VERSION ""

NS_ :

BS_:

BU_: VMCU VGGSECUSystem TECU OBDScanT2 HMIIOM EMS ECUspare2 ECUspare1 DACU CIOM BBM

BO_ 2671835728 XCP_FA_50_BB2: 8 DACU
 SG_ XCP_FA_50 : 0|64@1+ (1,0) [0|0] "" Vector__XXX

BO_ 2671792378 XCP_50_FA_BB2: 8 Vector__XXX
 SG_ XCP_50_FA : 0|64@1+ (1,0) [0|0] ""  DACU

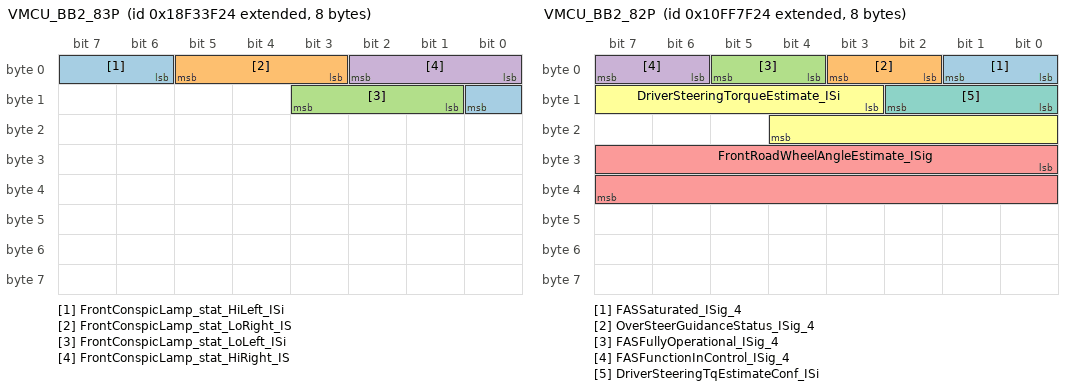
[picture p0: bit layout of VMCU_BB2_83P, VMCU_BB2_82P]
BO_ 2566078244 VMCU_BB2_83P: 8 VMCU
 SG_ FrontConspicLamp_stat_HiLeft_ISi : 6|3@1+ (1,0) [0|0] ""  HMIIOM
 SG_ FrontConspicLamp_stat_LoRight_IS : 3|3@1+ (1,0) [0|0] ""  HMIIOM
 SG_ FrontConspicLamp_stat_LoLeft_ISi : 9|3@1+ (1,0) [0|0] ""  HMIIOM
 SG_ FrontConspicLamp_stat_HiRight_IS : 0|3@1+ (1,0) [0|0] ""  HMIIOM

BO_ 2432663332 VMCU_BB2_82P: 8 VMCU
 SG_ FASSaturated_ISig_4 : 0|2@1+ (1,0) [0|0] ""  DACU
 SG_ OverSteerGuidanceStatus_ISig_4 : 2|2@1+ (1,0) [0|0] ""  HMIIOM
 SG_ FASFullyOperational_ISig_4 : 4|2@1+ (1,0) [0|0] ""  BBM,DACU
 SG_ FASFunctionInControl_ISig_4 : 6|2@1+ (1,0) [0|0] ""  DACU
 SG_ FrontRoadWheelAngleEstimate_ISig : 24|16@1+ (5E-005,-1.6) [-1.6|1.67675] "rad"  DACU
 SG_ DriverSteeringTorqueEstimate_ISi : 11|10@1+ (0.05,-25) [-25|26.15] "Nm"  DACU
 SG_ DriverSteeringTqEstimateConf_ISi : 8|3@1+ (1,0) [0|0] ""  DACU

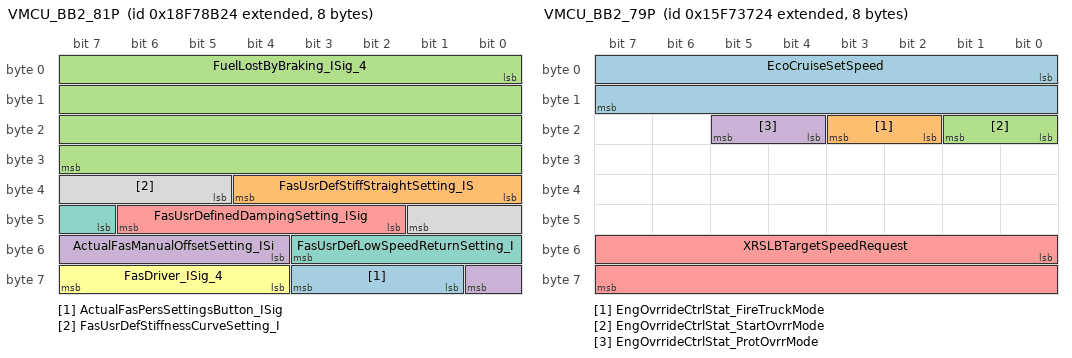
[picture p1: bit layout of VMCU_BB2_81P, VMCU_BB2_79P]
BO_ 2566359844 VMCU_BB2_81P: 8 VMCU
 SG_ ActualFasPersSettingsButton_ISig : 57|3@1+ (1,0) [0|0] ""  HMIIOM
 SG_ FasUsrDefStiffStraightSetting_IS : 32|5@1+ (1,-10) [-10|21] ""  HMIIOM
 SG_ FuelLostByBraking_ISig_4 : 0|32@1+ (0.01,0) [0|42949672.95] "l"  HMIIOM
 SG_ ActualFasManualOffsetSetting_ISi : 52|5@1+ (1,-10) [-10|21] ""  HMIIOM
 SG_ FasUsrDefinedDampingSetting_ISig : 42|5@1+ (1,-10) [-10|21] ""  HMIIOM
 SG_ FasDriver_ISig_4 : 60|4@1+ (1,0) [0|0] ""  HMIIOM
 SG_ FasUsrDefLowSpeedReturnSetting_I : 47|5@1+ (1,-10) [-10|21] ""  HMIIOM
 SG_ FasUsrDefStiffnessCurveSetting_I : 37|5@1+ (1,-10) [-10|21] ""  HMIIOM

BO_ 2481984804 VMCU_BB2_80P: 8 VMCU
 SG_ PS_PosLightDoorOpen_ISig_4 : 10|2@1+ (1,0) [0|0] ""  HMIIOM
 SG_ PS_FogLightRear_ISig_4 : 24|2@1+ (1,0) [0|0] ""  HMIIOM
 SG_ TrailerBodyLampDI_stat : 2|2@1+ (1,0) [0|0] ""  CIOM
 SG_ ParkedLoadDistribution_ISig_4 : 20|3@1+ (1,0) [0|0] ""  HMIIOM
 SG_ PV_HeadLightLevel_ISig_4 : 16|4@1+ (1,-7) [-7|8] "NotApplicable"  HMIIOM
 SG_ TrailerBodyLampFdbk_stat : 0|2@1+ (1,0) [0|0] ""  CIOM
 SG_ PS_FogLightFront_ISig_4 : 26|2@1+ (1,0) [0|0] ""  HMIIOM
 SG_ DriverCrank_rqst_ISig_4 : 12|2@1+ (1,0) [0|0] ""  HMIIOM
 SG_ PS_HeadLightAdjustment_ISig_4 : 8|2@1+ (1,0) [0|0] ""  HMIIOM
 SG_ PS_MainBeam_ISig_4 : 14|2@1+ (1,0) [0|0] ""  HMIIOM
 SG_ FifthWheelHandleLock_ind_ISig_4 : 6|2@1+ (1,0) [0|0] ""  HMIIOM
 SG_ InstFuel_ConsumpValue_ISig_4 : 28|16@1+ (0.01,0) [0|655.35] ""  HMIIOM
 SG_ InstFuel_VehicleMoving_ISig_4 : 44|2@1+ (1,0) [0|0] ""  HMIIOM
 SG_ PS_AFSAllowedInDriveP_ISig_4 : 49|2@1+ (1,0) [0|0] ""  HMIIOM
 SG_ PS_AFS_ISig_4 : 46|3@1+ (1,0) [0|0] ""  HMIIOM
 SG_ AC2CoolingFanControl_rqst : 4|2@1+ (1,0) [0|0] ""  CIOM
 SG_ DHCStatus : 53|2@1+ (1,0) [0|0] ""  HMIIOM
 SG_ PS_PositionLight_ISig_4 : 51|2@1+ (1,0) [0|0] ""  HMIIOM

BO_ 2516006692 VMCU_BB2_79P: 8 VMCU
 SG_ EcoCruiseSetSpeed : 0|16@1+ (0.00390625,0) [0|255.99609375] "Km_per_h"  HMIIOM
 SG_ EngOvrrideCtrlStat_FireTruckMode : 18|2@1+ (1,0) [0|0] ""  EMS
 SG_ EngOvrrideCtrlStat_StartOvrrMode : 16|2@1+ (1,0) [0|0] ""  EMS
 SG_ EngOvrrideCtrlStat_ProtOvrrMode : 20|2@1+ (1,0) [0|0] ""  EMS
 SG_ XRSLBTargetSpeedRequest : 48|16@1+ (0.00390625,0) [0|255.99609375] "Km_per_h"  EMS,TECU

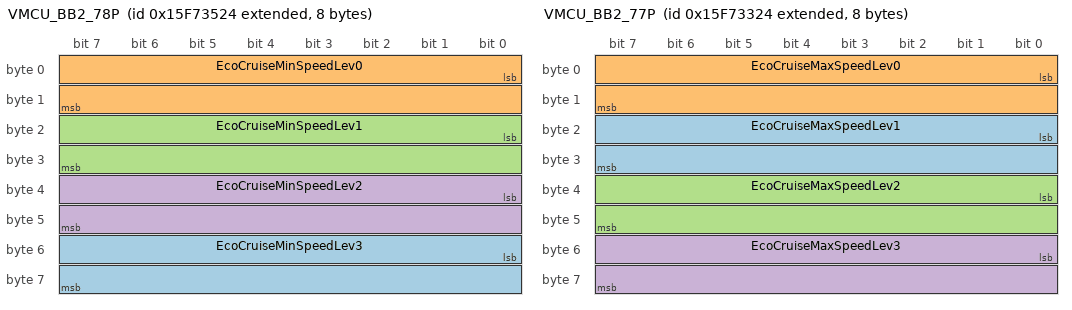
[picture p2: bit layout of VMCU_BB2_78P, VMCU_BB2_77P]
BO_ 2516006180 VMCU_BB2_78P: 8 VMCU
 SG_ EcoCruiseMinSpeedLev3 : 48|16@1+ (0.00390625,0) [0|255.99609375] "Km_per_h"  HMIIOM
 SG_ EcoCruiseMinSpeedLev0 : 0|16@1+ (0.00390625,0) [0|255.99609375] "Km_per_h"  HMIIOM
 SG_ EcoCruiseMinSpeedLev1 : 16|16@1+ (0.00390625,0) [0|255.99609375] "Km_per_h"  HMIIOM
 SG_ EcoCruiseMinSpeedLev2 : 32|16@1+ (0.00390625,0) [0|255.99609375] "Km_per_h"  HMIIOM

BO_ 2516005668 VMCU_BB2_77P: 8 VMCU
 SG_ EcoCruiseMaxSpeedLev1 : 16|16@1+ (0.00390625,0) [0|255.99609375] "Km_per_h"  HMIIOM
 SG_ EcoCruiseMaxSpeedLev0 : 0|16@1+ (0.00390625,0) [0|255.99609375] "Km_per_h"  HMIIOM
 SG_ EcoCruiseMaxSpeedLev2 : 32|16@1+ (0.00390625,0) [0|255.99609375] "Km_per_h"  HMIIOM
 SG_ EcoCruiseMaxSpeedLev3 : 48|16@1+ (0.00390625,0) [0|255.99609375] "Km_per_h"  HMIIOM

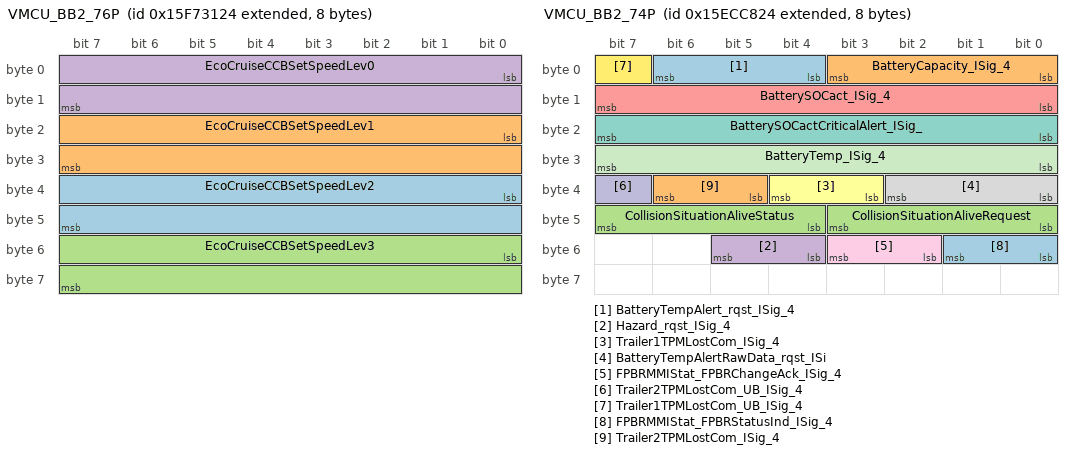
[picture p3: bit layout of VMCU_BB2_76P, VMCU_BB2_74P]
BO_ 2516005156 VMCU_BB2_76P: 8 VMCU
 SG_ EcoCruiseCCBSetSpeedLev2 : 32|16@1+ (0.00390625,0) [0|255.99609375] "Km_per_h"  HMIIOM
 SG_ EcoCruiseCCBSetSpeedLev1 : 16|16@1+ (0.00390625,0) [0|255.99609375] "Km_per_h"  HMIIOM
 SG_ EcoCruiseCCBSetSpeedLev3 : 48|16@1+ (0.00390625,0) [0|255.99609375] "Km_per_h"  HMIIOM
 SG_ EcoCruiseCCBSetSpeedLev0 : 0|16@1+ (0.00390625,0) [0|255.99609375] "Km_per_h"  HMIIOM

BO_ 2566359332 VMCU_BB2_75P: 8 VMCU
 SG_ EngineGreenAreaOutLNG_ISig_4 : 32|32@1+ (0.01,0) [0|42949672.95] "kg"  HMIIOM
 SG_ EngineGreenAreaLNG_ISig_4 : 0|32@1+ (0.01,0) [0|42949672.95] "kg"  HMIIOM

BO_ 2515322916 VMCU_BB2_74P: 8 VMCU
 SG_ BatteryTempAlert_rqst_ISig_4 : 4|3@1+ (1,0) [0|0] ""  HMIIOM
 SG_ BatteryCapacity_ISig_4 : 0|4@1+ (1,0) [0|0] ""  HMIIOM
 SG_ CollisionSituationAliveStatus : 44|4@1+ (1,0) [0|15] "Count"  DACU
 SG_ Hazard_rqst_ISig_4 : 52|2@1+ (1,0) [0|0] ""  HMIIOM
 SG_ BatterySOCact_ISig_4 : 8|8@1+ (0.5,0) [0|127.5] "Percent"  HMIIOM
 SG_ Trailer1TPMLostCom_ISig_4 : 35|2@1+ (1,0) [0|0] ""  HMIIOM
 SG_ BatterySOCactCriticalAlert_ISig_ : 16|8@1+ (0.5,0) [0|127.5] "Percent"  HMIIOM
 SG_ BatteryTempAlertRawData_rqst_ISi : 32|3@1+ (1,0) [0|0] ""  HMIIOM
 SG_ FPBRMMIStat_FPBRChangeAck_ISig_4 : 50|2@1+ (1,0) [0|0] ""  CIOM
 SG_ Trailer2TPMLostCom_UB_ISig_4 : 39|1@1+ (1,0) [0|0] ""  HMIIOM
 SG_ BatteryTemp_ISig_4 : 24|8@1+ (1,-45) [-45|210] "DegreeC"  HMIIOM
 SG_ Trailer1TPMLostCom_UB_ISig_4 : 7|1@1+ (1,0) [0|0] ""  HMIIOM
 SG_ FPBRMMIStat_FPBRStatusInd_ISig_4 : 48|2@1+ (1,0) [0|0] ""  CIOM
 SG_ Trailer2TPMLostCom_ISig_4 : 37|2@1+ (1,0) [0|0] ""  HMIIOM
 SG_ CollisionSituationAliveRequest : 40|4@1+ (1,0) [0|15] "Count"  DACU

BO_ 2515321892 VMCU_BB2_73P: 8 VMCU
 SG_ TPMMateTrailerResp_ISig_4 : 32|3@1+ (1,0) [0|0] ""  HMIIOM
 SG_ Trailer2TPMLeakageWarning_ISig_4 : 19|3@1+ (1,0) [0|0] ""  HMIIOM
 SG_ TPMAutomaticMating_ISig_4 : 30|2@1+ (1,0) [0|0] ""  HMIIOM
 SG_ Trailer2TPMPressureWarning_UB_IS : 55|1@1+ (1,0) [0|0] ""  HMIIOM
 SG_ TruckTPMLeakageWarning_UB_ISig_4 : 56|1@1+ (1,0) [0|0] ""  HMIIOM
 SG_ Trailer2TPMMatedStatus_ISig_4 : 14|2@1+ (1,0) [0|0] ""  HMIIOM
 SG_ Trailer1TPMMatedStatus_ISig_4 : 22|2@1+ (1,0) [0|0] ""  HMIIOM
 SG_ Trailer2TPMLeakageWarning_UB_ISi : 54|1@1+ (1,0) [0|0] ""  HMIIOM
 SG_ Trailer1TPMLeakageWarning_UB_ISi : 52|1@1+ (1,0) [0|0] ""  HMIIOM
 SG_ TruckTPMLeakageWarning_ISig_4 : 11|3@1+ (1,0) [0|0] ""  HMIIOM
 SG_ Trailer1TPMPressureWarning_UB_IS : 53|1@1+ (1,0) [0|0] ""  HMIIOM
 SG_ ExtraSideMarkers_FunctStat : 58|2@1+ (1,0) [0|0] ""  CIOM
 SG_ TruckTPMPressureWarning_UB_ISig_ : 57|1@1+ (1,0) [0|0] ""  HMIIOM
 SG_ Trailer2TPMPressureWarning_ISig_ : 16|3@1+ (1,0) [0|0] ""  HMIIOM
 SG_ TransferCaseNeutral_Ack : 60|2@1+ (1,0) [0|0] ""  CIOM
 SG_ Trailer1TPMPressureWarning_ISig_ : 24|3@1+ (1,0) [0|0] ""  HMIIOM
 SG_ Trailer1TPMLeakageWarning_ISig_4 : 27|3@1+ (1,0) [0|0] ""  HMIIOM
 SG_ LiftAxle1RequestResponse : 35|4@1+ (1,0) [0|0] ""  HMIIOM
 SG_ TruckTPMPressureWarning_ISig_4 : 8|3@1+ (1,0) [0|0] ""  HMIIOM
 SG_ XRSLIndication : 0|8@1+ (1,0) [0|255] "Km_per_h"  BBM,HMIIOM
 SG_ TPMMateTrailerResp_UB_ISig_4 : 39|1@1+ (1,0) [0|0] ""  HMIIOM

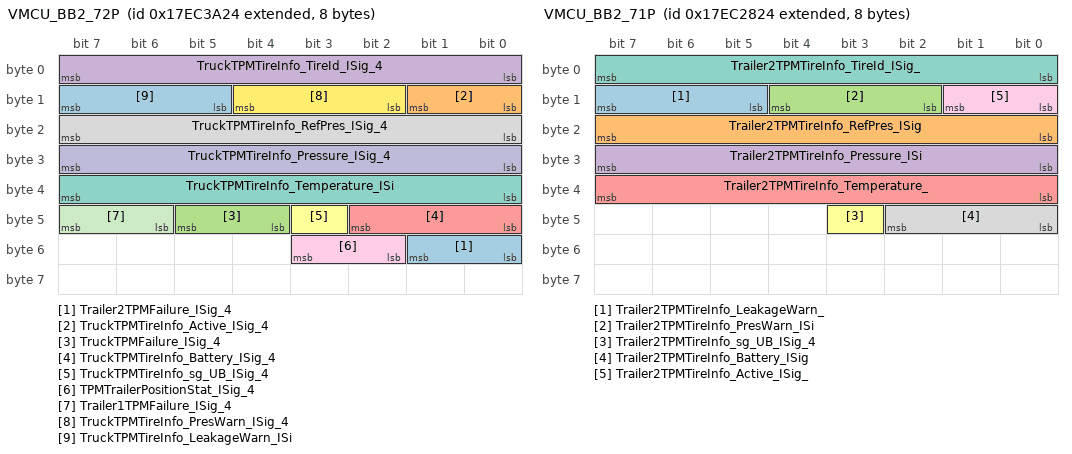
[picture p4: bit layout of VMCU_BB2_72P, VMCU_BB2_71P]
BO_ 2548840996 VMCU_BB2_72P: 8 VMCU
 SG_ Trailer2TPMFailure_ISig_4 : 48|2@1+ (1,0) [0|0] ""  HMIIOM
 SG_ TruckTPMTireInfo_Active_ISig_4 : 8|2@1+ (1,0) [0|0] ""  HMIIOM
 SG_ TruckTPMFailure_ISig_4 : 44|2@1+ (1,0) [0|0] ""  HMIIOM
 SG_ TruckTPMTireInfo_TireId_ISig_4 : 0|8@1+ (1,0) [0|255] "NotApplicable"  HMIIOM
 SG_ TruckTPMTireInfo_Battery_ISig_4 : 40|3@1+ (1,0) [0|0] ""  HMIIOM
 SG_ TruckTPMTireInfo_sg_UB_ISig_4 : 43|1@1+ (1,0) [0|0] ""  HMIIOM
 SG_ TruckTPMTireInfo_Temperature_ISi : 32|8@1+ (1,-50) [-50|205] "DegreeC"  HMIIOM
 SG_ TruckTPMTireInfo_RefPres_ISig_4 : 16|8@1+ (10,0) [0|2550] "kPa"  HMIIOM
 SG_ TPMTrailerPositionStat_ISig_4 : 50|2@1+ (1,0) [0|0] ""  HMIIOM
 SG_ TruckTPMTireInfo_Pressure_ISig_4 : 24|8@1+ (10,0) [0|2550] "kPa"  HMIIOM
 SG_ Trailer1TPMFailure_ISig_4 : 46|2@1+ (1,0) [0|0] ""  HMIIOM
 SG_ TruckTPMTireInfo_PresWarn_ISig_4 : 10|3@1+ (1,0) [0|0] ""  HMIIOM
 SG_ TruckTPMTireInfo_LeakageWarn_ISi : 13|3@1+ (1,0) [0|0] ""  HMIIOM

BO_ 2548836388 VMCU_BB2_71P: 8 VMCU
 SG_ Trailer2TPMTireInfo_LeakageWarn_ : 13|3@1+ (1,0) [0|0] ""  HMIIOM
 SG_ Trailer2TPMTireInfo_RefPres_ISig : 16|8@1+ (10,0) [0|2550] "kPa"  HMIIOM
 SG_ Trailer2TPMTireInfo_PresWarn_ISi : 10|3@1+ (1,0) [0|0] ""  HMIIOM
 SG_ Trailer2TPMTireInfo_Pressure_ISi : 24|8@1+ (10,0) [0|2550] "kPa"  HMIIOM
 SG_ Trailer2TPMTireInfo_Temperature_ : 32|8@1+ (1,-50) [-50|205] "DegreeC"  HMIIOM
 SG_ Trailer2TPMTireInfo_sg_UB_ISig_4 : 43|1@1+ (1,0) [0|0] ""  HMIIOM
 SG_ Trailer2TPMTireInfo_TireId_ISig_ : 0|8@1+ (1,0) [0|255] "NotApplicable"  HMIIOM
 SG_ Trailer2TPMTireInfo_Battery_ISig : 40|3@1+ (1,0) [0|0] ""  HMIIOM
 SG_ Trailer2TPMTireInfo_Active_ISig_ : 8|2@1+ (1,0) [0|0] ""  HMIIOM

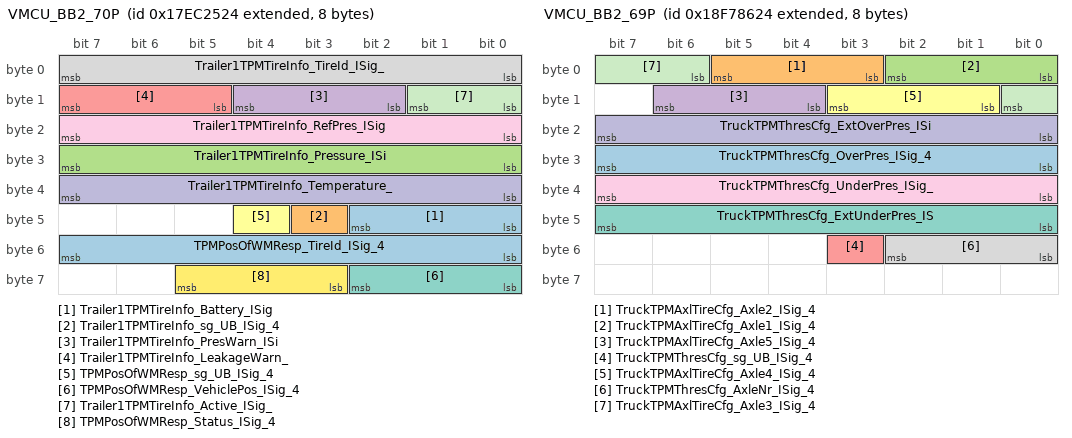
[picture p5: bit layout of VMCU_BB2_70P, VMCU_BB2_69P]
BO_ 2548835620 VMCU_BB2_70P: 8 VMCU
 SG_ Trailer1TPMTireInfo_Battery_ISig : 40|3@1+ (1,0) [0|0] ""  HMIIOM
 SG_ Trailer1TPMTireInfo_sg_UB_ISig_4 : 43|1@1+ (1,0) [0|0] ""  HMIIOM
 SG_ Trailer1TPMTireInfo_Pressure_ISi : 24|8@1+ (10,0) [0|2550] "kPa"  HMIIOM
 SG_ Trailer1TPMTireInfo_PresWarn_ISi : 10|3@1+ (1,0) [0|0] ""  HMIIOM
 SG_ Trailer1TPMTireInfo_LeakageWarn_ : 13|3@1+ (1,0) [0|0] ""  HMIIOM
 SG_ TPMPosOfWMResp_sg_UB_ISig_4 : 44|1@1+ (1,0) [0|0] ""  HMIIOM
 SG_ TPMPosOfWMResp_VehiclePos_ISig_4 : 56|3@1+ (1,0) [0|0] ""  HMIIOM
 SG_ Trailer1TPMTireInfo_TireId_ISig_ : 0|8@1+ (1,0) [0|255] "NotApplicable"  HMIIOM
 SG_ Trailer1TPMTireInfo_RefPres_ISig : 16|8@1+ (10,0) [0|2550] "kPa"  HMIIOM
 SG_ Trailer1TPMTireInfo_Temperature_ : 32|8@1+ (1,-50) [-50|205] "DegreeC"  HMIIOM
 SG_ Trailer1TPMTireInfo_Active_ISig_ : 8|2@1+ (1,0) [0|0] ""  HMIIOM
 SG_ TPMPosOfWMResp_Status_ISig_4 : 59|3@1+ (1,0) [0|0] ""  HMIIOM
 SG_ TPMPosOfWMResp_TireId_ISig_4 : 48|8@1+ (1,0) [0|255] "NotApplicable"  HMIIOM

BO_ 2566358564 VMCU_BB2_69P: 8 VMCU
 SG_ TruckTPMThresCfg_OverPres_ISig_4 : 24|8@1+ (1,-125) [-125|130] "Percent"  HMIIOM
 SG_ TruckTPMAxlTireCfg_Axle2_ISig_4 : 3|3@1+ (1,0) [0|0] ""  HMIIOM
 SG_ TruckTPMAxlTireCfg_Axle1_ISig_4 : 0|3@1+ (1,0) [0|0] ""  HMIIOM
 SG_ TruckTPMAxlTireCfg_Axle5_ISig_4 : 12|3@1+ (1,0) [0|0] ""  HMIIOM
 SG_ TruckTPMThresCfg_sg_UB_ISig_4 : 51|1@1+ (1,0) [0|0] ""  HMIIOM
 SG_ TruckTPMAxlTireCfg_Axle4_ISig_4 : 9|3@1+ (1,0) [0|0] ""  HMIIOM
 SG_ TruckTPMThresCfg_ExtUnderPres_IS : 40|8@1+ (1,-125) [-125|130] "Percent"  HMIIOM
 SG_ TruckTPMThresCfg_AxleNr_ISig_4 : 48|3@1+ (1,0) [0|0] ""  HMIIOM
 SG_ TruckTPMThresCfg_UnderPres_ISig_ : 32|8@1+ (1,-125) [-125|130] "Percent"  HMIIOM
 SG_ TruckTPMThresCfg_ExtOverPres_ISi : 16|8@1+ (1,-125) [-125|130] "Percent"  HMIIOM
 SG_ TruckTPMAxlTireCfg_Axle3_ISig_4 : 6|3@1+ (1,0) [0|0] ""  HMIIOM

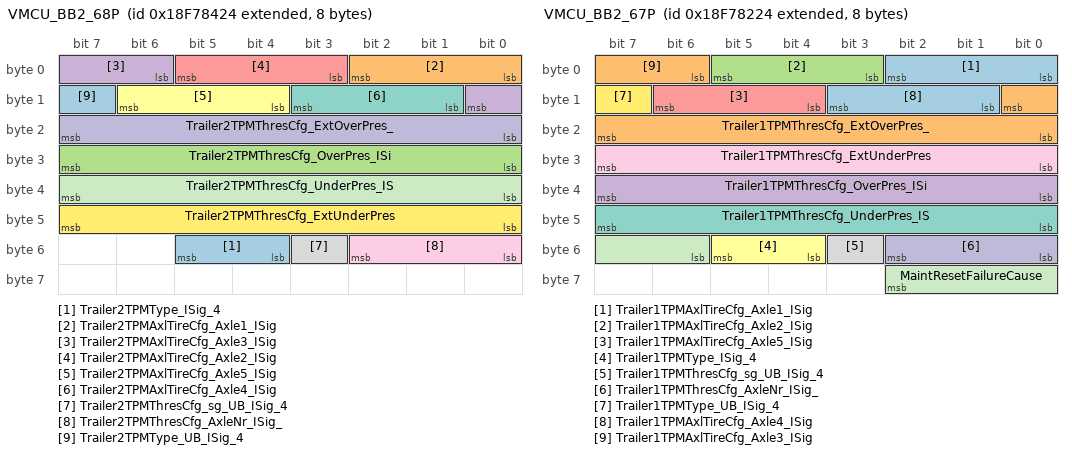
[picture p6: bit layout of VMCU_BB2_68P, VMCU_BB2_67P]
BO_ 2566358052 VMCU_BB2_68P: 8 VMCU
 SG_ Trailer2TPMType_ISig_4 : 52|2@1+ (1,0) [0|0] ""  HMIIOM
 SG_ Trailer2TPMAxlTireCfg_Axle1_ISig : 0|3@1+ (1,0) [0|0] ""  HMIIOM
 SG_ Trailer2TPMThresCfg_OverPres_ISi : 24|8@1+ (1,-125) [-125|130] "Percent"  HMIIOM
 SG_ Trailer2TPMAxlTireCfg_Axle3_ISig : 6|3@1+ (1,0) [0|0] ""  HMIIOM
 SG_ Trailer2TPMAxlTireCfg_Axle2_ISig : 3|3@1+ (1,0) [0|0] ""  HMIIOM
 SG_ Trailer2TPMAxlTireCfg_Axle5_ISig : 12|3@1+ (1,0) [0|0] ""  HMIIOM
 SG_ Trailer2TPMAxlTireCfg_Axle4_ISig : 9|3@1+ (1,0) [0|0] ""  HMIIOM
 SG_ Trailer2TPMThresCfg_sg_UB_ISig_4 : 51|1@1+ (1,0) [0|0] ""  HMIIOM
 SG_ Trailer2TPMThresCfg_AxleNr_ISig_ : 48|3@1+ (1,0) [0|0] ""  HMIIOM
 SG_ Trailer2TPMThresCfg_ExtOverPres_ : 16|8@1+ (1,-125) [-125|130] "Percent"  HMIIOM
 SG_ Trailer2TPMThresCfg_UnderPres_IS : 32|8@1+ (1,-125) [-125|130] "Percent"  HMIIOM
 SG_ Trailer2TPMThresCfg_ExtUnderPres : 40|8@1+ (1,-125) [-125|130] "Percent"  HMIIOM
 SG_ Trailer2TPMType_UB_ISig_4 : 15|1@1+ (1,0) [0|0] ""  HMIIOM

BO_ 2566357540 VMCU_BB2_67P: 8 VMCU
 SG_ Trailer1TPMAxlTireCfg_Axle1_ISig : 0|3@1+ (1,0) [0|0] ""  HMIIOM
 SG_ Trailer1TPMThresCfg_ExtOverPres_ : 16|8@1+ (1,-125) [-125|130] "Percent"  HMIIOM
 SG_ Trailer1TPMAxlTireCfg_Axle2_ISig : 3|3@1+ (1,0) [0|0] ""  HMIIOM
 SG_ Trailer1TPMThresCfg_OverPres_ISi : 32|8@1+ (1,-125) [-125|130] "Percent"  HMIIOM
 SG_ Trailer1TPMAxlTireCfg_Axle5_ISig : 12|3@1+ (1,0) [0|0] ""  HMIIOM
 SG_ Trailer1TPMType_ISig_4 : 52|2@1+ (1,0) [0|0] ""  HMIIOM
 SG_ Trailer1TPMThresCfg_UnderPres_IS : 40|8@1+ (1,-125) [-125|130] "Percent"  HMIIOM
 SG_ Trailer1TPMThresCfg_sg_UB_ISig_4 : 51|1@1+ (1,0) [0|0] ""  HMIIOM
 SG_ Trailer1TPMThresCfg_ExtUnderPres : 24|8@1+ (1,-125) [-125|130] "Percent"  HMIIOM
 SG_ Trailer1TPMThresCfg_AxleNr_ISig_ : 48|3@1+ (1,0) [0|0] ""  HMIIOM
 SG_ MaintResetFailureCause : 54|5@1+ (1,0) [0|0] ""  HMIIOM
 SG_ Trailer1TPMType_UB_ISig_4 : 15|1@1+ (1,0) [0|0] ""  HMIIOM
 SG_ Trailer1TPMAxlTireCfg_Axle4_ISig : 9|3@1+ (1,0) [0|0] ""  HMIIOM
 SG_ Trailer1TPMAxlTireCfg_Axle3_ISig : 6|3@1+ (1,0) [0|0] ""  HMIIOM

BO_ 2566357029 VMCU_BB2_66P_FCM: 8 HMIIOM
 SG_ VMCU_BB2_66P_FCS : 0|64@1+ (1,0) [0|0] ""  VMCU

BO_ 2566357028 VMCU_BB2_66P: 9 VMCU
 SG_ FuseAndRelayFault_ItemNoD2 : 61|7@1+ (1,0) [0|127] ""  HMIIOM
 SG_ FuseAndRelayFault_ItemNoD1 : 54|7@1+ (1,0) [0|127] ""  HMIIOM
 SG_ FuseAndRelayFault_ItemNoC2 : 44|7@1+ (1,0) [0|127] ""  HMIIOM
 SG_ FuseAndRelayFault_ItemNoB2 : 27|7@1+ (1,0) [0|127] ""  HMIIOM
 SG_ FuseAndRelayFault_TypeD : 51|3@1+ (1,0) [0|0] ""  HMIIOM
 SG_ FuseAndRelayFault_TypeB : 17|3@1+ (1,0) [0|0] ""  HMIIOM
 SG_ FuseAndRelayFault_TypeA : 0|3@1+ (1,0) [0|0] ""  HMIIOM
 SG_ FuseAndRelayFault_ItemNoA1 : 3|7@1+ (1,0) [0|127] ""  HMIIOM
 SG_ FuseAndRelayFault_ItemNoA2 : 10|7@1+ (1,0) [0|127] ""  HMIIOM
 SG_ FuseAndRelayFault_ItemNoB1 : 20|7@1+ (1,0) [0|127] ""  HMIIOM
 SG_ FuseAndRelayFault_ItemNoC1 : 37|7@1+ (1,0) [0|127] ""  HMIIOM
 SG_ FuseAndRelayFault_TypeC : 34|3@1+ (1,0) [0|0] ""  HMIIOM

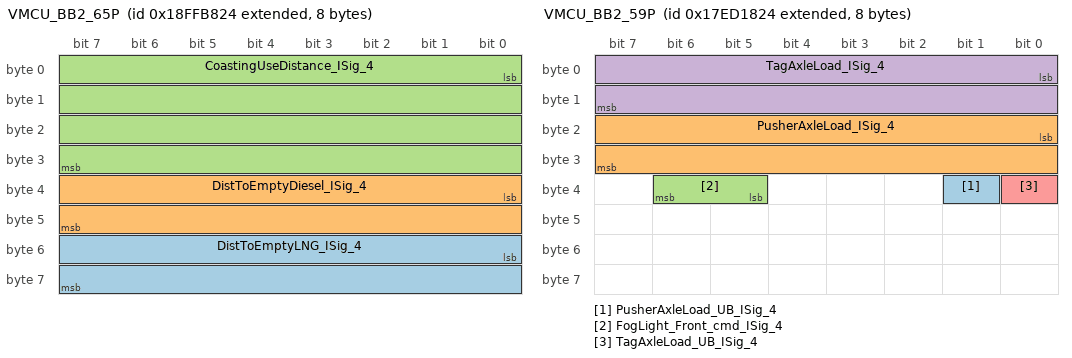
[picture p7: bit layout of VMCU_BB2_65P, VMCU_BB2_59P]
BO_ 2566895652 VMCU_BB2_65P: 8 VMCU
 SG_ DistToEmptyLNG_ISig_4 : 48|16@1+ (1,0) [0|65535] "km"  HMIIOM
 SG_ DistToEmptyDiesel_ISig_4 : 32|16@1+ (1,0) [0|65535] "km"  HMIIOM
 SG_ CoastingUseDistance_ISig_4 : 0|32@1+ (10,0) [0|42949672950] "m"  HMIIOM

BO_ 2566894884 VMCU_BB2_64P: 8 VMCU
 SG_ EngSpeedOverThresholdTime_ISig_4 : 32|32@1+ (1,0) [0|4294967295] "s"  HMIIOM
 SG_ EngLoadOverThresholdDistance_ISi : 0|32@1+ (10,0) [0|42949672950] "m"  HMIIOM

BO_ 2566894372 VMCU_BB2_63P: 8 VMCU
 SG_ EngineGreenAreaFuel_ISig_4 : 32|32@1+ (0.01,0) [0|42949672.95] "l"  HMIIOM
 SG_ LCCDistance_ISig_4 : 0|32@1+ (10,0) [0|42949672950] "m"  HMIIOM

BO_ 2566893604 VMCU_BB2_62P: 8 VMCU
 SG_ StopCounter_ISig_4 : 0|32@1+ (1,0) [0|4294967295] ""  HMIIOM
 SG_ OverspeedDistance_ISig_4 : 32|32@1+ (10,0) [0|42949672950] "m"  HMIIOM

BO_ 2566892580 VMCU_BB2_61P: 8 VMCU
 SG_ RobotizedGboxPowerModeTime_ISig_ : 0|32@1+ (1,0) [0|4294967295] "s"  HMIIOM
 SG_ TotalServiceBrakeCounter_ISig_4 : 32|32@1+ (1,0) [0|4294967295] ""  HMIIOM

BO_ 2566892068 VMCU_BB2_60P: 8 VMCU
 SG_ RobotizedGboxManualModeTime_ISig : 32|32@1+ (1,0) [0|4294967295] "s"  HMIIOM
 SG_ RobotizedGboxAutoModeTime_ISig_4 : 0|32@1+ (1,0) [0|4294967295] "s"  HMIIOM

BO_ 2548897828 VMCU_BB2_59P: 8 VMCU
 SG_ PusherAxleLoad_UB_ISig_4 : 33|1@1+ (1,0) [0|0] ""  TECU,BBM,DACU,HMIIOM
 SG_ PusherAxleLoad_ISig_4 : 16|16@1+ (0.5,0) [0|32767.5] "kg"  HMIIOM,TECU,BBM,DACU
 SG_ FogLight_Front_cmd_ISig_4 : 37|2@1+ (1,0) [0|0] ""  BBM
 SG_ TagAxleLoad_ISig_4 : 0|16@1+ (0.5,0) [0|32767.5] "kg"  TECU,DACU,BBM,HMIIOM
 SG_ TagAxleLoad_UB_ISig_4 : 32|1@1+ (1,0) [0|0] ""  BBM,HMIIOM,DACU,TECU

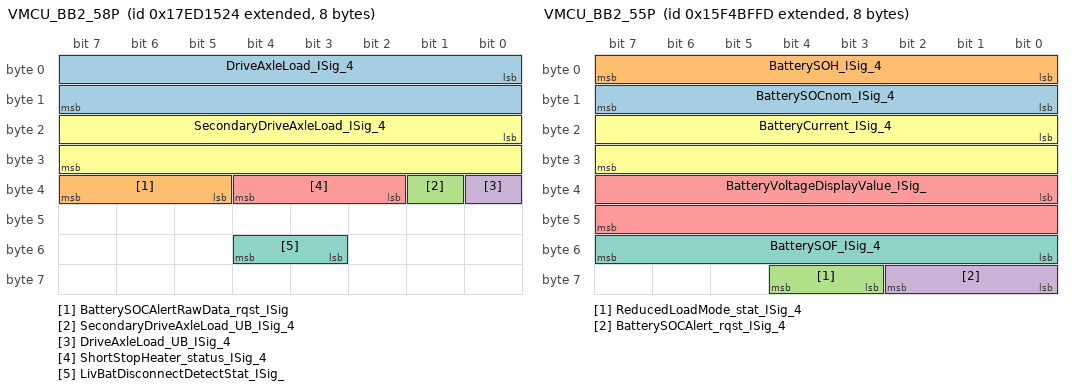
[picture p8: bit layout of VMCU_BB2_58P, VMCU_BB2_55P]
BO_ 2548897060 VMCU_BB2_58P: 8 VMCU
 SG_ DriveAxleLoad_ISig_4 : 0|16@1+ (0.5,0) [0|32767.5] "kg"  BBM,DACU,HMIIOM,TECU
 SG_ BatterySOCAlertRawData_rqst_ISig : 37|3@1+ (1,0) [0|0] ""  CIOM,BBM
 SG_ SecondaryDriveAxleLoad_UB_ISig_4 : 33|1@1+ (1,0) [0|0] ""  HMIIOM,TECU,BBM,DACU
 SG_ DriveAxleLoad_UB_ISig_4 : 32|1@1+ (1,0) [0|0] ""  BBM,HMIIOM,TECU,DACU
 SG_ ShortStopHeater_status_ISig_4 : 34|3@1+ (1,0) [0|0] ""  CIOM
 SG_ SecondaryDriveAxleLoad_ISig_4 : 16|16@1+ (0.5,0) [0|32767.5] "kg"  HMIIOM,DACU,BBM,TECU
 SG_ LivBatDisconnectDetectStat_ISig_ : 51|2@1+ (1,0) [0|0] ""  HMIIOM

BO_ 2566365477 VMCU_BB2_57P_HMIIOM_FCM: 8 HMIIOM
 SG_ VMCU_BB2_57P_FCS_18f7a125 : 0|64@1+ (1,0) [0|0] ""  VMCU

BO_ 2566365476 VMCU_BB2_57P_HMIIOM: 15 VMCU
 SG_ MaintService_ServiceCalendarTime : 32|32@1+ (1,-2147483600) [-2147483600|2147483695] "s"  HMIIOM
 SG_ MaintService_EngTimeID_ISig_4_18 : 112|8@1+ (1,0) [0|255] "ID"  HMIIOM
 SG_ MaintService_DistID_ISig_4_18f7a : 96|8@1+ (1,0) [0|255] "ID"  HMIIOM
 SG_ MaintService_ServiceDistance_ISi : 0|32@1+ (10,-21474836000) [-21474836000|21474836950] "m"  HMIIOM
 SG_ MaintService_ServiceEngineTime_I : 64|32@1+ (1,-2147483600) [-2147483600|2147483695] "s"  HMIIOM
 SG_ MaintService_CalDateID_ISig_4_18 : 104|8@1+ (1,0) [0|255] "ID"  HMIIOM

BO_ 2566357285 VMCU_BB2_57P_FCM: 8 CIOM
 SG_ VMCU_BB2_57P_FCS_18f78125 : 0|64@1+ (1,0) [0|0] ""  VMCU

BO_ 2566357284 VMCU_BB2_57P: 15 VMCU
 SG_ MaintService_ServiceEngineT_0000 : 64|32@1+ (1,-2147483600) [-2147483600|2147483695] "s"  CIOM
 SG_ MaintService_EngTimeID_ISig_0000 : 112|8@1+ (1,0) [0|255] "ID"  CIOM
 SG_ MaintService_DistID_ISig_4_18f78 : 96|8@1+ (1,0) [0|255] "ID"  CIOM
 SG_ MaintService_ServiceDistanc_0000 : 0|32@1+ (10,-21474836000) [-21474836000|21474836950] "m"  CIOM
 SG_ MaintService_CalDateID_ISig_0000 : 104|8@1+ (1,0) [0|255] "ID"  CIOM
 SG_ MaintService_ServiceCalenda_0000 : 32|32@1+ (1,-2147483600) [-2147483600|2147483695] "s"  CIOM

BO_ 2566821202 VMCU_BB2_56P: 8 VMCU
 SG_ EngTrueIdleSpeedTime_ISig_4 : 0|32@1+ (1,0) [0|4294967295] "s"  HMIIOM
 SG_ EngineGreenAreaOutTime_ISig_4 : 32|32@1+ (1,0) [0|4294967295] "s"  HMIIOM

BO_ 2515845117 VMCU_BB2_55P: 8 VMCU
 SG_ BatterySOCnom_ISig_4 : 8|8@1+ (0.5,0) [0|127.5] "Percent"  HMIIOM
 SG_ BatterySOH_ISig_4 : 0|8@1+ (0.5,0) [0|127.5] "Percent"  HMIIOM
 SG_ ReducedLoadMode_stat_ISig_4 : 59|2@1+ (1,0) [0|0] ""  CIOM
 SG_ BatterySOCAlert_rqst_ISig_4 : 56|3@1+ (1,0) [0|0] ""  HMIIOM,BBM,CIOM
 SG_ BatteryVoltageDisplayValue_ISig_ : 32|16@1+ (0.05,0) [0|3276.75] "V"  HMIIOM,BBM
 SG_ BatteryCurrent_ISig_4 : 16|16@1+ (0.05,-1600) [-1600|1676.75] "A"  EMS,HMIIOM
 SG_ BatterySOF_ISig_4 : 48|8@1+ (1,0) [0|255] "h"  HMIIOM

CM_ "COM_MATRIX_1.31.X0";
CM_ BU_ VGGSECUSystem "Describes interfaces used by a couple of ECUs within VGGS system.";
CM_ SG_ 2566359844 FasUsrDefStiffStraightSetting_IS "21-29 spare
30 Error
31 NotAvailbale";
CM_ SG_ 2566359844 FuelLostByBraking_ISig_4 "4261412864 - 4278190079 Error
4278190080 - 4294967295 NotAvailable";
CM_ SG_ 2566359844 ActualFasManualOffsetSetting_ISi "21-29 spare
30 Error
31 NotAvailbale";
CM_ SG_ 2566359844 FasUsrDefinedDampingSetting_ISig "21-29 spare
30 Error
31 NotAvailbale";
CM_ SG_ 2566359844 FasUsrDefLowSpeedReturnSetting_I "21-29 spare
30 Error
31 NotAvailbale";
CM_ SG_ 2566359844 FasUsrDefStiffnessCurveSetting_I "21-29 spare
30 Error
31 NotAvailbale";
CM_ SG_ 2566359332 EngineGreenAreaOutLNG_ISig_4 "4294967295 Not available
";
CM_ SG_ 2566359332 EngineGreenAreaLNG_ISig_4 "4211081216 - 4261412863 Spare
4261412864 - 4278190079 Error
4278190080 - 4294967295 NotAvailable";
CM_ SG_ 2548840996 TruckTPMTireInfo_Temperature_ISi "251-253	Spare; 254 Error; 255 NotAvailable;";
CM_ SG_ 2548840996 TruckTPMTireInfo_RefPres_ISig_4 "251-253 Spare; 254 Error; 255 NotAvailable;";
CM_ SG_ 2548840996 TruckTPMTireInfo_Pressure_ISig_4 "251-253 Spare; 254 Error; 255 NotAvailable;";
CM_ SG_ 2548836388 Trailer2TPMTireInfo_RefPres_ISig "251-253 Spare; 254 Error; 255 NotAvailable;";
CM_ SG_ 2548836388 Trailer2TPMTireInfo_Pressure_ISi "251-253 Spare; 254 Error; 255 NotAvailable;";
CM_ SG_ 2548836388 Trailer2TPMTireInfo_Temperature_ "251-253	Spare; 254 Error; 255 NotAvailable;";
CM_ SG_ 2548835620 Trailer1TPMTireInfo_Pressure_ISi "251-253 Spare; 254 Error; 255 NotAvailable;";
CM_ SG_ 2548835620 Trailer1TPMTireInfo_RefPres_ISig "251-253 Spare; 254 Error; 255 NotAvailable;";
CM_ SG_ 2548835620 Trailer1TPMTireInfo_Temperature_ "251-253	Spare; 254 Error; 255 NotAvailable;";
CM_ SG_ 2566895652 CoastingUseDistance_ISig_4 "4261412864 - 4278190079 Error ; 4278190080 - 4294967295 Not available";
CM_ SG_ 2566894884 EngSpeedOverThresholdTime_ISig_4 "4261412864 - 4278190079 Error ; 4278190080 - 4294967295 Not available";
CM_ SG_ 2566894884 EngLoadOverThresholdDistance_ISi "4261412864 - 4278190079 Error ; 4278190080 - 4294967295 Not available";
CM_ SG_ 2566894372 EngineGreenAreaFuel_ISig_4 "4261412864 - 4278190079 Error ; 4278190080 - 4294967295 Not available";
CM_ SG_ 2566893604 StopCounter_ISig_4 "4261412864 - 4278190079 Error ; 4278190080 - 4294967295 Not available";
CM_ SG_ 2566893604 OverspeedDistance_ISig_4 "4261412864 - 4278190079 Error ; 4278190080 - 4294967295 Not available";
CM_ SG_ 2566892580 RobotizedGboxPowerModeTime_ISig_ "4261412864 - 4278190079 Error ; 4278190080 - 4294967295 Not available";
CM_ SG_ 2566892580 TotalServiceBrakeCounter_ISig_4 "4261412864 - 4278190079 Error ; 4278190080 - 4294967295 Not available";
CM_ SG_ 2566892068 RobotizedGboxManualModeTime_ISig "4261412864 - 4278190079 Error ; 4278190080 - 4294967295 Not available";
CM_ SG_ 2566892068 RobotizedGboxAutoModeTime_ISig_4 "4261412864 - 4278190079 Error ; 4278190080 - 4294967295 Not available";
CM_ SG_ 2548897828 PusherAxleLoad_ISig_4 "65024 - 65279 Error ; 65280 - 65535 Not available";
CM_ SG_ 2548897828 TagAxleLoad_ISig_4 "65024 - 65279 Error ; 65280 - 65535 Not available";
CM_ SG_ 2548897060 DriveAxleLoad_ISig_4 "65024 - 65279 Error ; 65280 - 65535 Not available";
CM_ SG_ 2548897060 SecondaryDriveAxleLoad_ISig_4 "65024 - 65279 Error ; 65280 - 65535 Not available";
CM_ SG_ 2566365476 MaintService_ServiceCalendarTime "4261412864 - 4278190079 Error ; 4278190080 - 4294967295 Not available";
CM_ SG_ 2566365476 MaintService_ServiceDistance_ISi "4261412864 - 4278190079 Error ; 4278190080 - 4294967295 Not Available";
CM_ SG_ 2566365476 MaintService_ServiceEngineTime_I "4261412864 - 4278190079 Error ; 4278190080 - 4294967295 Not available";
CM_ SG_ 2566357284 MaintService_ServiceEngineT_0000 "4261412864 - 4278190079 Error ; 4278190080 - 4294967295 Not available";
CM_ SG_ 2566357284 MaintService_ServiceDistanc_0000 "4261412864 - 4278190079 Error ; 4278190080 - 4294967295 Not Available";
CM_ SG_ 2566357284 MaintService_ServiceCalenda_0000 "4261412864 - 4278190079 Error ; 4278190080 - 4294967295 Not available";
CM_ SG_ 2566821202 EngTrueIdleSpeedTime_ISig_4 "4294967295 Not available";
CM_ SG_ 2566821202 EngineGreenAreaOutTime_ISig_4 "4294967295 Not available";
CM_ SG_ 2515845117 BatterySOCnom_ISig_4 "254 Error ; 255 Not available";
CM_ SG_ 2515845117 BatterySOH_ISig_4 "254 Error ; 255 Not available";
CM_ SG_ 2515845117 BatteryVoltageDisplayValue_ISig_ "65024 - 65279 Error ; 65280 - 65535 Not available";
CM_ SG_ 2515845117 BatteryCurrent_ISig_4 "65024 - 65279 Error ; 65280 - 65535 Not available";
CM_ SG_ 2515845117 BatterySOF_ISig_4 "254 Error ; 255 Not Available";
BA_DEF_ BO_  "GenMsgStartDelayTime" INT 0 0;
BA_DEF_ BO_  "GenMsgDelayTime" INT 0 0;
BA_DEF_ BO_  "GenMsgCycleTime" INT 0 0;
BA_DEF_ BO_  "GenMsgSendType" ENUM  "Cyclic","NotUsed","NotUsed","NotUsed","NotUsed","NotUsed","NotUsed","IfActive","NoMsgSendType","NotUsed";
BA_DEF_ SG_  "GenSigStartValue" INT 0 0;
BA_DEF_ SG_  "GenSigCycleTimeActive" INT 0 0;
BA_DEF_ SG_  "GenSigCycleTime" INT 0 0;
BA_DEF_ SG_  "GenSigSendType" ENUM  "Cyclic","OnWrite","OnWriteWithRepetition","OnChange","OnChangeWithRepetition","IfActive","IfActiveWithRepetition","NoSigSendType","NotUsed","NotUsed","NotUsed","NotUsed","NotUsed";
BA_DEF_  "Baudrate" INT 0 1000000;
BA_DEF_  "BusType" STRING ;
BA_DEF_  "NmType" STRING ;
BA_DEF_  "Manufacturer" STRING ;
BA_DEF_  "VersionYear" INT 0 99;
BA_DEF_  "VersionNumber" INT 0 99;
BA_DEF_  "VersionMonth" INT 1 12;
BA_DEF_  "VersionDay" INT 1 31;
BA_DEF_ BO_  "VFrameFormat" ENUM  "StandardCAN","ExtendedCAN","reserved","J1939PG";
BA_DEF_ BU_  "TpOwnSystemEcuNumber" HEX 0 255;
BA_DEF_ SG_  "SigType" ENUM  "Default","Range","RangeSigned","ASCII","Discrete","Control","ReferencePGN","DTC","StringDelimiter","StringLength","StringLengthControl";
BA_DEF_ SG_  "SeToolVersion_SIGNAL" STRING ;
BA_DEF_ SG_  "SeToolUniqueID_SIGNAL" STRING ;
BA_DEF_ SG_  "SeToolOwnerSigGroup_SIGNAL" STRING ;
BA_DEF_ SG_  "SeToolOwnerSigGroupID_SIGNAL" STRING ;
BA_DEF_ SG_  "SeToolName_SIGNAL" STRING ;
BA_DEF_ SG_  "SeToolItemID_SIGNAL" STRING ;
BA_DEF_ SG_  "SeToolAncestorID_SIGNAL" STRING ;
BA_DEF_ SG_  "Platform_VMCU1_Sig" ENUM  "No","Yes";
BA_DEF_ BU_  "NmStationAddress" INT 0 255;
BA_DEF_  "NmAsrWaitBusSleepTime" INT 0 65535;
BA_DEF_  "NmAsrTimeoutTime" INT 0 65535;
BA_DEF_  "NmAsrRepeatMessageTime" INT 0 65535;
BA_DEF_ BU_  "NmAsrNodeIdentifier" HEX 0 253;
BA_DEF_ BU_  "NmAsrNode" ENUM  "No","Yes";
BA_DEF_  "NmAsrMessageCount" INT 1 256;
BA_DEF_ BO_  "NmAsrMessage" ENUM  "No","Yes";
BA_DEF_  "NmAsrCanMsgCycleTime" INT 0 65535;
BA_DEF_  "NmAsrBaseAddress" HEX 0 536870911;
BA_DEF_ SG_  "NeedsUpdateBit" ENUM  "No","Yes";
BA_DEF_ SG_  "MmAnSignal" ENUM  "No","Yes";
BA_DEF_ BU_  "IsOBDrelevant" ENUM  "No","Yes";
BA_DEF_ SG_  "GenSigMaxLatency" INT 0 65535;
BA_DEF_ SG_  "GenSigILSupport" ENUM  "Yes","No";
BA_DEF_ BO_  "GenMsgRequestable" INT 0 1;
BA_DEF_ BO_  "GenMsgILSupport" ENUM  "No","Yes";
BA_DEF_ BU_  "DiagnosticClientAddress" HEX 0 255;
BA_DEF_ BO_  "DiagUUDTResponse" ENUM  "No","Yes";
BA_DEF_ BO_  "DiagState" ENUM  "No","Yes";
BA_DEF_ BU_  "DiagRole" ENUM  "None","OBDTester","ExternalTester","InternalTester";
BA_DEF_ BO_  "DiagResponse" ENUM  "No","Yes";
BA_DEF_ BO_  "DiagRequest" ENUM  "No","Yes";
BA_DEF_ BO_  "DiagConnection" HEX 0 65535;
BA_DEF_  "DBName" STRING ;
BA_DEF_ BO_  "CanTpSTmin" INT 0 255;
BA_DEF_ BO_  "CanTpFcFrameId" HEX 0 2147483647;
BA_DEF_ BO_  "CanTpBs" INT 0 255;
BA_DEF_ SG_  "SystemSignalLongSymbol" STRING ;
BA_DEF_REL_ BU_SG_REL_  "GenSigTimeoutTime" INT 0 65535;
BA_DEF_REL_ BU_SG_REL_  "GenSigFirstTimeoutTime" INT 0 65535;
BA_DEF_DEF_  "GenMsgStartDelayTime" 0;
BA_DEF_DEF_  "GenMsgDelayTime" 0;
BA_DEF_DEF_  "GenMsgCycleTime" 0;
BA_DEF_DEF_  "GenMsgSendType" "Cyclic";
BA_DEF_DEF_  "GenSigStartValue" 0;
BA_DEF_DEF_  "GenSigCycleTimeActive" 0;
BA_DEF_DEF_  "GenSigCycleTime" 0;
BA_DEF_DEF_  "GenSigSendType" "Cyclic";
BA_DEF_DEF_  "Baudrate" 500000;
BA_DEF_DEF_  "BusType" "";
BA_DEF_DEF_  "NmType" "";
BA_DEF_DEF_  "Manufacturer" "VOLVO_AB";
BA_DEF_DEF_  "VersionYear" 0;
BA_DEF_DEF_  "VersionNumber" 0;
BA_DEF_DEF_  "VersionMonth" 1;
BA_DEF_DEF_  "VersionDay" 1;
BA_DEF_DEF_  "VFrameFormat" "ExtendedCAN";
BA_DEF_DEF_  "TpOwnSystemEcuNumber" 0;
BA_DEF_DEF_  "SigType" "Default";
BA_DEF_DEF_  "SeToolVersion_SIGNAL" "";
BA_DEF_DEF_  "SeToolUniqueID_SIGNAL" "";
BA_DEF_DEF_  "SeToolOwnerSigGroup_SIGNAL" "";
BA_DEF_DEF_  "SeToolOwnerSigGroupID_SIGNAL" "";
BA_DEF_DEF_  "SeToolName_SIGNAL" "";
BA_DEF_DEF_  "SeToolItemID_SIGNAL" "";
BA_DEF_DEF_  "SeToolAncestorID_SIGNAL" "";
BA_DEF_DEF_  "Platform_VMCU1_Sig" "No";
BA_DEF_DEF_  "NmStationAddress" 254;
BA_DEF_DEF_  "NmAsrWaitBusSleepTime" 750;
BA_DEF_DEF_  "NmAsrTimeoutTime" 5000;
BA_DEF_DEF_  "NmAsrRepeatMessageTime" 300;
BA_DEF_DEF_  "NmAsrNodeIdentifier" 0;
BA_DEF_DEF_  "NmAsrNode" "Yes";
BA_DEF_DEF_  "NmAsrMessageCount" 256;
BA_DEF_DEF_  "NmAsrMessage" "No";
BA_DEF_DEF_  "NmAsrCanMsgCycleTime" 200;
BA_DEF_DEF_  "NmAsrBaseAddress" 486506496;
BA_DEF_DEF_  "NeedsUpdateBit" "No";
BA_DEF_DEF_  "MmAnSignal" "No";
BA_DEF_DEF_  "IsOBDrelevant" "No";
BA_DEF_DEF_  "GenSigMaxLatency" 0;
BA_DEF_DEF_  "GenSigILSupport" "Yes";
BA_DEF_DEF_  "GenMsgRequestable" 1;
BA_DEF_DEF_  "GenMsgILSupport" "Yes";
BA_DEF_DEF_  "DiagnosticClientAddress" 0;
BA_DEF_DEF_  "DiagUUDTResponse" "No";
BA_DEF_DEF_  "DiagState" "No";
BA_DEF_DEF_  "DiagRole" "None";
BA_DEF_DEF_  "DiagResponse" "No";
BA_DEF_DEF_  "DiagRequest" "No";
BA_DEF_DEF_  "DiagConnection" 0;
BA_DEF_DEF_  "DBName" "";
BA_DEF_DEF_  "CanTpSTmin" 0;
BA_DEF_DEF_  "CanTpFcFrameId" 2147483647;
BA_DEF_DEF_  "CanTpBs" 255;
BA_DEF_DEF_REL_ "GenSigTimeoutTime" 0;
BA_DEF_DEF_REL_ "GenSigFirstTimeoutTime" 0;
BA_DEF_DEF_  "SystemSignalLongSymbol" "";
BA_ "NmType" "NmAsr";
BA_ "BusType" "CAN";
BA_ "VersionDay" 28;
BA_ "VersionMonth" 2;
BA_ "VersionNumber" 1;
BA_ "VersionYear" 18;
BA_ "DBName" "Backbone2";
BA_ "IsOBDrelevant" BU_ VMCU 1;
BA_ "TpOwnSystemEcuNumber" BU_ VMCU 36;
BA_ "NmAsrNodeIdentifier" BU_ VMCU 36;
BA_ "NmAsrNode" BU_ VGGSECUSystem 0;
BA_ "TpOwnSystemEcuNumber" BU_ TECU 24;
BA_ "NmAsrNodeIdentifier" BU_ TECU 24;
BA_ "DiagRole" BU_ HMIIOM 3;
BA_ "DiagnosticClientAddress" BU_ HMIIOM 243;
BA_ "TpOwnSystemEcuNumber" BU_ HMIIOM 96;
BA_ "NmAsrNodeIdentifier" BU_ HMIIOM 96;
BA_ "IsOBDrelevant" BU_ EMS 1;
BA_ "TpOwnSystemEcuNumber" BU_ EMS 16;
BA_ "NmAsrNodeIdentifier" BU_ EMS 16;
BA_ "TpOwnSystemEcuNumber" BU_ DACU 80;
BA_ "NmAsrNodeIdentifier" BU_ DACU 80;
BA_ "TpOwnSystemEcuNumber" BU_ CIOM 64;
BA_ "NmAsrNodeIdentifier" BU_ CIOM 64;
BA_ "TpOwnSystemEcuNumber" BU_ BBM 230;
BA_ "NmAsrNodeIdentifier" BU_ BBM 230;
BA_ "GenMsgILSupport" BO_ 2671835728 0;
BA_ "GenMsgSendType" BO_ 2671835728 8;
BA_ "GenMsgILSupport" BO_ 2671792378 0;
BA_ "GenMsgCycleTime" BO_ 2566078244 250;
BA_ "GenMsgStartDelayTime" BO_ 2566078244 50;
BA_ "GenMsgCycleTime" BO_ 2432663332 20;
BA_ "GenMsgStartDelayTime" BO_ 2432663332 50;
BA_ "GenMsgCycleTime" BO_ 2566359844 1000;
BA_ "GenMsgStartDelayTime" BO_ 2566359844 25;
BA_ "GenMsgCycleTime" BO_ 2481984804 100;
BA_ "GenMsgCycleTime" BO_ 2516006692 150;
BA_ "GenMsgStartDelayTime" BO_ 2516006692 55;
BA_ "GenMsgCycleTime" BO_ 2516006180 150;
BA_ "GenMsgStartDelayTime" BO_ 2516006180 35;
BA_ "GenMsgCycleTime" BO_ 2516005668 150;
BA_ "GenMsgStartDelayTime" BO_ 2516005668 20;
BA_ "GenMsgCycleTime" BO_ 2516005156 150;
BA_ "GenMsgStartDelayTime" BO_ 2516005156 40;
BA_ "GenMsgCycleTime" BO_ 2566359332 1000;
BA_ "GenMsgStartDelayTime" BO_ 2566359332 360;
BA_ "GenMsgCycleTime" BO_ 2515322916 100;
BA_ "GenMsgCycleTime" BO_ 2515321892 100;
BA_ "GenMsgStartDelayTime" BO_ 2515321892 80;
BA_ "GenMsgCycleTime" BO_ 2548840996 200;
BA_ "GenMsgStartDelayTime" BO_ 2548840996 100;
BA_ "GenMsgCycleTime" BO_ 2548836388 200;
BA_ "GenMsgStartDelayTime" BO_ 2548836388 120;
BA_ "GenMsgCycleTime" BO_ 2548835620 200;
BA_ "GenMsgStartDelayTime" BO_ 2548835620 140;
BA_ "GenMsgCycleTime" BO_ 2566358564 1000;
BA_ "GenMsgStartDelayTime" BO_ 2566358564 280;
BA_ "GenMsgCycleTime" BO_ 2566358052 1000;
BA_ "GenMsgStartDelayTime" BO_ 2566358052 320;
BA_ "GenMsgCycleTime" BO_ 2566357540 1000;
BA_ "GenMsgStartDelayTime" BO_ 2566357540 350;
BA_ "GenMsgILSupport" BO_ 2566357029 0;
BA_ "GenMsgSendType" BO_ 2566357029 8;
BA_ "CanTpFcFrameId" BO_ 2566357028 418873381;
BA_ "GenMsgCycleTime" BO_ 2566357028 1000;
BA_ "GenMsgStartDelayTime" BO_ 2566357028 50;
BA_ "GenMsgCycleTime" BO_ 2566895652 1000;
BA_ "GenMsgStartDelayTime" BO_ 2566895652 345;
BA_ "GenMsgCycleTime" BO_ 2566894884 1000;
BA_ "GenMsgStartDelayTime" BO_ 2566894884 230;
BA_ "GenMsgCycleTime" BO_ 2566894372 1000;
BA_ "GenMsgStartDelayTime" BO_ 2566894372 155;
BA_ "GenMsgCycleTime" BO_ 2566893604 1000;
BA_ "GenMsgStartDelayTime" BO_ 2566893604 110;
BA_ "GenMsgCycleTime" BO_ 2566892580 1000;
BA_ "GenMsgStartDelayTime" BO_ 2566892580 720;
BA_ "GenMsgCycleTime" BO_ 2566892068 1000;
BA_ "GenMsgStartDelayTime" BO_ 2566892068 680;
BA_ "GenMsgCycleTime" BO_ 2548897828 250;
BA_ "GenMsgCycleTime" BO_ 2548897060 250;
BA_ "GenMsgStartDelayTime" BO_ 2548897060 75;
BA_ "GenMsgILSupport" BO_ 2566365477 0;
BA_ "GenMsgSendType" BO_ 2566365477 8;
BA_ "CanTpFcFrameId" BO_ 2566365476 418881829;
BA_ "GenMsgCycleTime" BO_ 2566365476 1000;
BA_ "GenMsgStartDelayTime" BO_ 2566365476 200;
BA_ "GenMsgILSupport" BO_ 2566357285 0;
BA_ "GenMsgSendType" BO_ 2566357285 8;
BA_ "CanTpFcFrameId" BO_ 2566357284 418873637;
BA_ "GenMsgCycleTime" BO_ 2566357284 1000;
BA_ "GenMsgStartDelayTime" BO_ 2566357284 175;
BA_ "GenMsgCycleTime" BO_ 2566821202 1000;
BA_ "GenMsgStartDelayTime" BO_ 2566821202 170;
BA_ "GenMsgCycleTime" BO_ 2515845117 150;
BA_ "GenMsgStartDelayTime" BO_ 2515845117 65;
BA_ "GenSigSendType" SG_ 2671835728 XCP_FA_50 7;
BA_ "GenSigSendType" SG_ 2671792378 XCP_50_FA 7;
BA_ "GenSigCycleTime" SG_ 2566078244 FrontConspicLamp_stat_HiLeft_ISi 100;
BA_ "GenSigCycleTimeActive" SG_ 2566078244 FrontConspicLamp_stat_HiLeft_ISi 100;
BA_ "GenSigStartValue" SG_ 2566078244 FrontConspicLamp_stat_HiLeft_ISi 7;
BA_ "GenSigMaxLatency" SG_ 2566078244 FrontConspicLamp_stat_HiLeft_ISi 259;
BA_ "SystemSignalLongSymbol" SG_ 2566078244 FrontConspicLamp_stat_HiLeft_ISi "FrontConspicLamp_stat_HiLeft_ISig_4";
BA_ "GenSigCycleTime" SG_ 2566078244 FrontConspicLamp_stat_LoRight_IS 100;
BA_ "GenSigCycleTimeActive" SG_ 2566078244 FrontConspicLamp_stat_LoRight_IS 100;
BA_ "GenSigStartValue" SG_ 2566078244 FrontConspicLamp_stat_LoRight_IS 7;
BA_ "GenSigMaxLatency" SG_ 2566078244 FrontConspicLamp_stat_LoRight_IS 259;
BA_ "SystemSignalLongSymbol" SG_ 2566078244 FrontConspicLamp_stat_LoRight_IS "FrontConspicLamp_stat_LoRight_ISig_4";
BA_ "GenSigCycleTime" SG_ 2566078244 FrontConspicLamp_stat_LoLeft_ISi 100;
BA_ "GenSigCycleTimeActive" SG_ 2566078244 FrontConspicLamp_stat_LoLeft_ISi 100;
BA_ "GenSigStartValue" SG_ 2566078244 FrontConspicLamp_stat_LoLeft_ISi 7;
BA_ "GenSigMaxLatency" SG_ 2566078244 FrontConspicLamp_stat_LoLeft_ISi 259;
BA_ "SystemSignalLongSymbol" SG_ 2566078244 FrontConspicLamp_stat_LoLeft_ISi "FrontConspicLamp_stat_LoLeft_ISig_4";
BA_ "GenSigCycleTime" SG_ 2566078244 FrontConspicLamp_stat_HiRight_IS 100;
BA_ "GenSigCycleTimeActive" SG_ 2566078244 FrontConspicLamp_stat_HiRight_IS 100;
BA_ "GenSigStartValue" SG_ 2566078244 FrontConspicLamp_stat_HiRight_IS 7;
BA_ "GenSigMaxLatency" SG_ 2566078244 FrontConspicLamp_stat_HiRight_IS 259;
BA_ "SystemSignalLongSymbol" SG_ 2566078244 FrontConspicLamp_stat_HiRight_IS "FrontConspicLamp_stat_HiRight_ISig_4";
BA_ "GenSigCycleTime" SG_ 2432663332 FASSaturated_ISig_4 100;
BA_ "GenSigCycleTimeActive" SG_ 2432663332 FASSaturated_ISig_4 100;
BA_ "GenSigStartValue" SG_ 2432663332 FASSaturated_ISig_4 3;
BA_ "GenSigMaxLatency" SG_ 2432663332 FASSaturated_ISig_4 27;
BA_ "GenSigCycleTime" SG_ 2432663332 OverSteerGuidanceStatus_ISig_4 100;
BA_ "GenSigCycleTimeActive" SG_ 2432663332 OverSteerGuidanceStatus_ISig_4 100;
BA_ "GenSigStartValue" SG_ 2432663332 OverSteerGuidanceStatus_ISig_4 3;
BA_ "GenSigMaxLatency" SG_ 2432663332 OverSteerGuidanceStatus_ISig_4 27;
BA_ "GenSigCycleTime" SG_ 2432663332 FASFullyOperational_ISig_4 100;
BA_ "GenSigCycleTimeActive" SG_ 2432663332 FASFullyOperational_ISig_4 100;
BA_ "GenSigStartValue" SG_ 2432663332 FASFullyOperational_ISig_4 3;
BA_ "GenSigMaxLatency" SG_ 2432663332 FASFullyOperational_ISig_4 27;
BA_ "GenSigCycleTime" SG_ 2432663332 FASFunctionInControl_ISig_4 100;
BA_ "GenSigCycleTimeActive" SG_ 2432663332 FASFunctionInControl_ISig_4 100;
BA_ "GenSigStartValue" SG_ 2432663332 FASFunctionInControl_ISig_4 3;
BA_ "GenSigMaxLatency" SG_ 2432663332 FASFunctionInControl_ISig_4 27;
BA_ "GenSigCycleTime" SG_ 2432663332 FrontRoadWheelAngleEstimate_ISig 100;
BA_ "GenSigCycleTimeActive" SG_ 2432663332 FrontRoadWheelAngleEstimate_ISig 100;
BA_ "GenSigStartValue" SG_ 2432663332 FrontRoadWheelAngleEstimate_ISig 65535;
BA_ "GenSigMaxLatency" SG_ 2432663332 FrontRoadWheelAngleEstimate_ISig 27;
BA_ "SystemSignalLongSymbol" SG_ 2432663332 FrontRoadWheelAngleEstimate_ISig "FrontRoadWheelAngleEstimate_ISig_4";
BA_ "GenSigCycleTime" SG_ 2432663332 DriverSteeringTorqueEstimate_ISi 100;
BA_ "GenSigCycleTimeActive" SG_ 2432663332 DriverSteeringTorqueEstimate_ISi 100;
BA_ "GenSigStartValue" SG_ 2432663332 DriverSteeringTorqueEstimate_ISi 1023;
BA_ "GenSigMaxLatency" SG_ 2432663332 DriverSteeringTorqueEstimate_ISi 27;
BA_ "SystemSignalLongSymbol" SG_ 2432663332 DriverSteeringTorqueEstimate_ISi "DriverSteeringTorqueEstimate_ISig_4";
BA_ "GenSigCycleTime" SG_ 2432663332 DriverSteeringTqEstimateConf_ISi 100;
BA_ "GenSigCycleTimeActive" SG_ 2432663332 DriverSteeringTqEstimateConf_ISi 100;
BA_ "GenSigStartValue" SG_ 2432663332 DriverSteeringTqEstimateConf_ISi 7;
BA_ "GenSigMaxLatency" SG_ 2432663332 DriverSteeringTqEstimateConf_ISi 27;
BA_ "SystemSignalLongSymbol" SG_ 2432663332 DriverSteeringTqEstimateConf_ISi "DriverSteeringTqEstimateConf_ISig_4";
BA_ "GenSigCycleTime" SG_ 2566359844 ActualFasPersSettingsButton_ISig 100;
BA_ "GenSigCycleTimeActive" SG_ 2566359844 ActualFasPersSettingsButton_ISig 100;
BA_ "GenSigStartValue" SG_ 2566359844 ActualFasPersSettingsButton_ISig 7;
BA_ "SystemSignalLongSymbol" SG_ 2566359844 ActualFasPersSettingsButton_ISig "ActualFasPersSettingsButton_ISig_4";
BA_ "GenSigCycleTime" SG_ 2566359844 FasUsrDefStiffStraightSetting_IS 100;
BA_ "GenSigCycleTimeActive" SG_ 2566359844 FasUsrDefStiffStraightSetting_IS 100;
BA_ "GenSigStartValue" SG_ 2566359844 FasUsrDefStiffStraightSetting_IS 31;
BA_ "SystemSignalLongSymbol" SG_ 2566359844 FasUsrDefStiffStraightSetting_IS "FasUsrDefStiffStraightSetting_ISig_4";
BA_ "GenSigCycleTime" SG_ 2566359844 FuelLostByBraking_ISig_4 100;
BA_ "GenSigCycleTimeActive" SG_ 2566359844 FuelLostByBraking_ISig_4 100;
BA_ "GenSigStartValue" SG_ 2566359844 FuelLostByBraking_ISig_4 4294967295;
BA_ "Platform_VMCU1_Sig" SG_ 2566359844 FuelLostByBraking_ISig_4 1;
BA_ "GenSigCycleTime" SG_ 2566359844 ActualFasManualOffsetSetting_ISi 100;
BA_ "GenSigCycleTimeActive" SG_ 2566359844 ActualFasManualOffsetSetting_ISi 100;
BA_ "GenSigStartValue" SG_ 2566359844 ActualFasManualOffsetSetting_ISi 31;
BA_ "SystemSignalLongSymbol" SG_ 2566359844 ActualFasManualOffsetSetting_ISi "ActualFasManualOffsetSetting_ISig_4";
BA_ "GenSigCycleTime" SG_ 2566359844 FasUsrDefinedDampingSetting_ISig 100;
BA_ "GenSigCycleTimeActive" SG_ 2566359844 FasUsrDefinedDampingSetting_ISig 100;
BA_ "GenSigStartValue" SG_ 2566359844 FasUsrDefinedDampingSetting_ISig 31;
BA_ "SystemSignalLongSymbol" SG_ 2566359844 FasUsrDefinedDampingSetting_ISig "FasUsrDefinedDampingSetting_ISig_4";
BA_ "GenSigCycleTime" SG_ 2566359844 FasDriver_ISig_4 100;
BA_ "GenSigCycleTimeActive" SG_ 2566359844 FasDriver_ISig_4 100;
BA_ "GenSigStartValue" SG_ 2566359844 FasDriver_ISig_4 15;
BA_ "GenSigCycleTime" SG_ 2566359844 FasUsrDefLowSpeedReturnSetting_I 100;
BA_ "GenSigCycleTimeActive" SG_ 2566359844 FasUsrDefLowSpeedReturnSetting_I 100;
BA_ "GenSigStartValue" SG_ 2566359844 FasUsrDefLowSpeedReturnSetting_I 31;
BA_ "SystemSignalLongSymbol" SG_ 2566359844 FasUsrDefLowSpeedReturnSetting_I "FasUsrDefLowSpeedReturnSetting_ISig_4";
BA_ "GenSigCycleTime" SG_ 2566359844 FasUsrDefStiffnessCurveSetting_I 100;
BA_ "GenSigCycleTimeActive" SG_ 2566359844 FasUsrDefStiffnessCurveSetting_I 100;
BA_ "GenSigStartValue" SG_ 2566359844 FasUsrDefStiffnessCurveSetting_I 31;
BA_ "SystemSignalLongSymbol" SG_ 2566359844 FasUsrDefStiffnessCurveSetting_I "FasUsrDefStiffnessCurveSetting_ISig_4";
BA_ "GenSigCycleTime" SG_ 2481984804 PS_PosLightDoorOpen_ISig_4 100;
BA_ "GenSigCycleTimeActive" SG_ 2481984804 PS_PosLightDoorOpen_ISig_4 100;
BA_ "GenSigStartValue" SG_ 2481984804 PS_PosLightDoorOpen_ISig_4 3;
BA_ "Platform_VMCU1_Sig" SG_ 2481984804 PS_PosLightDoorOpen_ISig_4 1;
BA_ "GenSigCycleTime" SG_ 2481984804 PS_FogLightRear_ISig_4 100;
BA_ "GenSigCycleTimeActive" SG_ 2481984804 PS_FogLightRear_ISig_4 100;
BA_ "GenSigStartValue" SG_ 2481984804 PS_FogLightRear_ISig_4 3;
BA_ "Platform_VMCU1_Sig" SG_ 2481984804 PS_FogLightRear_ISig_4 1;
BA_ "GenSigCycleTime" SG_ 2481984804 TrailerBodyLampDI_stat 100;
BA_ "GenSigCycleTimeActive" SG_ 2481984804 TrailerBodyLampDI_stat 100;
BA_ "GenSigStartValue" SG_ 2481984804 TrailerBodyLampDI_stat 3;
BA_ "Platform_VMCU1_Sig" SG_ 2481984804 TrailerBodyLampDI_stat 1;
BA_ "GenSigCycleTime" SG_ 2481984804 ParkedLoadDistribution_ISig_4 100;
BA_ "GenSigCycleTimeActive" SG_ 2481984804 ParkedLoadDistribution_ISig_4 100;
BA_ "GenSigStartValue" SG_ 2481984804 ParkedLoadDistribution_ISig_4 7;
BA_ "Platform_VMCU1_Sig" SG_ 2481984804 ParkedLoadDistribution_ISig_4 1;
BA_ "GenSigCycleTime" SG_ 2481984804 PV_HeadLightLevel_ISig_4 100;
BA_ "GenSigCycleTimeActive" SG_ 2481984804 PV_HeadLightLevel_ISig_4 100;
BA_ "GenSigStartValue" SG_ 2481984804 PV_HeadLightLevel_ISig_4 15;
BA_ "Platform_VMCU1_Sig" SG_ 2481984804 PV_HeadLightLevel_ISig_4 1;
BA_ "GenSigCycleTime" SG_ 2481984804 TrailerBodyLampFdbk_stat 100;
BA_ "GenSigCycleTimeActive" SG_ 2481984804 TrailerBodyLampFdbk_stat 100;
BA_ "GenSigStartValue" SG_ 2481984804 TrailerBodyLampFdbk_stat 3;
BA_ "Platform_VMCU1_Sig" SG_ 2481984804 TrailerBodyLampFdbk_stat 1;
BA_ "GenSigCycleTime" SG_ 2481984804 PS_FogLightFront_ISig_4 100;
BA_ "GenSigCycleTimeActive" SG_ 2481984804 PS_FogLightFront_ISig_4 100;
BA_ "GenSigStartValue" SG_ 2481984804 PS_FogLightFront_ISig_4 3;
BA_ "Platform_VMCU1_Sig" SG_ 2481984804 PS_FogLightFront_ISig_4 1;
BA_ "GenSigCycleTime" SG_ 2481984804 DriverCrank_rqst_ISig_4 100;
BA_ "GenSigCycleTimeActive" SG_ 2481984804 DriverCrank_rqst_ISig_4 100;
BA_ "GenSigStartValue" SG_ 2481984804 DriverCrank_rqst_ISig_4 3;
BA_ "Platform_VMCU1_Sig" SG_ 2481984804 DriverCrank_rqst_ISig_4 1;
BA_ "GenSigCycleTime" SG_ 2481984804 PS_HeadLightAdjustment_ISig_4 100;
BA_ "GenSigCycleTimeActive" SG_ 2481984804 PS_HeadLightAdjustment_ISig_4 100;
BA_ "GenSigStartValue" SG_ 2481984804 PS_HeadLightAdjustment_ISig_4 3;
BA_ "Platform_VMCU1_Sig" SG_ 2481984804 PS_HeadLightAdjustment_ISig_4 1;
BA_ "GenSigCycleTime" SG_ 2481984804 PS_MainBeam_ISig_4 100;
BA_ "GenSigCycleTimeActive" SG_ 2481984804 PS_MainBeam_ISig_4 100;
BA_ "GenSigStartValue" SG_ 2481984804 PS_MainBeam_ISig_4 3;
BA_ "Platform_VMCU1_Sig" SG_ 2481984804 PS_MainBeam_ISig_4 1;
BA_ "GenSigCycleTime" SG_ 2481984804 FifthWheelHandleLock_ind_ISig_4 100;
BA_ "GenSigCycleTimeActive" SG_ 2481984804 FifthWheelHandleLock_ind_ISig_4 100;
BA_ "GenSigStartValue" SG_ 2481984804 FifthWheelHandleLock_ind_ISig_4 3;
BA_ "Platform_VMCU1_Sig" SG_ 2481984804 FifthWheelHandleLock_ind_ISig_4 1;
BA_ "GenSigCycleTime" SG_ 2481984804 InstFuel_ConsumpValue_ISig_4 100;
BA_ "GenSigCycleTimeActive" SG_ 2481984804 InstFuel_ConsumpValue_ISig_4 100;
BA_ "GenSigStartValue" SG_ 2481984804 InstFuel_ConsumpValue_ISig_4 65535;
BA_ "Platform_VMCU1_Sig" SG_ 2481984804 InstFuel_ConsumpValue_ISig_4 1;
BA_ "GenSigCycleTime" SG_ 2481984804 InstFuel_VehicleMoving_ISig_4 100;
BA_ "GenSigCycleTimeActive" SG_ 2481984804 InstFuel_VehicleMoving_ISig_4 100;
BA_ "GenSigStartValue" SG_ 2481984804 InstFuel_VehicleMoving_ISig_4 3;
BA_ "Platform_VMCU1_Sig" SG_ 2481984804 InstFuel_VehicleMoving_ISig_4 1;
BA_ "GenSigCycleTime" SG_ 2481984804 PS_AFSAllowedInDriveP_ISig_4 100;
BA_ "GenSigCycleTimeActive" SG_ 2481984804 PS_AFSAllowedInDriveP_ISig_4 100;
BA_ "GenSigStartValue" SG_ 2481984804 PS_AFSAllowedInDriveP_ISig_4 3;
BA_ "GenSigCycleTime" SG_ 2481984804 PS_AFS_ISig_4 100;
BA_ "GenSigCycleTimeActive" SG_ 2481984804 PS_AFS_ISig_4 100;
BA_ "GenSigStartValue" SG_ 2481984804 PS_AFS_ISig_4 7;
BA_ "GenSigCycleTime" SG_ 2481984804 AC2CoolingFanControl_rqst 100;
BA_ "GenSigCycleTimeActive" SG_ 2481984804 AC2CoolingFanControl_rqst 100;
BA_ "GenSigStartValue" SG_ 2481984804 AC2CoolingFanControl_rqst 3;
BA_ "Platform_VMCU1_Sig" SG_ 2481984804 AC2CoolingFanControl_rqst 1;
BA_ "GenSigCycleTime" SG_ 2481984804 DHCStatus 100;
BA_ "GenSigCycleTimeActive" SG_ 2481984804 DHCStatus 100;
BA_ "GenSigStartValue" SG_ 2481984804 DHCStatus 3;
BA_ "GenSigCycleTime" SG_ 2481984804 PS_PositionLight_ISig_4 100;
BA_ "GenSigCycleTimeActive" SG_ 2481984804 PS_PositionLight_ISig_4 100;
BA_ "GenSigStartValue" SG_ 2481984804 PS_PositionLight_ISig_4 3;
BA_ "GenSigCycleTime" SG_ 2516006692 EcoCruiseSetSpeed 100;
BA_ "GenSigCycleTimeActive" SG_ 2516006692 EcoCruiseSetSpeed 100;
BA_ "GenSigStartValue" SG_ 2516006692 EcoCruiseSetSpeed 65535;
BA_ "Platform_VMCU1_Sig" SG_ 2516006692 EcoCruiseSetSpeed 1;
BA_ "GenSigCycleTime" SG_ 2516006692 EngOvrrideCtrlStat_FireTruckMode 100;
BA_ "GenSigCycleTimeActive" SG_ 2516006692 EngOvrrideCtrlStat_FireTruckMode 100;
BA_ "GenSigStartValue" SG_ 2516006692 EngOvrrideCtrlStat_FireTruckMode 3;
BA_ "Platform_VMCU1_Sig" SG_ 2516006692 EngOvrrideCtrlStat_FireTruckMode 1;
BA_ "GenSigCycleTime" SG_ 2516006692 EngOvrrideCtrlStat_StartOvrrMode 100;
BA_ "GenSigCycleTimeActive" SG_ 2516006692 EngOvrrideCtrlStat_StartOvrrMode 100;
BA_ "GenSigStartValue" SG_ 2516006692 EngOvrrideCtrlStat_StartOvrrMode 3;
BA_ "Platform_VMCU1_Sig" SG_ 2516006692 EngOvrrideCtrlStat_StartOvrrMode 1;
BA_ "GenSigCycleTime" SG_ 2516006692 EngOvrrideCtrlStat_ProtOvrrMode 100;
BA_ "GenSigCycleTimeActive" SG_ 2516006692 EngOvrrideCtrlStat_ProtOvrrMode 100;
BA_ "GenSigStartValue" SG_ 2516006692 EngOvrrideCtrlStat_ProtOvrrMode 3;
BA_ "Platform_VMCU1_Sig" SG_ 2516006692 EngOvrrideCtrlStat_ProtOvrrMode 1;
BA_ "GenSigCycleTime" SG_ 2516006692 XRSLBTargetSpeedRequest 100;
BA_ "GenSigCycleTimeActive" SG_ 2516006692 XRSLBTargetSpeedRequest 100;
BA_ "GenSigStartValue" SG_ 2516006692 XRSLBTargetSpeedRequest 65535;
BA_ "GenSigCycleTime" SG_ 2516006180 EcoCruiseMinSpeedLev3 100;
BA_ "GenSigCycleTimeActive" SG_ 2516006180 EcoCruiseMinSpeedLev3 100;
BA_ "GenSigStartValue" SG_ 2516006180 EcoCruiseMinSpeedLev3 65535;
BA_ "Platform_VMCU1_Sig" SG_ 2516006180 EcoCruiseMinSpeedLev3 1;
BA_ "GenSigCycleTime" SG_ 2516006180 EcoCruiseMinSpeedLev0 100;
BA_ "GenSigCycleTimeActive" SG_ 2516006180 EcoCruiseMinSpeedLev0 100;
BA_ "GenSigStartValue" SG_ 2516006180 EcoCruiseMinSpeedLev0 65535;
BA_ "Platform_VMCU1_Sig" SG_ 2516006180 EcoCruiseMinSpeedLev0 1;
BA_ "GenSigCycleTime" SG_ 2516006180 EcoCruiseMinSpeedLev1 100;
BA_ "GenSigCycleTimeActive" SG_ 2516006180 EcoCruiseMinSpeedLev1 100;
BA_ "GenSigStartValue" SG_ 2516006180 EcoCruiseMinSpeedLev1 65535;
BA_ "Platform_VMCU1_Sig" SG_ 2516006180 EcoCruiseMinSpeedLev1 1;
BA_ "GenSigCycleTime" SG_ 2516006180 EcoCruiseMinSpeedLev2 100;
BA_ "GenSigCycleTimeActive" SG_ 2516006180 EcoCruiseMinSpeedLev2 100;
BA_ "GenSigStartValue" SG_ 2516006180 EcoCruiseMinSpeedLev2 65535;
BA_ "Platform_VMCU1_Sig" SG_ 2516006180 EcoCruiseMinSpeedLev2 1;
BA_ "GenSigCycleTime" SG_ 2516005668 EcoCruiseMaxSpeedLev1 100;
BA_ "GenSigCycleTimeActive" SG_ 2516005668 EcoCruiseMaxSpeedLev1 100;
BA_ "GenSigStartValue" SG_ 2516005668 EcoCruiseMaxSpeedLev1 65535;
BA_ "Platform_VMCU1_Sig" SG_ 2516005668 EcoCruiseMaxSpeedLev1 1;
BA_ "GenSigCycleTime" SG_ 2516005668 EcoCruiseMaxSpeedLev0 100;
BA_ "GenSigCycleTimeActive" SG_ 2516005668 EcoCruiseMaxSpeedLev0 100;
BA_ "GenSigStartValue" SG_ 2516005668 EcoCruiseMaxSpeedLev0 65535;
BA_ "Platform_VMCU1_Sig" SG_ 2516005668 EcoCruiseMaxSpeedLev0 1;
BA_ "GenSigCycleTime" SG_ 2516005668 EcoCruiseMaxSpeedLev2 100;
BA_ "GenSigCycleTimeActive" SG_ 2516005668 EcoCruiseMaxSpeedLev2 100;
BA_ "GenSigStartValue" SG_ 2516005668 EcoCruiseMaxSpeedLev2 65535;
BA_ "Platform_VMCU1_Sig" SG_ 2516005668 EcoCruiseMaxSpeedLev2 1;
BA_ "GenSigCycleTime" SG_ 2516005668 EcoCruiseMaxSpeedLev3 100;
BA_ "GenSigCycleTimeActive" SG_ 2516005668 EcoCruiseMaxSpeedLev3 100;
BA_ "GenSigStartValue" SG_ 2516005668 EcoCruiseMaxSpeedLev3 65535;
BA_ "Platform_VMCU1_Sig" SG_ 2516005668 EcoCruiseMaxSpeedLev3 1;
BA_ "GenSigCycleTime" SG_ 2516005156 EcoCruiseCCBSetSpeedLev2 100;
BA_ "GenSigCycleTimeActive" SG_ 2516005156 EcoCruiseCCBSetSpeedLev2 100;
BA_ "GenSigStartValue" SG_ 2516005156 EcoCruiseCCBSetSpeedLev2 65535;
BA_ "Platform_VMCU1_Sig" SG_ 2516005156 EcoCruiseCCBSetSpeedLev2 1;
BA_ "GenSigCycleTime" SG_ 2516005156 EcoCruiseCCBSetSpeedLev1 100;
BA_ "GenSigCycleTimeActive" SG_ 2516005156 EcoCruiseCCBSetSpeedLev1 100;
BA_ "GenSigStartValue" SG_ 2516005156 EcoCruiseCCBSetSpeedLev1 65535;
BA_ "Platform_VMCU1_Sig" SG_ 2516005156 EcoCruiseCCBSetSpeedLev1 1;
BA_ "GenSigCycleTime" SG_ 2516005156 EcoCruiseCCBSetSpeedLev3 100;
BA_ "GenSigCycleTimeActive" SG_ 2516005156 EcoCruiseCCBSetSpeedLev3 100;
BA_ "GenSigStartValue" SG_ 2516005156 EcoCruiseCCBSetSpeedLev3 65535;
BA_ "Platform_VMCU1_Sig" SG_ 2516005156 EcoCruiseCCBSetSpeedLev3 1;
BA_ "GenSigCycleTime" SG_ 2516005156 EcoCruiseCCBSetSpeedLev0 100;
BA_ "GenSigCycleTimeActive" SG_ 2516005156 EcoCruiseCCBSetSpeedLev0 100;
BA_ "GenSigStartValue" SG_ 2516005156 EcoCruiseCCBSetSpeedLev0 65535;
BA_ "Platform_VMCU1_Sig" SG_ 2516005156 EcoCruiseCCBSetSpeedLev0 1;
BA_ "GenSigCycleTime" SG_ 2566359332 EngineGreenAreaOutLNG_ISig_4 100;
BA_ "GenSigCycleTimeActive" SG_ 2566359332 EngineGreenAreaOutLNG_ISig_4 100;
BA_ "GenSigStartValue" SG_ 2566359332 EngineGreenAreaOutLNG_ISig_4 4294967295;
BA_ "Platform_VMCU1_Sig" SG_ 2566359332 EngineGreenAreaOutLNG_ISig_4 1;
BA_ "GenSigCycleTime" SG_ 2566359332 EngineGreenAreaLNG_ISig_4 100;
BA_ "GenSigCycleTimeActive" SG_ 2566359332 EngineGreenAreaLNG_ISig_4 100;
BA_ "GenSigStartValue" SG_ 2566359332 EngineGreenAreaLNG_ISig_4 4294967295;
BA_ "Platform_VMCU1_Sig" SG_ 2566359332 EngineGreenAreaLNG_ISig_4 1;
BA_ "GenSigCycleTime" SG_ 2515322916 BatteryTempAlert_rqst_ISig_4 100;
BA_ "GenSigCycleTimeActive" SG_ 2515322916 BatteryTempAlert_rqst_ISig_4 100;
BA_ "GenSigStartValue" SG_ 2515322916 BatteryTempAlert_rqst_ISig_4 7;
BA_ "Platform_VMCU1_Sig" SG_ 2515322916 BatteryTempAlert_rqst_ISig_4 1;
BA_ "GenSigCycleTime" SG_ 2515322916 BatteryCapacity_ISig_4 100;
BA_ "GenSigCycleTimeActive" SG_ 2515322916 BatteryCapacity_ISig_4 100;
BA_ "GenSigStartValue" SG_ 2515322916 BatteryCapacity_ISig_4 15;
BA_ "Platform_VMCU1_Sig" SG_ 2515322916 BatteryCapacity_ISig_4 1;
BA_ "GenSigCycleTime" SG_ 2515322916 CollisionSituationAliveStatus 100;
BA_ "GenSigCycleTimeActive" SG_ 2515322916 CollisionSituationAliveStatus 100;
BA_ "GenSigStartValue" SG_ 2515322916 CollisionSituationAliveStatus 15;
BA_ "Platform_VMCU1_Sig" SG_ 2515322916 CollisionSituationAliveStatus 1;
BA_ "GenSigCycleTime" SG_ 2515322916 Hazard_rqst_ISig_4 100;
BA_ "GenSigCycleTimeActive" SG_ 2515322916 Hazard_rqst_ISig_4 100;
BA_ "GenSigStartValue" SG_ 2515322916 Hazard_rqst_ISig_4 3;
BA_ "SeToolAncestorID_SIGNAL" SG_ 2515322916 Hazard_rqst_ISig_4 "x0000001D04134A95";
BA_ "SeToolItemID_SIGNAL" SG_ 2515322916 Hazard_rqst_ISig_4 "x0000001D04134A95";
BA_ "SeToolName_SIGNAL" SG_ 2515322916 Hazard_rqst_ISig_4 "Hazard_rqst";
BA_ "SeToolVersion_SIGNAL" SG_ 2515322916 Hazard_rqst_ISig_4 "1";
BA_ "GenSigCycleTime" SG_ 2515322916 BatterySOCact_ISig_4 100;
BA_ "GenSigCycleTimeActive" SG_ 2515322916 BatterySOCact_ISig_4 100;
BA_ "GenSigStartValue" SG_ 2515322916 BatterySOCact_ISig_4 255;
BA_ "Platform_VMCU1_Sig" SG_ 2515322916 BatterySOCact_ISig_4 1;
BA_ "GenSigCycleTime" SG_ 2515322916 Trailer1TPMLostCom_ISig_4 100;
BA_ "GenSigCycleTimeActive" SG_ 2515322916 Trailer1TPMLostCom_ISig_4 100;
BA_ "GenSigStartValue" SG_ 2515322916 Trailer1TPMLostCom_ISig_4 3;
BA_ "NeedsUpdateBit" SG_ 2515322916 Trailer1TPMLostCom_ISig_4 1;
BA_ "Platform_VMCU1_Sig" SG_ 2515322916 Trailer1TPMLostCom_ISig_4 1;
BA_ "GenSigCycleTime" SG_ 2515322916 BatterySOCactCriticalAlert_ISig_ 100;
BA_ "GenSigCycleTimeActive" SG_ 2515322916 BatterySOCactCriticalAlert_ISig_ 100;
BA_ "GenSigStartValue" SG_ 2515322916 BatterySOCactCriticalAlert_ISig_ 255;
BA_ "Platform_VMCU1_Sig" SG_ 2515322916 BatterySOCactCriticalAlert_ISig_ 1;
BA_ "SystemSignalLongSymbol" SG_ 2515322916 BatterySOCactCriticalAlert_ISig_ "BatterySOCactCriticalAlert_ISig_4";
BA_ "GenSigCycleTime" SG_ 2515322916 BatteryTempAlertRawData_rqst_ISi 100;
BA_ "GenSigCycleTimeActive" SG_ 2515322916 BatteryTempAlertRawData_rqst_ISi 100;
BA_ "GenSigStartValue" SG_ 2515322916 BatteryTempAlertRawData_rqst_ISi 7;
BA_ "Platform_VMCU1_Sig" SG_ 2515322916 BatteryTempAlertRawData_rqst_ISi 1;
BA_ "SystemSignalLongSymbol" SG_ 2515322916 BatteryTempAlertRawData_rqst_ISi "BatteryTempAlertRawData_rqst_ISig_4";
BA_ "GenSigCycleTime" SG_ 2515322916 FPBRMMIStat_FPBRChangeAck_ISig_4 100;
BA_ "GenSigCycleTimeActive" SG_ 2515322916 FPBRMMIStat_FPBRChangeAck_ISig_4 100;
BA_ "GenSigStartValue" SG_ 2515322916 FPBRMMIStat_FPBRChangeAck_ISig_4 3;
BA_ "Platform_VMCU1_Sig" SG_ 2515322916 FPBRMMIStat_FPBRChangeAck_ISig_4 1;
BA_ "GenSigSendType" SG_ 2515322916 Trailer2TPMLostCom_UB_ISig_4 7;
BA_ "GenSigCycleTime" SG_ 2515322916 Trailer2TPMLostCom_UB_ISig_4 100;
BA_ "GenSigCycleTimeActive" SG_ 2515322916 Trailer2TPMLostCom_UB_ISig_4 100;
BA_ "Platform_VMCU1_Sig" SG_ 2515322916 Trailer2TPMLostCom_UB_ISig_4 1;
BA_ "GenSigCycleTime" SG_ 2515322916 BatteryTemp_ISig_4 100;
BA_ "GenSigCycleTimeActive" SG_ 2515322916 BatteryTemp_ISig_4 100;
BA_ "GenSigStartValue" SG_ 2515322916 BatteryTemp_ISig_4 255;
BA_ "Platform_VMCU1_Sig" SG_ 2515322916 BatteryTemp_ISig_4 1;
BA_ "GenSigSendType" SG_ 2515322916 Trailer1TPMLostCom_UB_ISig_4 7;
BA_ "GenSigCycleTime" SG_ 2515322916 Trailer1TPMLostCom_UB_ISig_4 100;
BA_ "GenSigCycleTimeActive" SG_ 2515322916 Trailer1TPMLostCom_UB_ISig_4 100;
BA_ "Platform_VMCU1_Sig" SG_ 2515322916 Trailer1TPMLostCom_UB_ISig_4 1;
BA_ "GenSigCycleTime" SG_ 2515322916 FPBRMMIStat_FPBRStatusInd_ISig_4 100;
BA_ "GenSigCycleTimeActive" SG_ 2515322916 FPBRMMIStat_FPBRStatusInd_ISig_4 100;
BA_ "GenSigStartValue" SG_ 2515322916 FPBRMMIStat_FPBRStatusInd_ISig_4 3;
BA_ "Platform_VMCU1_Sig" SG_ 2515322916 FPBRMMIStat_FPBRStatusInd_ISig_4 1;
BA_ "GenSigCycleTime" SG_ 2515322916 Trailer2TPMLostCom_ISig_4 100;
BA_ "GenSigCycleTimeActive" SG_ 2515322916 Trailer2TPMLostCom_ISig_4 100;
BA_ "GenSigStartValue" SG_ 2515322916 Trailer2TPMLostCom_ISig_4 3;
BA_ "NeedsUpdateBit" SG_ 2515322916 Trailer2TPMLostCom_ISig_4 1;
BA_ "Platform_VMCU1_Sig" SG_ 2515322916 Trailer2TPMLostCom_ISig_4 1;
BA_ "GenSigCycleTime" SG_ 2515322916 CollisionSituationAliveRequest 100;
BA_ "GenSigCycleTimeActive" SG_ 2515322916 CollisionSituationAliveRequest 100;
BA_ "GenSigStartValue" SG_ 2515322916 CollisionSituationAliveRequest 15;
BA_ "Platform_VMCU1_Sig" SG_ 2515322916 CollisionSituationAliveRequest 1;
BA_ "GenSigCycleTime" SG_ 2515321892 TPMMateTrailerResp_ISig_4 100;
BA_ "GenSigCycleTimeActive" SG_ 2515321892 TPMMateTrailerResp_ISig_4 100;
BA_ "GenSigStartValue" SG_ 2515321892 TPMMateTrailerResp_ISig_4 7;
BA_ "NeedsUpdateBit" SG_ 2515321892 TPMMateTrailerResp_ISig_4 1;
BA_ "Platform_VMCU1_Sig" SG_ 2515321892 TPMMateTrailerResp_ISig_4 1;
BA_ "GenSigCycleTime" SG_ 2515321892 Trailer2TPMLeakageWarning_ISig_4 100;
BA_ "GenSigCycleTimeActive" SG_ 2515321892 Trailer2TPMLeakageWarning_ISig_4 100;
BA_ "GenSigStartValue" SG_ 2515321892 Trailer2TPMLeakageWarning_ISig_4 7;
BA_ "NeedsUpdateBit" SG_ 2515321892 Trailer2TPMLeakageWarning_ISig_4 1;
BA_ "Platform_VMCU1_Sig" SG_ 2515321892 Trailer2TPMLeakageWarning_ISig_4 1;
BA_ "GenSigCycleTime" SG_ 2515321892 TPMAutomaticMating_ISig_4 100;
BA_ "GenSigCycleTimeActive" SG_ 2515321892 TPMAutomaticMating_ISig_4 100;
BA_ "GenSigStartValue" SG_ 2515321892 TPMAutomaticMating_ISig_4 3;
BA_ "Platform_VMCU1_Sig" SG_ 2515321892 TPMAutomaticMating_ISig_4 1;
BA_ "GenSigSendType" SG_ 2515321892 Trailer2TPMPressureWarning_UB_IS 7;
BA_ "GenSigCycleTime" SG_ 2515321892 Trailer2TPMPressureWarning_UB_IS 100;
BA_ "GenSigCycleTimeActive" SG_ 2515321892 Trailer2TPMPressureWarning_UB_IS 100;
BA_ "Platform_VMCU1_Sig" SG_ 2515321892 Trailer2TPMPressureWarning_UB_IS 1;
BA_ "SystemSignalLongSymbol" SG_ 2515321892 Trailer2TPMPressureWarning_UB_IS "Trailer2TPMPressureWarning_UB_ISig_4";
BA_ "GenSigSendType" SG_ 2515321892 TruckTPMLeakageWarning_UB_ISig_4 7;
BA_ "GenSigCycleTime" SG_ 2515321892 TruckTPMLeakageWarning_UB_ISig_4 100;
BA_ "GenSigCycleTimeActive" SG_ 2515321892 TruckTPMLeakageWarning_UB_ISig_4 100;
BA_ "Platform_VMCU1_Sig" SG_ 2515321892 TruckTPMLeakageWarning_UB_ISig_4 1;
BA_ "GenSigCycleTime" SG_ 2515321892 Trailer2TPMMatedStatus_ISig_4 100;
BA_ "GenSigCycleTimeActive" SG_ 2515321892 Trailer2TPMMatedStatus_ISig_4 100;
BA_ "GenSigStartValue" SG_ 2515321892 Trailer2TPMMatedStatus_ISig_4 3;
BA_ "Platform_VMCU1_Sig" SG_ 2515321892 Trailer2TPMMatedStatus_ISig_4 1;
BA_ "GenSigCycleTime" SG_ 2515321892 Trailer1TPMMatedStatus_ISig_4 100;
BA_ "GenSigCycleTimeActive" SG_ 2515321892 Trailer1TPMMatedStatus_ISig_4 100;
BA_ "GenSigStartValue" SG_ 2515321892 Trailer1TPMMatedStatus_ISig_4 3;
BA_ "Platform_VMCU1_Sig" SG_ 2515321892 Trailer1TPMMatedStatus_ISig_4 1;
BA_ "GenSigSendType" SG_ 2515321892 Trailer2TPMLeakageWarning_UB_ISi 7;
BA_ "GenSigCycleTime" SG_ 2515321892 Trailer2TPMLeakageWarning_UB_ISi 100;
BA_ "GenSigCycleTimeActive" SG_ 2515321892 Trailer2TPMLeakageWarning_UB_ISi 100;
BA_ "Platform_VMCU1_Sig" SG_ 2515321892 Trailer2TPMLeakageWarning_UB_ISi 1;
BA_ "SystemSignalLongSymbol" SG_ 2515321892 Trailer2TPMLeakageWarning_UB_ISi "Trailer2TPMLeakageWarning_UB_ISig_4";
BA_ "GenSigSendType" SG_ 2515321892 Trailer1TPMLeakageWarning_UB_ISi 7;
BA_ "GenSigCycleTime" SG_ 2515321892 Trailer1TPMLeakageWarning_UB_ISi 100;
BA_ "GenSigCycleTimeActive" SG_ 2515321892 Trailer1TPMLeakageWarning_UB_ISi 100;
BA_ "Platform_VMCU1_Sig" SG_ 2515321892 Trailer1TPMLeakageWarning_UB_ISi 1;
BA_ "SystemSignalLongSymbol" SG_ 2515321892 Trailer1TPMLeakageWarning_UB_ISi "Trailer1TPMLeakageWarning_UB_ISig_4";
BA_ "GenSigCycleTime" SG_ 2515321892 TruckTPMLeakageWarning_ISig_4 100;
BA_ "GenSigCycleTimeActive" SG_ 2515321892 TruckTPMLeakageWarning_ISig_4 100;
BA_ "GenSigStartValue" SG_ 2515321892 TruckTPMLeakageWarning_ISig_4 7;
BA_ "NeedsUpdateBit" SG_ 2515321892 TruckTPMLeakageWarning_ISig_4 1;
BA_ "Platform_VMCU1_Sig" SG_ 2515321892 TruckTPMLeakageWarning_ISig_4 1;
BA_ "GenSigSendType" SG_ 2515321892 Trailer1TPMPressureWarning_UB_IS 7;
BA_ "GenSigCycleTime" SG_ 2515321892 Trailer1TPMPressureWarning_UB_IS 100;
BA_ "GenSigCycleTimeActive" SG_ 2515321892 Trailer1TPMPressureWarning_UB_IS 100;
BA_ "Platform_VMCU1_Sig" SG_ 2515321892 Trailer1TPMPressureWarning_UB_IS 1;
BA_ "SystemSignalLongSymbol" SG_ 2515321892 Trailer1TPMPressureWarning_UB_IS "Trailer1TPMPressureWarning_UB_ISig_4";
BA_ "GenSigCycleTime" SG_ 2515321892 ExtraSideMarkers_FunctStat 100;
BA_ "GenSigCycleTimeActive" SG_ 2515321892 ExtraSideMarkers_FunctStat 100;
BA_ "GenSigStartValue" SG_ 2515321892 ExtraSideMarkers_FunctStat 3;
BA_ "Platform_VMCU1_Sig" SG_ 2515321892 ExtraSideMarkers_FunctStat 1;
BA_ "GenSigSendType" SG_ 2515321892 TruckTPMPressureWarning_UB_ISig_ 7;
BA_ "GenSigCycleTime" SG_ 2515321892 TruckTPMPressureWarning_UB_ISig_ 100;
BA_ "GenSigCycleTimeActive" SG_ 2515321892 TruckTPMPressureWarning_UB_ISig_ 100;
BA_ "Platform_VMCU1_Sig" SG_ 2515321892 TruckTPMPressureWarning_UB_ISig_ 1;
BA_ "SystemSignalLongSymbol" SG_ 2515321892 TruckTPMPressureWarning_UB_ISig_ "TruckTPMPressureWarning_UB_ISig_4";
BA_ "GenSigCycleTime" SG_ 2515321892 Trailer2TPMPressureWarning_ISig_ 100;
BA_ "GenSigCycleTimeActive" SG_ 2515321892 Trailer2TPMPressureWarning_ISig_ 100;
BA_ "GenSigStartValue" SG_ 2515321892 Trailer2TPMPressureWarning_ISig_ 7;
BA_ "NeedsUpdateBit" SG_ 2515321892 Trailer2TPMPressureWarning_ISig_ 1;
BA_ "Platform_VMCU1_Sig" SG_ 2515321892 Trailer2TPMPressureWarning_ISig_ 1;
BA_ "SystemSignalLongSymbol" SG_ 2515321892 Trailer2TPMPressureWarning_ISig_ "Trailer2TPMPressureWarning_ISig_4";
BA_ "GenSigCycleTime" SG_ 2515321892 TransferCaseNeutral_Ack 100;
BA_ "GenSigCycleTimeActive" SG_ 2515321892 TransferCaseNeutral_Ack 100;
BA_ "GenSigStartValue" SG_ 2515321892 TransferCaseNeutral_Ack 3;
BA_ "Platform_VMCU1_Sig" SG_ 2515321892 TransferCaseNeutral_Ack 1;
BA_ "GenSigCycleTime" SG_ 2515321892 Trailer1TPMPressureWarning_ISig_ 100;
BA_ "GenSigCycleTimeActive" SG_ 2515321892 Trailer1TPMPressureWarning_ISig_ 100;
BA_ "GenSigStartValue" SG_ 2515321892 Trailer1TPMPressureWarning_ISig_ 7;
BA_ "NeedsUpdateBit" SG_ 2515321892 Trailer1TPMPressureWarning_ISig_ 1;
BA_ "Platform_VMCU1_Sig" SG_ 2515321892 Trailer1TPMPressureWarning_ISig_ 1;
BA_ "SystemSignalLongSymbol" SG_ 2515321892 Trailer1TPMPressureWarning_ISig_ "Trailer1TPMPressureWarning_ISig_4";
BA_ "GenSigCycleTime" SG_ 2515321892 Trailer1TPMLeakageWarning_ISig_4 100;
BA_ "GenSigCycleTimeActive" SG_ 2515321892 Trailer1TPMLeakageWarning_ISig_4 100;
BA_ "GenSigStartValue" SG_ 2515321892 Trailer1TPMLeakageWarning_ISig_4 7;
BA_ "NeedsUpdateBit" SG_ 2515321892 Trailer1TPMLeakageWarning_ISig_4 1;
BA_ "Platform_VMCU1_Sig" SG_ 2515321892 Trailer1TPMLeakageWarning_ISig_4 1;
BA_ "GenSigCycleTime" SG_ 2515321892 LiftAxle1RequestResponse 100;
BA_ "GenSigCycleTimeActive" SG_ 2515321892 LiftAxle1RequestResponse 100;
BA_ "GenSigStartValue" SG_ 2515321892 LiftAxle1RequestResponse 15;
BA_ "Platform_VMCU1_Sig" SG_ 2515321892 LiftAxle1RequestResponse 1;
BA_ "GenSigCycleTime" SG_ 2515321892 TruckTPMPressureWarning_ISig_4 100;
BA_ "GenSigCycleTimeActive" SG_ 2515321892 TruckTPMPressureWarning_ISig_4 100;
BA_ "GenSigStartValue" SG_ 2515321892 TruckTPMPressureWarning_ISig_4 7;
BA_ "NeedsUpdateBit" SG_ 2515321892 TruckTPMPressureWarning_ISig_4 1;
BA_ "Platform_VMCU1_Sig" SG_ 2515321892 TruckTPMPressureWarning_ISig_4 1;
BA_ "GenSigCycleTime" SG_ 2515321892 XRSLIndication 100;
BA_ "GenSigCycleTimeActive" SG_ 2515321892 XRSLIndication 100;
BA_ "GenSigStartValue" SG_ 2515321892 XRSLIndication 255;
BA_ "Platform_VMCU1_Sig" SG_ 2515321892 XRSLIndication 1;
BA_ "GenSigSendType" SG_ 2515321892 TPMMateTrailerResp_UB_ISig_4 7;
BA_ "GenSigCycleTime" SG_ 2515321892 TPMMateTrailerResp_UB_ISig_4 100;
BA_ "GenSigCycleTimeActive" SG_ 2515321892 TPMMateTrailerResp_UB_ISig_4 100;
BA_ "Platform_VMCU1_Sig" SG_ 2515321892 TPMMateTrailerResp_UB_ISig_4 1;
BA_ "GenSigCycleTime" SG_ 2548840996 Trailer2TPMFailure_ISig_4 100;
BA_ "GenSigCycleTimeActive" SG_ 2548840996 Trailer2TPMFailure_ISig_4 100;
BA_ "GenSigStartValue" SG_ 2548840996 Trailer2TPMFailure_ISig_4 3;
BA_ "Platform_VMCU1_Sig" SG_ 2548840996 Trailer2TPMFailure_ISig_4 1;
BA_ "GenSigCycleTime" SG_ 2548840996 TruckTPMTireInfo_Active_ISig_4 100;
BA_ "GenSigCycleTimeActive" SG_ 2548840996 TruckTPMTireInfo_Active_ISig_4 100;
BA_ "GenSigStartValue" SG_ 2548840996 TruckTPMTireInfo_Active_ISig_4 3;
BA_ "NeedsUpdateBit" SG_ 2548840996 TruckTPMTireInfo_Active_ISig_4 1;
BA_ "Platform_VMCU1_Sig" SG_ 2548840996 TruckTPMTireInfo_Active_ISig_4 1;
BA_ "GenSigCycleTime" SG_ 2548840996 TruckTPMFailure_ISig_4 100;
BA_ "GenSigCycleTimeActive" SG_ 2548840996 TruckTPMFailure_ISig_4 100;
BA_ "GenSigStartValue" SG_ 2548840996 TruckTPMFailure_ISig_4 3;
BA_ "Platform_VMCU1_Sig" SG_ 2548840996 TruckTPMFailure_ISig_4 1;
BA_ "GenSigCycleTime" SG_ 2548840996 TruckTPMTireInfo_TireId_ISig_4 100;
BA_ "GenSigCycleTimeActive" SG_ 2548840996 TruckTPMTireInfo_TireId_ISig_4 100;
BA_ "NeedsUpdateBit" SG_ 2548840996 TruckTPMTireInfo_TireId_ISig_4 1;
BA_ "Platform_VMCU1_Sig" SG_ 2548840996 TruckTPMTireInfo_TireId_ISig_4 1;
BA_ "GenSigCycleTime" SG_ 2548840996 TruckTPMTireInfo_Battery_ISig_4 100;
BA_ "GenSigCycleTimeActive" SG_ 2548840996 TruckTPMTireInfo_Battery_ISig_4 100;
BA_ "GenSigStartValue" SG_ 2548840996 TruckTPMTireInfo_Battery_ISig_4 7;
BA_ "NeedsUpdateBit" SG_ 2548840996 TruckTPMTireInfo_Battery_ISig_4 1;
BA_ "Platform_VMCU1_Sig" SG_ 2548840996 TruckTPMTireInfo_Battery_ISig_4 1;
BA_ "GenSigSendType" SG_ 2548840996 TruckTPMTireInfo_sg_UB_ISig_4 7;
BA_ "GenSigCycleTime" SG_ 2548840996 TruckTPMTireInfo_sg_UB_ISig_4 100;
BA_ "GenSigCycleTimeActive" SG_ 2548840996 TruckTPMTireInfo_sg_UB_ISig_4 100;
BA_ "Platform_VMCU1_Sig" SG_ 2548840996 TruckTPMTireInfo_sg_UB_ISig_4 1;
BA_ "GenSigCycleTime" SG_ 2548840996 TruckTPMTireInfo_Temperature_ISi 100;
BA_ "GenSigCycleTimeActive" SG_ 2548840996 TruckTPMTireInfo_Temperature_ISi 100;
BA_ "GenSigStartValue" SG_ 2548840996 TruckTPMTireInfo_Temperature_ISi 255;
BA_ "NeedsUpdateBit" SG_ 2548840996 TruckTPMTireInfo_Temperature_ISi 1;
BA_ "Platform_VMCU1_Sig" SG_ 2548840996 TruckTPMTireInfo_Temperature_ISi 1;
BA_ "SystemSignalLongSymbol" SG_ 2548840996 TruckTPMTireInfo_Temperature_ISi "TruckTPMTireInfo_Temperature_ISig_4";
BA_ "GenSigCycleTime" SG_ 2548840996 TruckTPMTireInfo_RefPres_ISig_4 100;
BA_ "GenSigCycleTimeActive" SG_ 2548840996 TruckTPMTireInfo_RefPres_ISig_4 100;
BA_ "GenSigStartValue" SG_ 2548840996 TruckTPMTireInfo_RefPres_ISig_4 255;
BA_ "NeedsUpdateBit" SG_ 2548840996 TruckTPMTireInfo_RefPres_ISig_4 1;
BA_ "Platform_VMCU1_Sig" SG_ 2548840996 TruckTPMTireInfo_RefPres_ISig_4 1;
BA_ "GenSigCycleTime" SG_ 2548840996 TPMTrailerPositionStat_ISig_4 100;
BA_ "GenSigCycleTimeActive" SG_ 2548840996 TPMTrailerPositionStat_ISig_4 100;
BA_ "GenSigStartValue" SG_ 2548840996 TPMTrailerPositionStat_ISig_4 3;
BA_ "Platform_VMCU1_Sig" SG_ 2548840996 TPMTrailerPositionStat_ISig_4 1;
BA_ "GenSigCycleTime" SG_ 2548840996 TruckTPMTireInfo_Pressure_ISig_4 100;
BA_ "GenSigCycleTimeActive" SG_ 2548840996 TruckTPMTireInfo_Pressure_ISig_4 100;
BA_ "GenSigStartValue" SG_ 2548840996 TruckTPMTireInfo_Pressure_ISig_4 255;
BA_ "NeedsUpdateBit" SG_ 2548840996 TruckTPMTireInfo_Pressure_ISig_4 1;
BA_ "Platform_VMCU1_Sig" SG_ 2548840996 TruckTPMTireInfo_Pressure_ISig_4 1;
BA_ "GenSigCycleTime" SG_ 2548840996 Trailer1TPMFailure_ISig_4 100;
BA_ "GenSigCycleTimeActive" SG_ 2548840996 Trailer1TPMFailure_ISig_4 100;
BA_ "GenSigStartValue" SG_ 2548840996 Trailer1TPMFailure_ISig_4 3;
BA_ "Platform_VMCU1_Sig" SG_ 2548840996 Trailer1TPMFailure_ISig_4 1;
BA_ "GenSigCycleTime" SG_ 2548840996 TruckTPMTireInfo_PresWarn_ISig_4 100;
BA_ "GenSigCycleTimeActive" SG_ 2548840996 TruckTPMTireInfo_PresWarn_ISig_4 100;
BA_ "GenSigStartValue" SG_ 2548840996 TruckTPMTireInfo_PresWarn_ISig_4 7;
BA_ "NeedsUpdateBit" SG_ 2548840996 TruckTPMTireInfo_PresWarn_ISig_4 1;
BA_ "Platform_VMCU1_Sig" SG_ 2548840996 TruckTPMTireInfo_PresWarn_ISig_4 1;
BA_ "GenSigCycleTime" SG_ 2548840996 TruckTPMTireInfo_LeakageWarn_ISi 100;
BA_ "GenSigCycleTimeActive" SG_ 2548840996 TruckTPMTireInfo_LeakageWarn_ISi 100;
BA_ "GenSigStartValue" SG_ 2548840996 TruckTPMTireInfo_LeakageWarn_ISi 7;
BA_ "NeedsUpdateBit" SG_ 2548840996 TruckTPMTireInfo_LeakageWarn_ISi 1;
BA_ "Platform_VMCU1_Sig" SG_ 2548840996 TruckTPMTireInfo_LeakageWarn_ISi 1;
BA_ "SystemSignalLongSymbol" SG_ 2548840996 TruckTPMTireInfo_LeakageWarn_ISi "TruckTPMTireInfo_LeakageWarn_ISig_4";
BA_ "GenSigCycleTime" SG_ 2548836388 Trailer2TPMTireInfo_LeakageWarn_ 100;
BA_ "GenSigCycleTimeActive" SG_ 2548836388 Trailer2TPMTireInfo_LeakageWarn_ 100;
BA_ "GenSigStartValue" SG_ 2548836388 Trailer2TPMTireInfo_LeakageWarn_ 7;
BA_ "NeedsUpdateBit" SG_ 2548836388 Trailer2TPMTireInfo_LeakageWarn_ 1;
BA_ "Platform_VMCU1_Sig" SG_ 2548836388 Trailer2TPMTireInfo_LeakageWarn_ 1;
BA_ "SystemSignalLongSymbol" SG_ 2548836388 Trailer2TPMTireInfo_LeakageWarn_ "Trailer2TPMTireInfo_LeakageWarn_ISig_4";
BA_ "GenSigCycleTime" SG_ 2548836388 Trailer2TPMTireInfo_RefPres_ISig 100;
BA_ "GenSigCycleTimeActive" SG_ 2548836388 Trailer2TPMTireInfo_RefPres_ISig 100;
BA_ "GenSigStartValue" SG_ 2548836388 Trailer2TPMTireInfo_RefPres_ISig 255;
BA_ "NeedsUpdateBit" SG_ 2548836388 Trailer2TPMTireInfo_RefPres_ISig 1;
BA_ "Platform_VMCU1_Sig" SG_ 2548836388 Trailer2TPMTireInfo_RefPres_ISig 1;
BA_ "SystemSignalLongSymbol" SG_ 2548836388 Trailer2TPMTireInfo_RefPres_ISig "Trailer2TPMTireInfo_RefPres_ISig_4";
BA_ "GenSigCycleTime" SG_ 2548836388 Trailer2TPMTireInfo_PresWarn_ISi 100;
BA_ "GenSigCycleTimeActive" SG_ 2548836388 Trailer2TPMTireInfo_PresWarn_ISi 100;
BA_ "GenSigStartValue" SG_ 2548836388 Trailer2TPMTireInfo_PresWarn_ISi 7;
BA_ "NeedsUpdateBit" SG_ 2548836388 Trailer2TPMTireInfo_PresWarn_ISi 1;
BA_ "Platform_VMCU1_Sig" SG_ 2548836388 Trailer2TPMTireInfo_PresWarn_ISi 1;
BA_ "SystemSignalLongSymbol" SG_ 2548836388 Trailer2TPMTireInfo_PresWarn_ISi "Trailer2TPMTireInfo_PresWarn_ISig_4";
BA_ "GenSigCycleTime" SG_ 2548836388 Trailer2TPMTireInfo_Pressure_ISi 100;
BA_ "GenSigCycleTimeActive" SG_ 2548836388 Trailer2TPMTireInfo_Pressure_ISi 100;
BA_ "GenSigStartValue" SG_ 2548836388 Trailer2TPMTireInfo_Pressure_ISi 255;
BA_ "NeedsUpdateBit" SG_ 2548836388 Trailer2TPMTireInfo_Pressure_ISi 1;
BA_ "Platform_VMCU1_Sig" SG_ 2548836388 Trailer2TPMTireInfo_Pressure_ISi 1;
BA_ "SystemSignalLongSymbol" SG_ 2548836388 Trailer2TPMTireInfo_Pressure_ISi "Trailer2TPMTireInfo_Pressure_ISig_4";
BA_ "GenSigCycleTime" SG_ 2548836388 Trailer2TPMTireInfo_Temperature_ 100;
BA_ "GenSigCycleTimeActive" SG_ 2548836388 Trailer2TPMTireInfo_Temperature_ 100;
BA_ "GenSigStartValue" SG_ 2548836388 Trailer2TPMTireInfo_Temperature_ 255;
BA_ "NeedsUpdateBit" SG_ 2548836388 Trailer2TPMTireInfo_Temperature_ 1;
BA_ "Platform_VMCU1_Sig" SG_ 2548836388 Trailer2TPMTireInfo_Temperature_ 1;
BA_ "SystemSignalLongSymbol" SG_ 2548836388 Trailer2TPMTireInfo_Temperature_ "Trailer2TPMTireInfo_Temperature_ISig_4";
BA_ "GenSigSendType" SG_ 2548836388 Trailer2TPMTireInfo_sg_UB_ISig_4 7;
BA_ "GenSigCycleTime" SG_ 2548836388 Trailer2TPMTireInfo_sg_UB_ISig_4 100;
BA_ "GenSigCycleTimeActive" SG_ 2548836388 Trailer2TPMTireInfo_sg_UB_ISig_4 100;
BA_ "Platform_VMCU1_Sig" SG_ 2548836388 Trailer2TPMTireInfo_sg_UB_ISig_4 1;
BA_ "GenSigCycleTime" SG_ 2548836388 Trailer2TPMTireInfo_TireId_ISig_ 100;
BA_ "GenSigCycleTimeActive" SG_ 2548836388 Trailer2TPMTireInfo_TireId_ISig_ 100;
BA_ "NeedsUpdateBit" SG_ 2548836388 Trailer2TPMTireInfo_TireId_ISig_ 1;
BA_ "Platform_VMCU1_Sig" SG_ 2548836388 Trailer2TPMTireInfo_TireId_ISig_ 1;
BA_ "SystemSignalLongSymbol" SG_ 2548836388 Trailer2TPMTireInfo_TireId_ISig_ "Trailer2TPMTireInfo_TireId_ISig_4";
BA_ "GenSigCycleTime" SG_ 2548836388 Trailer2TPMTireInfo_Battery_ISig 100;
BA_ "GenSigCycleTimeActive" SG_ 2548836388 Trailer2TPMTireInfo_Battery_ISig 100;
BA_ "GenSigStartValue" SG_ 2548836388 Trailer2TPMTireInfo_Battery_ISig 7;
BA_ "NeedsUpdateBit" SG_ 2548836388 Trailer2TPMTireInfo_Battery_ISig 1;
BA_ "Platform_VMCU1_Sig" SG_ 2548836388 Trailer2TPMTireInfo_Battery_ISig 1;
BA_ "SystemSignalLongSymbol" SG_ 2548836388 Trailer2TPMTireInfo_Battery_ISig "Trailer2TPMTireInfo_Battery_ISig_4";
BA_ "GenSigCycleTime" SG_ 2548836388 Trailer2TPMTireInfo_Active_ISig_ 100;
BA_ "GenSigCycleTimeActive" SG_ 2548836388 Trailer2TPMTireInfo_Active_ISig_ 100;
BA_ "GenSigStartValue" SG_ 2548836388 Trailer2TPMTireInfo_Active_ISig_ 3;
BA_ "NeedsUpdateBit" SG_ 2548836388 Trailer2TPMTireInfo_Active_ISig_ 1;
BA_ "Platform_VMCU1_Sig" SG_ 2548836388 Trailer2TPMTireInfo_Active_ISig_ 1;
BA_ "SystemSignalLongSymbol" SG_ 2548836388 Trailer2TPMTireInfo_Active_ISig_ "Trailer2TPMTireInfo_Active_ISig_4";
BA_ "GenSigCycleTime" SG_ 2548835620 Trailer1TPMTireInfo_Battery_ISig 100;
BA_ "GenSigCycleTimeActive" SG_ 2548835620 Trailer1TPMTireInfo_Battery_ISig 100;
BA_ "GenSigStartValue" SG_ 2548835620 Trailer1TPMTireInfo_Battery_ISig 7;
BA_ "NeedsUpdateBit" SG_ 2548835620 Trailer1TPMTireInfo_Battery_ISig 1;
BA_ "Platform_VMCU1_Sig" SG_ 2548835620 Trailer1TPMTireInfo_Battery_ISig 1;
BA_ "SystemSignalLongSymbol" SG_ 2548835620 Trailer1TPMTireInfo_Battery_ISig "Trailer1TPMTireInfo_Battery_ISig_4";
BA_ "GenSigSendType" SG_ 2548835620 Trailer1TPMTireInfo_sg_UB_ISig_4 7;
BA_ "GenSigCycleTime" SG_ 2548835620 Trailer1TPMTireInfo_sg_UB_ISig_4 100;
BA_ "GenSigCycleTimeActive" SG_ 2548835620 Trailer1TPMTireInfo_sg_UB_ISig_4 100;
BA_ "Platform_VMCU1_Sig" SG_ 2548835620 Trailer1TPMTireInfo_sg_UB_ISig_4 1;
BA_ "GenSigCycleTime" SG_ 2548835620 Trailer1TPMTireInfo_Pressure_ISi 100;
BA_ "GenSigCycleTimeActive" SG_ 2548835620 Trailer1TPMTireInfo_Pressure_ISi 100;
BA_ "GenSigStartValue" SG_ 2548835620 Trailer1TPMTireInfo_Pressure_ISi 255;
BA_ "NeedsUpdateBit" SG_ 2548835620 Trailer1TPMTireInfo_Pressure_ISi 1;
BA_ "Platform_VMCU1_Sig" SG_ 2548835620 Trailer1TPMTireInfo_Pressure_ISi 1;
BA_ "SystemSignalLongSymbol" SG_ 2548835620 Trailer1TPMTireInfo_Pressure_ISi "Trailer1TPMTireInfo_Pressure_ISig_4";
BA_ "GenSigCycleTime" SG_ 2548835620 Trailer1TPMTireInfo_PresWarn_ISi 100;
BA_ "GenSigCycleTimeActive" SG_ 2548835620 Trailer1TPMTireInfo_PresWarn_ISi 100;
BA_ "GenSigStartValue" SG_ 2548835620 Trailer1TPMTireInfo_PresWarn_ISi 7;
BA_ "NeedsUpdateBit" SG_ 2548835620 Trailer1TPMTireInfo_PresWarn_ISi 1;
BA_ "Platform_VMCU1_Sig" SG_ 2548835620 Trailer1TPMTireInfo_PresWarn_ISi 1;
BA_ "SystemSignalLongSymbol" SG_ 2548835620 Trailer1TPMTireInfo_PresWarn_ISi "Trailer1TPMTireInfo_PresWarn_ISig_4";
BA_ "GenSigCycleTime" SG_ 2548835620 Trailer1TPMTireInfo_LeakageWarn_ 100;
BA_ "GenSigCycleTimeActive" SG_ 2548835620 Trailer1TPMTireInfo_LeakageWarn_ 100;
BA_ "GenSigStartValue" SG_ 2548835620 Trailer1TPMTireInfo_LeakageWarn_ 7;
BA_ "NeedsUpdateBit" SG_ 2548835620 Trailer1TPMTireInfo_LeakageWarn_ 1;
BA_ "Platform_VMCU1_Sig" SG_ 2548835620 Trailer1TPMTireInfo_LeakageWarn_ 1;
BA_ "SystemSignalLongSymbol" SG_ 2548835620 Trailer1TPMTireInfo_LeakageWarn_ "Trailer1TPMTireInfo_LeakageWarn_ISig_4";
BA_ "GenSigSendType" SG_ 2548835620 TPMPosOfWMResp_sg_UB_ISig_4 7;
BA_ "GenSigCycleTime" SG_ 2548835620 TPMPosOfWMResp_sg_UB_ISig_4 100;
BA_ "GenSigCycleTimeActive" SG_ 2548835620 TPMPosOfWMResp_sg_UB_ISig_4 100;
BA_ "Platform_VMCU1_Sig" SG_ 2548835620 TPMPosOfWMResp_sg_UB_ISig_4 1;
BA_ "GenSigCycleTime" SG_ 2548835620 TPMPosOfWMResp_VehiclePos_ISig_4 100;
BA_ "GenSigCycleTimeActive" SG_ 2548835620 TPMPosOfWMResp_VehiclePos_ISig_4 100;
BA_ "GenSigStartValue" SG_ 2548835620 TPMPosOfWMResp_VehiclePos_ISig_4 7;
BA_ "NeedsUpdateBit" SG_ 2548835620 TPMPosOfWMResp_VehiclePos_ISig_4 1;
BA_ "Platform_VMCU1_Sig" SG_ 2548835620 TPMPosOfWMResp_VehiclePos_ISig_4 1;
BA_ "GenSigCycleTime" SG_ 2548835620 Trailer1TPMTireInfo_TireId_ISig_ 100;
BA_ "GenSigCycleTimeActive" SG_ 2548835620 Trailer1TPMTireInfo_TireId_ISig_ 100;
BA_ "NeedsUpdateBit" SG_ 2548835620 Trailer1TPMTireInfo_TireId_ISig_ 1;
BA_ "Platform_VMCU1_Sig" SG_ 2548835620 Trailer1TPMTireInfo_TireId_ISig_ 1;
BA_ "SystemSignalLongSymbol" SG_ 2548835620 Trailer1TPMTireInfo_TireId_ISig_ "Trailer1TPMTireInfo_TireId_ISig_4";
BA_ "GenSigCycleTime" SG_ 2548835620 Trailer1TPMTireInfo_RefPres_ISig 100;
BA_ "GenSigCycleTimeActive" SG_ 2548835620 Trailer1TPMTireInfo_RefPres_ISig 100;
BA_ "GenSigStartValue" SG_ 2548835620 Trailer1TPMTireInfo_RefPres_ISig 255;
BA_ "NeedsUpdateBit" SG_ 2548835620 Trailer1TPMTireInfo_RefPres_ISig 1;
BA_ "Platform_VMCU1_Sig" SG_ 2548835620 Trailer1TPMTireInfo_RefPres_ISig 1;
BA_ "SystemSignalLongSymbol" SG_ 2548835620 Trailer1TPMTireInfo_RefPres_ISig "Trailer1TPMTireInfo_RefPres_ISig_4";
BA_ "GenSigCycleTime" SG_ 2548835620 Trailer1TPMTireInfo_Temperature_ 100;
BA_ "GenSigCycleTimeActive" SG_ 2548835620 Trailer1TPMTireInfo_Temperature_ 100;
BA_ "GenSigStartValue" SG_ 2548835620 Trailer1TPMTireInfo_Temperature_ 255;
BA_ "NeedsUpdateBit" SG_ 2548835620 Trailer1TPMTireInfo_Temperature_ 1;
BA_ "Platform_VMCU1_Sig" SG_ 2548835620 Trailer1TPMTireInfo_Temperature_ 1;
BA_ "SystemSignalLongSymbol" SG_ 2548835620 Trailer1TPMTireInfo_Temperature_ "Trailer1TPMTireInfo_Temperature_ISig_4";
BA_ "GenSigCycleTime" SG_ 2548835620 Trailer1TPMTireInfo_Active_ISig_ 100;
BA_ "GenSigCycleTimeActive" SG_ 2548835620 Trailer1TPMTireInfo_Active_ISig_ 100;
BA_ "GenSigStartValue" SG_ 2548835620 Trailer1TPMTireInfo_Active_ISig_ 3;
BA_ "NeedsUpdateBit" SG_ 2548835620 Trailer1TPMTireInfo_Active_ISig_ 1;
BA_ "Platform_VMCU1_Sig" SG_ 2548835620 Trailer1TPMTireInfo_Active_ISig_ 1;
BA_ "SystemSignalLongSymbol" SG_ 2548835620 Trailer1TPMTireInfo_Active_ISig_ "Trailer1TPMTireInfo_Active_ISig_4";
BA_ "GenSigCycleTime" SG_ 2548835620 TPMPosOfWMResp_Status_ISig_4 100;
BA_ "GenSigCycleTimeActive" SG_ 2548835620 TPMPosOfWMResp_Status_ISig_4 100;
BA_ "GenSigStartValue" SG_ 2548835620 TPMPosOfWMResp_Status_ISig_4 7;
BA_ "NeedsUpdateBit" SG_ 2548835620 TPMPosOfWMResp_Status_ISig_4 1;
BA_ "Platform_VMCU1_Sig" SG_ 2548835620 TPMPosOfWMResp_Status_ISig_4 1;
BA_ "GenSigCycleTime" SG_ 2548835620 TPMPosOfWMResp_TireId_ISig_4 100;
BA_ "GenSigCycleTimeActive" SG_ 2548835620 TPMPosOfWMResp_TireId_ISig_4 100;
BA_ "NeedsUpdateBit" SG_ 2548835620 TPMPosOfWMResp_TireId_ISig_4 1;
BA_ "Platform_VMCU1_Sig" SG_ 2548835620 TPMPosOfWMResp_TireId_ISig_4 1;
BA_ "GenSigCycleTime" SG_ 2566358564 TruckTPMThresCfg_OverPres_ISig_4 100;
BA_ "GenSigCycleTimeActive" SG_ 2566358564 TruckTPMThresCfg_OverPres_ISig_4 100;
BA_ "GenSigStartValue" SG_ 2566358564 TruckTPMThresCfg_OverPres_ISig_4 255;
BA_ "NeedsUpdateBit" SG_ 2566358564 TruckTPMThresCfg_OverPres_ISig_4 1;
BA_ "Platform_VMCU1_Sig" SG_ 2566358564 TruckTPMThresCfg_OverPres_ISig_4 1;
BA_ "GenSigCycleTime" SG_ 2566358564 TruckTPMAxlTireCfg_Axle2_ISig_4 100;
BA_ "GenSigCycleTimeActive" SG_ 2566358564 TruckTPMAxlTireCfg_Axle2_ISig_4 100;
BA_ "GenSigStartValue" SG_ 2566358564 TruckTPMAxlTireCfg_Axle2_ISig_4 7;
BA_ "Platform_VMCU1_Sig" SG_ 2566358564 TruckTPMAxlTireCfg_Axle2_ISig_4 1;
BA_ "GenSigCycleTime" SG_ 2566358564 TruckTPMAxlTireCfg_Axle1_ISig_4 100;
BA_ "GenSigCycleTimeActive" SG_ 2566358564 TruckTPMAxlTireCfg_Axle1_ISig_4 100;
BA_ "GenSigStartValue" SG_ 2566358564 TruckTPMAxlTireCfg_Axle1_ISig_4 7;
BA_ "Platform_VMCU1_Sig" SG_ 2566358564 TruckTPMAxlTireCfg_Axle1_ISig_4 1;
BA_ "GenSigCycleTime" SG_ 2566358564 TruckTPMAxlTireCfg_Axle5_ISig_4 100;
BA_ "GenSigCycleTimeActive" SG_ 2566358564 TruckTPMAxlTireCfg_Axle5_ISig_4 100;
BA_ "GenSigStartValue" SG_ 2566358564 TruckTPMAxlTireCfg_Axle5_ISig_4 7;
BA_ "Platform_VMCU1_Sig" SG_ 2566358564 TruckTPMAxlTireCfg_Axle5_ISig_4 1;
BA_ "GenSigSendType" SG_ 2566358564 TruckTPMThresCfg_sg_UB_ISig_4 7;
BA_ "GenSigCycleTime" SG_ 2566358564 TruckTPMThresCfg_sg_UB_ISig_4 100;
BA_ "GenSigCycleTimeActive" SG_ 2566358564 TruckTPMThresCfg_sg_UB_ISig_4 100;
BA_ "Platform_VMCU1_Sig" SG_ 2566358564 TruckTPMThresCfg_sg_UB_ISig_4 1;
BA_ "GenSigCycleTime" SG_ 2566358564 TruckTPMAxlTireCfg_Axle4_ISig_4 100;
BA_ "GenSigCycleTimeActive" SG_ 2566358564 TruckTPMAxlTireCfg_Axle4_ISig_4 100;
BA_ "GenSigStartValue" SG_ 2566358564 TruckTPMAxlTireCfg_Axle4_ISig_4 7;
BA_ "Platform_VMCU1_Sig" SG_ 2566358564 TruckTPMAxlTireCfg_Axle4_ISig_4 1;
BA_ "GenSigCycleTime" SG_ 2566358564 TruckTPMThresCfg_ExtUnderPres_IS 100;
BA_ "GenSigCycleTimeActive" SG_ 2566358564 TruckTPMThresCfg_ExtUnderPres_IS 100;
BA_ "GenSigStartValue" SG_ 2566358564 TruckTPMThresCfg_ExtUnderPres_IS 255;
BA_ "NeedsUpdateBit" SG_ 2566358564 TruckTPMThresCfg_ExtUnderPres_IS 1;
BA_ "Platform_VMCU1_Sig" SG_ 2566358564 TruckTPMThresCfg_ExtUnderPres_IS 1;
BA_ "SystemSignalLongSymbol" SG_ 2566358564 TruckTPMThresCfg_ExtUnderPres_IS "TruckTPMThresCfg_ExtUnderPres_ISig_4";
BA_ "GenSigCycleTime" SG_ 2566358564 TruckTPMThresCfg_AxleNr_ISig_4 100;
BA_ "GenSigCycleTimeActive" SG_ 2566358564 TruckTPMThresCfg_AxleNr_ISig_4 100;
BA_ "GenSigStartValue" SG_ 2566358564 TruckTPMThresCfg_AxleNr_ISig_4 7;
BA_ "NeedsUpdateBit" SG_ 2566358564 TruckTPMThresCfg_AxleNr_ISig_4 1;
BA_ "Platform_VMCU1_Sig" SG_ 2566358564 TruckTPMThresCfg_AxleNr_ISig_4 1;
BA_ "GenSigCycleTime" SG_ 2566358564 TruckTPMThresCfg_UnderPres_ISig_ 100;
BA_ "GenSigCycleTimeActive" SG_ 2566358564 TruckTPMThresCfg_UnderPres_ISig_ 100;
BA_ "GenSigStartValue" SG_ 2566358564 TruckTPMThresCfg_UnderPres_ISig_ 255;
BA_ "NeedsUpdateBit" SG_ 2566358564 TruckTPMThresCfg_UnderPres_ISig_ 1;
BA_ "Platform_VMCU1_Sig" SG_ 2566358564 TruckTPMThresCfg_UnderPres_ISig_ 1;
BA_ "SystemSignalLongSymbol" SG_ 2566358564 TruckTPMThresCfg_UnderPres_ISig_ "TruckTPMThresCfg_UnderPres_ISig_4";
BA_ "GenSigCycleTime" SG_ 2566358564 TruckTPMThresCfg_ExtOverPres_ISi 100;
BA_ "GenSigCycleTimeActive" SG_ 2566358564 TruckTPMThresCfg_ExtOverPres_ISi 100;
BA_ "GenSigStartValue" SG_ 2566358564 TruckTPMThresCfg_ExtOverPres_ISi 255;
BA_ "NeedsUpdateBit" SG_ 2566358564 TruckTPMThresCfg_ExtOverPres_ISi 1;
BA_ "Platform_VMCU1_Sig" SG_ 2566358564 TruckTPMThresCfg_ExtOverPres_ISi 1;
BA_ "SystemSignalLongSymbol" SG_ 2566358564 TruckTPMThresCfg_ExtOverPres_ISi "TruckTPMThresCfg_ExtOverPres_ISig_4";
BA_ "GenSigCycleTime" SG_ 2566358564 TruckTPMAxlTireCfg_Axle3_ISig_4 100;
BA_ "GenSigCycleTimeActive" SG_ 2566358564 TruckTPMAxlTireCfg_Axle3_ISig_4 100;
BA_ "GenSigStartValue" SG_ 2566358564 TruckTPMAxlTireCfg_Axle3_ISig_4 7;
BA_ "Platform_VMCU1_Sig" SG_ 2566358564 TruckTPMAxlTireCfg_Axle3_ISig_4 1;
BA_ "GenSigCycleTime" SG_ 2566358052 Trailer2TPMType_ISig_4 100;
BA_ "GenSigCycleTimeActive" SG_ 2566358052 Trailer2TPMType_ISig_4 100;
BA_ "GenSigStartValue" SG_ 2566358052 Trailer2TPMType_ISig_4 3;
BA_ "NeedsUpdateBit" SG_ 2566358052 Trailer2TPMType_ISig_4 1;
BA_ "Platform_VMCU1_Sig" SG_ 2566358052 Trailer2TPMType_ISig_4 1;
BA_ "GenSigCycleTime" SG_ 2566358052 Trailer2TPMAxlTireCfg_Axle1_ISig 100;
BA_ "GenSigCycleTimeActive" SG_ 2566358052 Trailer2TPMAxlTireCfg_Axle1_ISig 100;
BA_ "GenSigStartValue" SG_ 2566358052 Trailer2TPMAxlTireCfg_Axle1_ISig 7;
BA_ "Platform_VMCU1_Sig" SG_ 2566358052 Trailer2TPMAxlTireCfg_Axle1_ISig 1;
BA_ "SystemSignalLongSymbol" SG_ 2566358052 Trailer2TPMAxlTireCfg_Axle1_ISig "Trailer2TPMAxlTireCfg_Axle1_ISig_4";
BA_ "GenSigCycleTime" SG_ 2566358052 Trailer2TPMThresCfg_OverPres_ISi 100;
BA_ "GenSigCycleTimeActive" SG_ 2566358052 Trailer2TPMThresCfg_OverPres_ISi 100;
BA_ "GenSigStartValue" SG_ 2566358052 Trailer2TPMThresCfg_OverPres_ISi 255;
BA_ "NeedsUpdateBit" SG_ 2566358052 Trailer2TPMThresCfg_OverPres_ISi 1;
BA_ "Platform_VMCU1_Sig" SG_ 2566358052 Trailer2TPMThresCfg_OverPres_ISi 1;
BA_ "SystemSignalLongSymbol" SG_ 2566358052 Trailer2TPMThresCfg_OverPres_ISi "Trailer2TPMThresCfg_OverPres_ISig_4";
BA_ "GenSigCycleTime" SG_ 2566358052 Trailer2TPMAxlTireCfg_Axle3_ISig 100;
BA_ "GenSigCycleTimeActive" SG_ 2566358052 Trailer2TPMAxlTireCfg_Axle3_ISig 100;
BA_ "GenSigStartValue" SG_ 2566358052 Trailer2TPMAxlTireCfg_Axle3_ISig 7;
BA_ "Platform_VMCU1_Sig" SG_ 2566358052 Trailer2TPMAxlTireCfg_Axle3_ISig 1;
BA_ "SystemSignalLongSymbol" SG_ 2566358052 Trailer2TPMAxlTireCfg_Axle3_ISig "Trailer2TPMAxlTireCfg_Axle3_ISig_4";
BA_ "GenSigCycleTime" SG_ 2566358052 Trailer2TPMAxlTireCfg_Axle2_ISig 100;
BA_ "GenSigCycleTimeActive" SG_ 2566358052 Trailer2TPMAxlTireCfg_Axle2_ISig 100;
BA_ "GenSigStartValue" SG_ 2566358052 Trailer2TPMAxlTireCfg_Axle2_ISig 7;
BA_ "Platform_VMCU1_Sig" SG_ 2566358052 Trailer2TPMAxlTireCfg_Axle2_ISig 1;
BA_ "SystemSignalLongSymbol" SG_ 2566358052 Trailer2TPMAxlTireCfg_Axle2_ISig "Trailer2TPMAxlTireCfg_Axle2_ISig_4";
BA_ "GenSigCycleTime" SG_ 2566358052 Trailer2TPMAxlTireCfg_Axle5_ISig 100;
BA_ "GenSigCycleTimeActive" SG_ 2566358052 Trailer2TPMAxlTireCfg_Axle5_ISig 100;
BA_ "GenSigStartValue" SG_ 2566358052 Trailer2TPMAxlTireCfg_Axle5_ISig 7;
BA_ "Platform_VMCU1_Sig" SG_ 2566358052 Trailer2TPMAxlTireCfg_Axle5_ISig 1;
BA_ "SystemSignalLongSymbol" SG_ 2566358052 Trailer2TPMAxlTireCfg_Axle5_ISig "Trailer2TPMAxlTireCfg_Axle5_ISig_4";
BA_ "GenSigCycleTime" SG_ 2566358052 Trailer2TPMAxlTireCfg_Axle4_ISig 100;
BA_ "GenSigCycleTimeActive" SG_ 2566358052 Trailer2TPMAxlTireCfg_Axle4_ISig 100;
BA_ "GenSigStartValue" SG_ 2566358052 Trailer2TPMAxlTireCfg_Axle4_ISig 7;
BA_ "Platform_VMCU1_Sig" SG_ 2566358052 Trailer2TPMAxlTireCfg_Axle4_ISig 1;
BA_ "SystemSignalLongSymbol" SG_ 2566358052 Trailer2TPMAxlTireCfg_Axle4_ISig "Trailer2TPMAxlTireCfg_Axle4_ISig_4";
BA_ "GenSigSendType" SG_ 2566358052 Trailer2TPMThresCfg_sg_UB_ISig_4 7;
BA_ "GenSigCycleTime" SG_ 2566358052 Trailer2TPMThresCfg_sg_UB_ISig_4 100;
BA_ "GenSigCycleTimeActive" SG_ 2566358052 Trailer2TPMThresCfg_sg_UB_ISig_4 100;
BA_ "Platform_VMCU1_Sig" SG_ 2566358052 Trailer2TPMThresCfg_sg_UB_ISig_4 1;
BA_ "GenSigCycleTime" SG_ 2566358052 Trailer2TPMThresCfg_AxleNr_ISig_ 100;
BA_ "GenSigCycleTimeActive" SG_ 2566358052 Trailer2TPMThresCfg_AxleNr_ISig_ 100;
BA_ "GenSigStartValue" SG_ 2566358052 Trailer2TPMThresCfg_AxleNr_ISig_ 7;
BA_ "NeedsUpdateBit" SG_ 2566358052 Trailer2TPMThresCfg_AxleNr_ISig_ 1;
BA_ "Platform_VMCU1_Sig" SG_ 2566358052 Trailer2TPMThresCfg_AxleNr_ISig_ 1;
BA_ "SystemSignalLongSymbol" SG_ 2566358052 Trailer2TPMThresCfg_AxleNr_ISig_ "Trailer2TPMThresCfg_AxleNr_ISig_4";
BA_ "GenSigCycleTime" SG_ 2566358052 Trailer2TPMThresCfg_ExtOverPres_ 100;
BA_ "GenSigCycleTimeActive" SG_ 2566358052 Trailer2TPMThresCfg_ExtOverPres_ 100;
BA_ "GenSigStartValue" SG_ 2566358052 Trailer2TPMThresCfg_ExtOverPres_ 255;
BA_ "NeedsUpdateBit" SG_ 2566358052 Trailer2TPMThresCfg_ExtOverPres_ 1;
BA_ "Platform_VMCU1_Sig" SG_ 2566358052 Trailer2TPMThresCfg_ExtOverPres_ 1;
BA_ "SystemSignalLongSymbol" SG_ 2566358052 Trailer2TPMThresCfg_ExtOverPres_ "Trailer2TPMThresCfg_ExtOverPres_ISig_4";
BA_ "GenSigCycleTime" SG_ 2566358052 Trailer2TPMThresCfg_UnderPres_IS 100;
BA_ "GenSigCycleTimeActive" SG_ 2566358052 Trailer2TPMThresCfg_UnderPres_IS 100;
BA_ "GenSigStartValue" SG_ 2566358052 Trailer2TPMThresCfg_UnderPres_IS 255;
BA_ "NeedsUpdateBit" SG_ 2566358052 Trailer2TPMThresCfg_UnderPres_IS 1;
BA_ "Platform_VMCU1_Sig" SG_ 2566358052 Trailer2TPMThresCfg_UnderPres_IS 1;
BA_ "SystemSignalLongSymbol" SG_ 2566358052 Trailer2TPMThresCfg_UnderPres_IS "Trailer2TPMThresCfg_UnderPres_ISig_4";
BA_ "GenSigCycleTime" SG_ 2566358052 Trailer2TPMThresCfg_ExtUnderPres 100;
BA_ "GenSigCycleTimeActive" SG_ 2566358052 Trailer2TPMThresCfg_ExtUnderPres 100;
BA_ "GenSigStartValue" SG_ 2566358052 Trailer2TPMThresCfg_ExtUnderPres 255;
BA_ "NeedsUpdateBit" SG_ 2566358052 Trailer2TPMThresCfg_ExtUnderPres 1;
BA_ "Platform_VMCU1_Sig" SG_ 2566358052 Trailer2TPMThresCfg_ExtUnderPres 1;
BA_ "SystemSignalLongSymbol" SG_ 2566358052 Trailer2TPMThresCfg_ExtUnderPres "Trailer2TPMThresCfg_ExtUnderPres_ISig_4";
BA_ "GenSigSendType" SG_ 2566358052 Trailer2TPMType_UB_ISig_4 7;
BA_ "Platform_VMCU1_Sig" SG_ 2566358052 Trailer2TPMType_UB_ISig_4 1;
BA_ "GenSigCycleTime" SG_ 2566357540 Trailer1TPMAxlTireCfg_Axle1_ISig 100;
BA_ "GenSigCycleTimeActive" SG_ 2566357540 Trailer1TPMAxlTireCfg_Axle1_ISig 100;
BA_ "GenSigStartValue" SG_ 2566357540 Trailer1TPMAxlTireCfg_Axle1_ISig 7;
BA_ "Platform_VMCU1_Sig" SG_ 2566357540 Trailer1TPMAxlTireCfg_Axle1_ISig 1;
BA_ "SystemSignalLongSymbol" SG_ 2566357540 Trailer1TPMAxlTireCfg_Axle1_ISig "Trailer1TPMAxlTireCfg_Axle1_ISig_4";
BA_ "GenSigCycleTime" SG_ 2566357540 Trailer1TPMThresCfg_ExtOverPres_ 100;
BA_ "GenSigCycleTimeActive" SG_ 2566357540 Trailer1TPMThresCfg_ExtOverPres_ 100;
BA_ "GenSigStartValue" SG_ 2566357540 Trailer1TPMThresCfg_ExtOverPres_ 255;
BA_ "NeedsUpdateBit" SG_ 2566357540 Trailer1TPMThresCfg_ExtOverPres_ 1;
BA_ "Platform_VMCU1_Sig" SG_ 2566357540 Trailer1TPMThresCfg_ExtOverPres_ 1;
BA_ "SystemSignalLongSymbol" SG_ 2566357540 Trailer1TPMThresCfg_ExtOverPres_ "Trailer1TPMThresCfg_ExtOverPres_ISig_4";
BA_ "GenSigCycleTime" SG_ 2566357540 Trailer1TPMAxlTireCfg_Axle2_ISig 100;
BA_ "GenSigCycleTimeActive" SG_ 2566357540 Trailer1TPMAxlTireCfg_Axle2_ISig 100;
BA_ "GenSigStartValue" SG_ 2566357540 Trailer1TPMAxlTireCfg_Axle2_ISig 7;
BA_ "Platform_VMCU1_Sig" SG_ 2566357540 Trailer1TPMAxlTireCfg_Axle2_ISig 1;
BA_ "SystemSignalLongSymbol" SG_ 2566357540 Trailer1TPMAxlTireCfg_Axle2_ISig "Trailer1TPMAxlTireCfg_Axle2_ISig_4";
BA_ "GenSigCycleTime" SG_ 2566357540 Trailer1TPMThresCfg_OverPres_ISi 100;
BA_ "GenSigCycleTimeActive" SG_ 2566357540 Trailer1TPMThresCfg_OverPres_ISi 100;
BA_ "GenSigStartValue" SG_ 2566357540 Trailer1TPMThresCfg_OverPres_ISi 255;
BA_ "NeedsUpdateBit" SG_ 2566357540 Trailer1TPMThresCfg_OverPres_ISi 1;
BA_ "Platform_VMCU1_Sig" SG_ 2566357540 Trailer1TPMThresCfg_OverPres_ISi 1;
BA_ "SystemSignalLongSymbol" SG_ 2566357540 Trailer1TPMThresCfg_OverPres_ISi "Trailer1TPMThresCfg_OverPres_ISig_4";
BA_ "GenSigCycleTime" SG_ 2566357540 Trailer1TPMAxlTireCfg_Axle5_ISig 100;
BA_ "GenSigCycleTimeActive" SG_ 2566357540 Trailer1TPMAxlTireCfg_Axle5_ISig 100;
BA_ "GenSigStartValue" SG_ 2566357540 Trailer1TPMAxlTireCfg_Axle5_ISig 7;
BA_ "Platform_VMCU1_Sig" SG_ 2566357540 Trailer1TPMAxlTireCfg_Axle5_ISig 1;
BA_ "SystemSignalLongSymbol" SG_ 2566357540 Trailer1TPMAxlTireCfg_Axle5_ISig "Trailer1TPMAxlTireCfg_Axle5_ISig_4";
BA_ "GenSigCycleTime" SG_ 2566357540 Trailer1TPMType_ISig_4 100;
BA_ "GenSigCycleTimeActive" SG_ 2566357540 Trailer1TPMType_ISig_4 100;
BA_ "GenSigStartValue" SG_ 2566357540 Trailer1TPMType_ISig_4 3;
BA_ "NeedsUpdateBit" SG_ 2566357540 Trailer1TPMType_ISig_4 1;
BA_ "Platform_VMCU1_Sig" SG_ 2566357540 Trailer1TPMType_ISig_4 1;
BA_ "GenSigCycleTime" SG_ 2566357540 Trailer1TPMThresCfg_UnderPres_IS 100;
BA_ "GenSigCycleTimeActive" SG_ 2566357540 Trailer1TPMThresCfg_UnderPres_IS 100;
BA_ "GenSigStartValue" SG_ 2566357540 Trailer1TPMThresCfg_UnderPres_IS 255;
BA_ "NeedsUpdateBit" SG_ 2566357540 Trailer1TPMThresCfg_UnderPres_IS 1;
BA_ "Platform_VMCU1_Sig" SG_ 2566357540 Trailer1TPMThresCfg_UnderPres_IS 1;
BA_ "SystemSignalLongSymbol" SG_ 2566357540 Trailer1TPMThresCfg_UnderPres_IS "Trailer1TPMThresCfg_UnderPres_ISig_4";
BA_ "GenSigSendType" SG_ 2566357540 Trailer1TPMThresCfg_sg_UB_ISig_4 7;
BA_ "GenSigCycleTime" SG_ 2566357540 Trailer1TPMThresCfg_sg_UB_ISig_4 100;
BA_ "GenSigCycleTimeActive" SG_ 2566357540 Trailer1TPMThresCfg_sg_UB_ISig_4 100;
BA_ "Platform_VMCU1_Sig" SG_ 2566357540 Trailer1TPMThresCfg_sg_UB_ISig_4 1;
BA_ "GenSigCycleTime" SG_ 2566357540 Trailer1TPMThresCfg_ExtUnderPres 100;
BA_ "GenSigCycleTimeActive" SG_ 2566357540 Trailer1TPMThresCfg_ExtUnderPres 100;
BA_ "GenSigStartValue" SG_ 2566357540 Trailer1TPMThresCfg_ExtUnderPres 255;
BA_ "NeedsUpdateBit" SG_ 2566357540 Trailer1TPMThresCfg_ExtUnderPres 1;
BA_ "Platform_VMCU1_Sig" SG_ 2566357540 Trailer1TPMThresCfg_ExtUnderPres 1;
BA_ "SystemSignalLongSymbol" SG_ 2566357540 Trailer1TPMThresCfg_ExtUnderPres "Trailer1TPMThresCfg_ExtUnderPres_ISig_4";
BA_ "GenSigCycleTime" SG_ 2566357540 Trailer1TPMThresCfg_AxleNr_ISig_ 100;
BA_ "GenSigCycleTimeActive" SG_ 2566357540 Trailer1TPMThresCfg_AxleNr_ISig_ 100;
BA_ "GenSigStartValue" SG_ 2566357540 Trailer1TPMThresCfg_AxleNr_ISig_ 7;
BA_ "NeedsUpdateBit" SG_ 2566357540 Trailer1TPMThresCfg_AxleNr_ISig_ 1;
BA_ "Platform_VMCU1_Sig" SG_ 2566357540 Trailer1TPMThresCfg_AxleNr_ISig_ 1;
BA_ "SystemSignalLongSymbol" SG_ 2566357540 Trailer1TPMThresCfg_AxleNr_ISig_ "Trailer1TPMThresCfg_AxleNr_ISig_4";
BA_ "GenSigCycleTime" SG_ 2566357540 MaintResetFailureCause 100;
BA_ "GenSigCycleTimeActive" SG_ 2566357540 MaintResetFailureCause 100;
BA_ "GenSigStartValue" SG_ 2566357540 MaintResetFailureCause 31;
BA_ "GenSigSendType" SG_ 2566357540 Trailer1TPMType_UB_ISig_4 7;
BA_ "Platform_VMCU1_Sig" SG_ 2566357540 Trailer1TPMType_UB_ISig_4 1;
BA_ "GenSigCycleTime" SG_ 2566357540 Trailer1TPMAxlTireCfg_Axle4_ISig 100;
BA_ "GenSigCycleTimeActive" SG_ 2566357540 Trailer1TPMAxlTireCfg_Axle4_ISig 100;
BA_ "GenSigStartValue" SG_ 2566357540 Trailer1TPMAxlTireCfg_Axle4_ISig 7;
BA_ "Platform_VMCU1_Sig" SG_ 2566357540 Trailer1TPMAxlTireCfg_Axle4_ISig 1;
BA_ "SystemSignalLongSymbol" SG_ 2566357540 Trailer1TPMAxlTireCfg_Axle4_ISig "Trailer1TPMAxlTireCfg_Axle4_ISig_4";
BA_ "GenSigCycleTime" SG_ 2566357540 Trailer1TPMAxlTireCfg_Axle3_ISig 100;
BA_ "GenSigCycleTimeActive" SG_ 2566357540 Trailer1TPMAxlTireCfg_Axle3_ISig 100;
BA_ "GenSigStartValue" SG_ 2566357540 Trailer1TPMAxlTireCfg_Axle3_ISig 7;
BA_ "Platform_VMCU1_Sig" SG_ 2566357540 Trailer1TPMAxlTireCfg_Axle3_ISig 1;
BA_ "SystemSignalLongSymbol" SG_ 2566357540 Trailer1TPMAxlTireCfg_Axle3_ISig "Trailer1TPMAxlTireCfg_Axle3_ISig_4";
BA_ "GenSigSendType" SG_ 2566357029 VMCU_BB2_66P_FCS 7;
BA_ "Platform_VMCU1_Sig" SG_ 2566357029 VMCU_BB2_66P_FCS 1;
BA_ "GenSigCycleTime" SG_ 2566357028 FuseAndRelayFault_ItemNoD2 100;
BA_ "GenSigCycleTimeActive" SG_ 2566357028 FuseAndRelayFault_ItemNoD2 100;
BA_ "GenSigMaxLatency" SG_ 2566357028 FuseAndRelayFault_ItemNoD2 1050;
BA_ "Platform_VMCU1_Sig" SG_ 2566357028 FuseAndRelayFault_ItemNoD2 1;
BA_ "GenSigCycleTime" SG_ 2566357028 FuseAndRelayFault_ItemNoD1 100;
BA_ "GenSigCycleTimeActive" SG_ 2566357028 FuseAndRelayFault_ItemNoD1 100;
BA_ "GenSigMaxLatency" SG_ 2566357028 FuseAndRelayFault_ItemNoD1 1050;
BA_ "Platform_VMCU1_Sig" SG_ 2566357028 FuseAndRelayFault_ItemNoD1 1;
BA_ "GenSigCycleTime" SG_ 2566357028 FuseAndRelayFault_ItemNoC2 100;
BA_ "GenSigCycleTimeActive" SG_ 2566357028 FuseAndRelayFault_ItemNoC2 100;
BA_ "GenSigMaxLatency" SG_ 2566357028 FuseAndRelayFault_ItemNoC2 1050;
BA_ "Platform_VMCU1_Sig" SG_ 2566357028 FuseAndRelayFault_ItemNoC2 1;
BA_ "GenSigCycleTime" SG_ 2566357028 FuseAndRelayFault_ItemNoB2 100;
BA_ "GenSigCycleTimeActive" SG_ 2566357028 FuseAndRelayFault_ItemNoB2 100;
BA_ "GenSigMaxLatency" SG_ 2566357028 FuseAndRelayFault_ItemNoB2 1050;
BA_ "Platform_VMCU1_Sig" SG_ 2566357028 FuseAndRelayFault_ItemNoB2 1;
BA_ "GenSigCycleTime" SG_ 2566357028 FuseAndRelayFault_TypeD 100;
BA_ "GenSigCycleTimeActive" SG_ 2566357028 FuseAndRelayFault_TypeD 100;
BA_ "GenSigStartValue" SG_ 2566357028 FuseAndRelayFault_TypeD 7;
BA_ "GenSigMaxLatency" SG_ 2566357028 FuseAndRelayFault_TypeD 1050;
BA_ "Platform_VMCU1_Sig" SG_ 2566357028 FuseAndRelayFault_TypeD 1;
BA_ "GenSigCycleTime" SG_ 2566357028 FuseAndRelayFault_TypeB 100;
BA_ "GenSigCycleTimeActive" SG_ 2566357028 FuseAndRelayFault_TypeB 100;
BA_ "GenSigStartValue" SG_ 2566357028 FuseAndRelayFault_TypeB 7;
BA_ "GenSigMaxLatency" SG_ 2566357028 FuseAndRelayFault_TypeB 1050;
BA_ "Platform_VMCU1_Sig" SG_ 2566357028 FuseAndRelayFault_TypeB 1;
BA_ "GenSigCycleTime" SG_ 2566357028 FuseAndRelayFault_TypeA 100;
BA_ "GenSigCycleTimeActive" SG_ 2566357028 FuseAndRelayFault_TypeA 100;
BA_ "GenSigStartValue" SG_ 2566357028 FuseAndRelayFault_TypeA 7;
BA_ "GenSigMaxLatency" SG_ 2566357028 FuseAndRelayFault_TypeA 1050;
BA_ "Platform_VMCU1_Sig" SG_ 2566357028 FuseAndRelayFault_TypeA 1;
BA_ "GenSigCycleTime" SG_ 2566357028 FuseAndRelayFault_ItemNoA1 100;
BA_ "GenSigCycleTimeActive" SG_ 2566357028 FuseAndRelayFault_ItemNoA1 100;
BA_ "GenSigMaxLatency" SG_ 2566357028 FuseAndRelayFault_ItemNoA1 1050;
BA_ "Platform_VMCU1_Sig" SG_ 2566357028 FuseAndRelayFault_ItemNoA1 1;
BA_ "GenSigCycleTime" SG_ 2566357028 FuseAndRelayFault_ItemNoA2 100;
BA_ "GenSigCycleTimeActive" SG_ 2566357028 FuseAndRelayFault_ItemNoA2 100;
BA_ "GenSigMaxLatency" SG_ 2566357028 FuseAndRelayFault_ItemNoA2 1050;
BA_ "Platform_VMCU1_Sig" SG_ 2566357028 FuseAndRelayFault_ItemNoA2 1;
BA_ "GenSigCycleTime" SG_ 2566357028 FuseAndRelayFault_ItemNoB1 100;
BA_ "GenSigCycleTimeActive" SG_ 2566357028 FuseAndRelayFault_ItemNoB1 100;
BA_ "GenSigMaxLatency" SG_ 2566357028 FuseAndRelayFault_ItemNoB1 1050;
BA_ "Platform_VMCU1_Sig" SG_ 2566357028 FuseAndRelayFault_ItemNoB1 1;
BA_ "GenSigCycleTime" SG_ 2566357028 FuseAndRelayFault_ItemNoC1 100;
BA_ "GenSigCycleTimeActive" SG_ 2566357028 FuseAndRelayFault_ItemNoC1 100;
BA_ "GenSigMaxLatency" SG_ 2566357028 FuseAndRelayFault_ItemNoC1 1050;
BA_ "Platform_VMCU1_Sig" SG_ 2566357028 FuseAndRelayFault_ItemNoC1 1;
BA_ "GenSigCycleTime" SG_ 2566357028 FuseAndRelayFault_TypeC 100;
BA_ "GenSigCycleTimeActive" SG_ 2566357028 FuseAndRelayFault_TypeC 100;
BA_ "GenSigStartValue" SG_ 2566357028 FuseAndRelayFault_TypeC 7;
BA_ "GenSigMaxLatency" SG_ 2566357028 FuseAndRelayFault_TypeC 1050;
BA_ "Platform_VMCU1_Sig" SG_ 2566357028 FuseAndRelayFault_TypeC 1;
BA_ "GenSigCycleTime" SG_ 2566895652 DistToEmptyLNG_ISig_4 100;
BA_ "GenSigCycleTimeActive" SG_ 2566895652 DistToEmptyLNG_ISig_4 100;
BA_ "GenSigStartValue" SG_ 2566895652 DistToEmptyLNG_ISig_4 65535;
BA_ "Platform_VMCU1_Sig" SG_ 2566895652 DistToEmptyLNG_ISig_4 1;
BA_ "GenSigCycleTime" SG_ 2566895652 DistToEmptyDiesel_ISig_4 100;
BA_ "GenSigCycleTimeActive" SG_ 2566895652 DistToEmptyDiesel_ISig_4 100;
BA_ "GenSigStartValue" SG_ 2566895652 DistToEmptyDiesel_ISig_4 65535;
BA_ "Platform_VMCU1_Sig" SG_ 2566895652 DistToEmptyDiesel_ISig_4 1;
BA_ "GenSigCycleTime" SG_ 2566895652 CoastingUseDistance_ISig_4 100;
BA_ "GenSigCycleTimeActive" SG_ 2566895652 CoastingUseDistance_ISig_4 100;
BA_ "GenSigStartValue" SG_ 2566895652 CoastingUseDistance_ISig_4 4294967295;
BA_ "Platform_VMCU1_Sig" SG_ 2566895652 CoastingUseDistance_ISig_4 1;
BA_ "GenSigCycleTime" SG_ 2566894884 EngSpeedOverThresholdTime_ISig_4 100;
BA_ "GenSigCycleTimeActive" SG_ 2566894884 EngSpeedOverThresholdTime_ISig_4 100;
BA_ "GenSigStartValue" SG_ 2566894884 EngSpeedOverThresholdTime_ISig_4 4294967295;
BA_ "Platform_VMCU1_Sig" SG_ 2566894884 EngSpeedOverThresholdTime_ISig_4 1;
BA_ "GenSigCycleTime" SG_ 2566894884 EngLoadOverThresholdDistance_ISi 100;
BA_ "GenSigCycleTimeActive" SG_ 2566894884 EngLoadOverThresholdDistance_ISi 100;
BA_ "GenSigStartValue" SG_ 2566894884 EngLoadOverThresholdDistance_ISi 4294967295;
BA_ "Platform_VMCU1_Sig" SG_ 2566894884 EngLoadOverThresholdDistance_ISi 1;
BA_ "SystemSignalLongSymbol" SG_ 2566894884 EngLoadOverThresholdDistance_ISi "EngLoadOverThresholdDistance_ISig_4";
BA_ "GenSigCycleTime" SG_ 2566894372 EngineGreenAreaFuel_ISig_4 100;
BA_ "GenSigCycleTimeActive" SG_ 2566894372 EngineGreenAreaFuel_ISig_4 100;
BA_ "GenSigStartValue" SG_ 2566894372 EngineGreenAreaFuel_ISig_4 4294967295;
BA_ "Platform_VMCU1_Sig" SG_ 2566894372 EngineGreenAreaFuel_ISig_4 1;
BA_ "GenSigCycleTime" SG_ 2566894372 LCCDistance_ISig_4 100;
BA_ "GenSigCycleTimeActive" SG_ 2566894372 LCCDistance_ISig_4 100;
BA_ "GenSigStartValue" SG_ 2566894372 LCCDistance_ISig_4 4294967295;
BA_ "Platform_VMCU1_Sig" SG_ 2566894372 LCCDistance_ISig_4 1;
BA_ "GenSigCycleTime" SG_ 2566893604 StopCounter_ISig_4 100;
BA_ "GenSigCycleTimeActive" SG_ 2566893604 StopCounter_ISig_4 100;
BA_ "GenSigStartValue" SG_ 2566893604 StopCounter_ISig_4 4294967295;
BA_ "Platform_VMCU1_Sig" SG_ 2566893604 StopCounter_ISig_4 1;
BA_ "GenSigCycleTime" SG_ 2566893604 OverspeedDistance_ISig_4 100;
BA_ "GenSigCycleTimeActive" SG_ 2566893604 OverspeedDistance_ISig_4 100;
BA_ "GenSigStartValue" SG_ 2566893604 OverspeedDistance_ISig_4 4294967295;
BA_ "Platform_VMCU1_Sig" SG_ 2566893604 OverspeedDistance_ISig_4 1;
BA_ "GenSigCycleTime" SG_ 2566892580 RobotizedGboxPowerModeTime_ISig_ 100;
BA_ "GenSigCycleTimeActive" SG_ 2566892580 RobotizedGboxPowerModeTime_ISig_ 100;
BA_ "GenSigStartValue" SG_ 2566892580 RobotizedGboxPowerModeTime_ISig_ 4294967295;
BA_ "Platform_VMCU1_Sig" SG_ 2566892580 RobotizedGboxPowerModeTime_ISig_ 1;
BA_ "SystemSignalLongSymbol" SG_ 2566892580 RobotizedGboxPowerModeTime_ISig_ "RobotizedGboxPowerModeTime_ISig_4";
BA_ "GenSigCycleTime" SG_ 2566892580 TotalServiceBrakeCounter_ISig_4 100;
BA_ "GenSigCycleTimeActive" SG_ 2566892580 TotalServiceBrakeCounter_ISig_4 100;
BA_ "GenSigStartValue" SG_ 2566892580 TotalServiceBrakeCounter_ISig_4 4294967295;
BA_ "Platform_VMCU1_Sig" SG_ 2566892580 TotalServiceBrakeCounter_ISig_4 1;
BA_ "GenSigCycleTime" SG_ 2566892068 RobotizedGboxManualModeTime_ISig 100;
BA_ "GenSigCycleTimeActive" SG_ 2566892068 RobotizedGboxManualModeTime_ISig 100;
BA_ "GenSigStartValue" SG_ 2566892068 RobotizedGboxManualModeTime_ISig 4294967295;
BA_ "Platform_VMCU1_Sig" SG_ 2566892068 RobotizedGboxManualModeTime_ISig 1;
BA_ "SystemSignalLongSymbol" SG_ 2566892068 RobotizedGboxManualModeTime_ISig "RobotizedGboxManualModeTime_ISig_4";
BA_ "GenSigCycleTime" SG_ 2566892068 RobotizedGboxAutoModeTime_ISig_4 100;
BA_ "GenSigCycleTimeActive" SG_ 2566892068 RobotizedGboxAutoModeTime_ISig_4 100;
BA_ "GenSigStartValue" SG_ 2566892068 RobotizedGboxAutoModeTime_ISig_4 4294967295;
BA_ "Platform_VMCU1_Sig" SG_ 2566892068 RobotizedGboxAutoModeTime_ISig_4 1;
BA_ "GenSigSendType" SG_ 2548897828 PusherAxleLoad_UB_ISig_4 7;
BA_ "Platform_VMCU1_Sig" SG_ 2548897828 PusherAxleLoad_UB_ISig_4 1;
BA_ "GenSigCycleTime" SG_ 2548897828 PusherAxleLoad_ISig_4 100;
BA_ "GenSigCycleTimeActive" SG_ 2548897828 PusherAxleLoad_ISig_4 100;
BA_ "GenSigStartValue" SG_ 2548897828 PusherAxleLoad_ISig_4 65535;
BA_ "NeedsUpdateBit" SG_ 2548897828 PusherAxleLoad_ISig_4 1;
BA_ "Platform_VMCU1_Sig" SG_ 2548897828 PusherAxleLoad_ISig_4 1;
BA_ "SeToolAncestorID_SIGNAL" SG_ 2548897828 PusherAxleLoad_ISig_4 "x0000001D0412EB1E";
BA_ "SeToolItemID_SIGNAL" SG_ 2548897828 PusherAxleLoad_ISig_4 "x0000001D04274C69";
BA_ "SeToolName_SIGNAL" SG_ 2548897828 PusherAxleLoad_ISig_4 "PusherAxleLoad";
BA_ "SeToolVersion_SIGNAL" SG_ 2548897828 PusherAxleLoad_ISig_4 "3";
BA_ "GenSigCycleTime" SG_ 2548897828 FogLight_Front_cmd_ISig_4 100;
BA_ "GenSigCycleTimeActive" SG_ 2548897828 FogLight_Front_cmd_ISig_4 100;
BA_ "GenSigStartValue" SG_ 2548897828 FogLight_Front_cmd_ISig_4 3;
BA_ "Platform_VMCU1_Sig" SG_ 2548897828 FogLight_Front_cmd_ISig_4 1;
BA_ "SeToolAncestorID_SIGNAL" SG_ 2548897828 FogLight_Front_cmd_ISig_4 "x0000001D04135140";
BA_ "SeToolItemID_SIGNAL" SG_ 2548897828 FogLight_Front_cmd_ISig_4 "x0000001D04384FD1";
BA_ "SeToolName_SIGNAL" SG_ 2548897828 FogLight_Front_cmd_ISig_4 "FogLight_Front_cmd";
BA_ "SeToolVersion_SIGNAL" SG_ 2548897828 FogLight_Front_cmd_ISig_4 "2";
BA_ "GenSigCycleTime" SG_ 2548897828 TagAxleLoad_ISig_4 100;
BA_ "GenSigCycleTimeActive" SG_ 2548897828 TagAxleLoad_ISig_4 100;
BA_ "GenSigStartValue" SG_ 2548897828 TagAxleLoad_ISig_4 65535;
BA_ "NeedsUpdateBit" SG_ 2548897828 TagAxleLoad_ISig_4 1;
BA_ "Platform_VMCU1_Sig" SG_ 2548897828 TagAxleLoad_ISig_4 1;
BA_ "SeToolAncestorID_SIGNAL" SG_ 2548897828 TagAxleLoad_ISig_4 "x0000001D0412EB1E";
BA_ "SeToolItemID_SIGNAL" SG_ 2548897828 TagAxleLoad_ISig_4 "x0000001D04274C69";
BA_ "SeToolName_SIGNAL" SG_ 2548897828 TagAxleLoad_ISig_4 "TagAxleLoad";
BA_ "SeToolVersion_SIGNAL" SG_ 2548897828 TagAxleLoad_ISig_4 "3";
BA_ "GenSigSendType" SG_ 2548897828 TagAxleLoad_UB_ISig_4 7;
BA_ "Platform_VMCU1_Sig" SG_ 2548897828 TagAxleLoad_UB_ISig_4 1;
BA_ "GenSigCycleTime" SG_ 2548897060 DriveAxleLoad_ISig_4 100;
BA_ "GenSigCycleTimeActive" SG_ 2548897060 DriveAxleLoad_ISig_4 100;
BA_ "GenSigStartValue" SG_ 2548897060 DriveAxleLoad_ISig_4 65535;
BA_ "NeedsUpdateBit" SG_ 2548897060 DriveAxleLoad_ISig_4 1;
BA_ "Platform_VMCU1_Sig" SG_ 2548897060 DriveAxleLoad_ISig_4 1;
BA_ "SeToolAncestorID_SIGNAL" SG_ 2548897060 DriveAxleLoad_ISig_4 "x0000001D0412EB1E";
BA_ "SeToolItemID_SIGNAL" SG_ 2548897060 DriveAxleLoad_ISig_4 "x0000001D04274C69";
BA_ "SeToolName_SIGNAL" SG_ 2548897060 DriveAxleLoad_ISig_4 "DriveAxleLoad";
BA_ "SeToolVersion_SIGNAL" SG_ 2548897060 DriveAxleLoad_ISig_4 "3";
BA_ "GenSigCycleTime" SG_ 2548897060 BatterySOCAlertRawData_rqst_ISig 100;
BA_ "GenSigCycleTimeActive" SG_ 2548897060 BatterySOCAlertRawData_rqst_ISig 100;
BA_ "GenSigStartValue" SG_ 2548897060 BatterySOCAlertRawData_rqst_ISig 7;
BA_ "Platform_VMCU1_Sig" SG_ 2548897060 BatterySOCAlertRawData_rqst_ISig 1;
BA_ "SystemSignalLongSymbol" SG_ 2548897060 BatterySOCAlertRawData_rqst_ISig "BatterySOCAlertRawData_rqst_ISig_4";
BA_ "GenSigSendType" SG_ 2548897060 SecondaryDriveAxleLoad_UB_ISig_4 7;
BA_ "Platform_VMCU1_Sig" SG_ 2548897060 SecondaryDriveAxleLoad_UB_ISig_4 1;
BA_ "GenSigSendType" SG_ 2548897060 DriveAxleLoad_UB_ISig_4 7;
BA_ "Platform_VMCU1_Sig" SG_ 2548897060 DriveAxleLoad_UB_ISig_4 1;
BA_ "GenSigCycleTime" SG_ 2548897060 ShortStopHeater_status_ISig_4 100;
BA_ "GenSigCycleTimeActive" SG_ 2548897060 ShortStopHeater_status_ISig_4 100;
BA_ "GenSigStartValue" SG_ 2548897060 ShortStopHeater_status_ISig_4 7;
BA_ "Platform_VMCU1_Sig" SG_ 2548897060 ShortStopHeater_status_ISig_4 1;
BA_ "GenSigCycleTime" SG_ 2548897060 SecondaryDriveAxleLoad_ISig_4 100;
BA_ "GenSigCycleTimeActive" SG_ 2548897060 SecondaryDriveAxleLoad_ISig_4 100;
BA_ "GenSigStartValue" SG_ 2548897060 SecondaryDriveAxleLoad_ISig_4 65535;
BA_ "NeedsUpdateBit" SG_ 2548897060 SecondaryDriveAxleLoad_ISig_4 1;
BA_ "Platform_VMCU1_Sig" SG_ 2548897060 SecondaryDriveAxleLoad_ISig_4 1;
BA_ "SeToolAncestorID_SIGNAL" SG_ 2548897060 SecondaryDriveAxleLoad_ISig_4 "x0000001D0412EB1E";
BA_ "SeToolItemID_SIGNAL" SG_ 2548897060 SecondaryDriveAxleLoad_ISig_4 "x0000001D04274C69";
BA_ "SeToolName_SIGNAL" SG_ 2548897060 SecondaryDriveAxleLoad_ISig_4 "SecondaryDriveAxleLoad";
BA_ "SeToolVersion_SIGNAL" SG_ 2548897060 SecondaryDriveAxleLoad_ISig_4 "3";
BA_ "GenSigCycleTime" SG_ 2548897060 LivBatDisconnectDetectStat_ISig_ 100;
BA_ "GenSigCycleTimeActive" SG_ 2548897060 LivBatDisconnectDetectStat_ISig_ 100;
BA_ "GenSigStartValue" SG_ 2548897060 LivBatDisconnectDetectStat_ISig_ 3;
BA_ "SystemSignalLongSymbol" SG_ 2548897060 LivBatDisconnectDetectStat_ISig_ "LivBatDisconnectDetectStat_ISig_4";
BA_ "GenSigSendType" SG_ 2566365477 VMCU_BB2_57P_FCS_18f7a125 7;
BA_ "Platform_VMCU1_Sig" SG_ 2566365477 VMCU_BB2_57P_FCS_18f7a125 1;
BA_ "GenSigCycleTime" SG_ 2566365476 MaintService_ServiceCalendarTime 100;
BA_ "GenSigCycleTimeActive" SG_ 2566365476 MaintService_ServiceCalendarTime 100;
BA_ "GenSigStartValue" SG_ 2566365476 MaintService_ServiceCalendarTime 4294967295;
BA_ "Platform_VMCU1_Sig" SG_ 2566365476 MaintService_ServiceCalendarTime 1;
BA_ "SystemSignalLongSymbol" SG_ 2566365476 MaintService_ServiceCalendarTime "MaintService_ServiceCalendarTime_ISig_4_18f7a124";
BA_ "GenSigCycleTime" SG_ 2566365476 MaintService_EngTimeID_ISig_4_18 100;
BA_ "GenSigCycleTimeActive" SG_ 2566365476 MaintService_EngTimeID_ISig_4_18 100;
BA_ "GenSigStartValue" SG_ 2566365476 MaintService_EngTimeID_ISig_4_18 255;
BA_ "Platform_VMCU1_Sig" SG_ 2566365476 MaintService_EngTimeID_ISig_4_18 1;
BA_ "SystemSignalLongSymbol" SG_ 2566365476 MaintService_EngTimeID_ISig_4_18 "MaintService_EngTimeID_ISig_4_18f7a124";
BA_ "GenSigCycleTime" SG_ 2566365476 MaintService_DistID_ISig_4_18f7a 100;
BA_ "GenSigCycleTimeActive" SG_ 2566365476 MaintService_DistID_ISig_4_18f7a 100;
BA_ "GenSigStartValue" SG_ 2566365476 MaintService_DistID_ISig_4_18f7a 255;
BA_ "Platform_VMCU1_Sig" SG_ 2566365476 MaintService_DistID_ISig_4_18f7a 1;
BA_ "SystemSignalLongSymbol" SG_ 2566365476 MaintService_DistID_ISig_4_18f7a "MaintService_DistID_ISig_4_18f7a124";
BA_ "GenSigCycleTime" SG_ 2566365476 MaintService_ServiceDistance_ISi 100;
BA_ "GenSigCycleTimeActive" SG_ 2566365476 MaintService_ServiceDistance_ISi 100;
BA_ "GenSigStartValue" SG_ 2566365476 MaintService_ServiceDistance_ISi 4294967295;
BA_ "Platform_VMCU1_Sig" SG_ 2566365476 MaintService_ServiceDistance_ISi 1;
BA_ "SystemSignalLongSymbol" SG_ 2566365476 MaintService_ServiceDistance_ISi "MaintService_ServiceDistance_ISig_4_18f7a124";
BA_ "GenSigCycleTime" SG_ 2566365476 MaintService_ServiceEngineTime_I 100;
BA_ "GenSigCycleTimeActive" SG_ 2566365476 MaintService_ServiceEngineTime_I 100;
BA_ "GenSigStartValue" SG_ 2566365476 MaintService_ServiceEngineTime_I 4294967295;
BA_ "Platform_VMCU1_Sig" SG_ 2566365476 MaintService_ServiceEngineTime_I 1;
BA_ "SystemSignalLongSymbol" SG_ 2566365476 MaintService_ServiceEngineTime_I "MaintService_ServiceEngineTime_ISig_4_18f7a124";
BA_ "GenSigCycleTime" SG_ 2566365476 MaintService_CalDateID_ISig_4_18 100;
BA_ "GenSigCycleTimeActive" SG_ 2566365476 MaintService_CalDateID_ISig_4_18 100;
BA_ "GenSigStartValue" SG_ 2566365476 MaintService_CalDateID_ISig_4_18 255;
BA_ "Platform_VMCU1_Sig" SG_ 2566365476 MaintService_CalDateID_ISig_4_18 1;
BA_ "SystemSignalLongSymbol" SG_ 2566365476 MaintService_CalDateID_ISig_4_18 "MaintService_CalDateID_ISig_4_18f7a124";
BA_ "GenSigSendType" SG_ 2566357285 VMCU_BB2_57P_FCS_18f78125 7;
BA_ "Platform_VMCU1_Sig" SG_ 2566357285 VMCU_BB2_57P_FCS_18f78125 1;
BA_ "GenSigCycleTime" SG_ 2566357284 MaintService_ServiceEngineT_0000 100;
BA_ "GenSigCycleTimeActive" SG_ 2566357284 MaintService_ServiceEngineT_0000 100;
BA_ "GenSigStartValue" SG_ 2566357284 MaintService_ServiceEngineT_0000 4294967295;
BA_ "Platform_VMCU1_Sig" SG_ 2566357284 MaintService_ServiceEngineT_0000 1;
BA_ "SystemSignalLongSymbol" SG_ 2566357284 MaintService_ServiceEngineT_0000 "MaintService_ServiceEngineTime_ISig_4_18f78124";
BA_ "GenSigCycleTime" SG_ 2566357284 MaintService_EngTimeID_ISig_0000 100;
BA_ "GenSigCycleTimeActive" SG_ 2566357284 MaintService_EngTimeID_ISig_0000 100;
BA_ "GenSigStartValue" SG_ 2566357284 MaintService_EngTimeID_ISig_0000 255;
BA_ "Platform_VMCU1_Sig" SG_ 2566357284 MaintService_EngTimeID_ISig_0000 1;
BA_ "SystemSignalLongSymbol" SG_ 2566357284 MaintService_EngTimeID_ISig_0000 "MaintService_EngTimeID_ISig_4_18f78124";
BA_ "GenSigCycleTime" SG_ 2566357284 MaintService_DistID_ISig_4_18f78 100;
BA_ "GenSigCycleTimeActive" SG_ 2566357284 MaintService_DistID_ISig_4_18f78 100;
BA_ "GenSigStartValue" SG_ 2566357284 MaintService_DistID_ISig_4_18f78 255;
BA_ "Platform_VMCU1_Sig" SG_ 2566357284 MaintService_DistID_ISig_4_18f78 1;
BA_ "SystemSignalLongSymbol" SG_ 2566357284 MaintService_DistID_ISig_4_18f78 "MaintService_DistID_ISig_4_18f78124";
BA_ "GenSigCycleTime" SG_ 2566357284 MaintService_ServiceDistanc_0000 100;
BA_ "GenSigCycleTimeActive" SG_ 2566357284 MaintService_ServiceDistanc_0000 100;
BA_ "GenSigStartValue" SG_ 2566357284 MaintService_ServiceDistanc_0000 4294967295;
BA_ "Platform_VMCU1_Sig" SG_ 2566357284 MaintService_ServiceDistanc_0000 1;
BA_ "SystemSignalLongSymbol" SG_ 2566357284 MaintService_ServiceDistanc_0000 "MaintService_ServiceDistance_ISig_4_18f78124";
BA_ "GenSigCycleTime" SG_ 2566357284 MaintService_CalDateID_ISig_0000 100;
BA_ "GenSigCycleTimeActive" SG_ 2566357284 MaintService_CalDateID_ISig_0000 100;
BA_ "GenSigStartValue" SG_ 2566357284 MaintService_CalDateID_ISig_0000 255;
BA_ "Platform_VMCU1_Sig" SG_ 2566357284 MaintService_CalDateID_ISig_0000 1;
BA_ "SystemSignalLongSymbol" SG_ 2566357284 MaintService_CalDateID_ISig_0000 "MaintService_CalDateID_ISig_4_18f78124";
BA_ "GenSigCycleTime" SG_ 2566357284 MaintService_ServiceCalenda_0000 100;
BA_ "GenSigCycleTimeActive" SG_ 2566357284 MaintService_ServiceCalenda_0000 100;
BA_ "GenSigStartValue" SG_ 2566357284 MaintService_ServiceCalenda_0000 4294967295;
BA_ "Platform_VMCU1_Sig" SG_ 2566357284 MaintService_ServiceCalenda_0000 1;
BA_ "SystemSignalLongSymbol" SG_ 2566357284 MaintService_ServiceCalenda_0000 "MaintService_ServiceCalendarTime_ISig_4_18f78124";
BA_ "GenSigCycleTime" SG_ 2566821202 EngTrueIdleSpeedTime_ISig_4 100;
BA_ "GenSigCycleTimeActive" SG_ 2566821202 EngTrueIdleSpeedTime_ISig_4 100;
BA_ "GenSigStartValue" SG_ 2566821202 EngTrueIdleSpeedTime_ISig_4 4294967295;
BA_ "GenSigMaxLatency" SG_ 2566821202 EngTrueIdleSpeedTime_ISig_4 1345;
BA_ "Platform_VMCU1_Sig" SG_ 2566821202 EngTrueIdleSpeedTime_ISig_4 1;
BA_ "GenSigCycleTime" SG_ 2566821202 EngineGreenAreaOutTime_ISig_4 100;
BA_ "GenSigCycleTimeActive" SG_ 2566821202 EngineGreenAreaOutTime_ISig_4 100;
BA_ "GenSigStartValue" SG_ 2566821202 EngineGreenAreaOutTime_ISig_4 4294967295;
BA_ "GenSigMaxLatency" SG_ 2566821202 EngineGreenAreaOutTime_ISig_4 1345;
BA_ "Platform_VMCU1_Sig" SG_ 2566821202 EngineGreenAreaOutTime_ISig_4 1;
BA_ "GenSigCycleTime" SG_ 2515845117 BatterySOCnom_ISig_4 100;
BA_ "GenSigCycleTimeActive" SG_ 2515845117 BatterySOCnom_ISig_4 100;
BA_ "GenSigStartValue" SG_ 2515845117 BatterySOCnom_ISig_4 255;
BA_ "GenSigMaxLatency" SG_ 2515845117 BatterySOCnom_ISig_4 187;
BA_ "Platform_VMCU1_Sig" SG_ 2515845117 BatterySOCnom_ISig_4 1;
BA_ "SeToolAncestorID_SIGNAL" SG_ 2515845117 BatterySOCnom_ISig_4 "x0000001D0431FB91";
BA_ "SeToolItemID_SIGNAL" SG_ 2515845117 BatterySOCnom_ISig_4 "x0000001D0431FB91";
BA_ "SeToolName_SIGNAL" SG_ 2515845117 BatterySOCnom_ISig_4 "BatterySOCnom";
BA_ "SeToolVersion_SIGNAL" SG_ 2515845117 BatterySOCnom_ISig_4 "1";
BA_ "GenSigCycleTime" SG_ 2515845117 BatterySOH_ISig_4 100;
BA_ "GenSigCycleTimeActive" SG_ 2515845117 BatterySOH_ISig_4 100;
BA_ "GenSigStartValue" SG_ 2515845117 BatterySOH_ISig_4 255;
BA_ "GenSigMaxLatency" SG_ 2515845117 BatterySOH_ISig_4 187;
BA_ "Platform_VMCU1_Sig" SG_ 2515845117 BatterySOH_ISig_4 1;
BA_ "SeToolAncestorID_SIGNAL" SG_ 2515845117 BatterySOH_ISig_4 "x0000001D041491DF";
BA_ "SeToolItemID_SIGNAL" SG_ 2515845117 BatterySOH_ISig_4 "x0000001D041491DF";
BA_ "SeToolName_SIGNAL" SG_ 2515845117 BatterySOH_ISig_4 "BatterySOH";
BA_ "SeToolVersion_SIGNAL" SG_ 2515845117 BatterySOH_ISig_4 "1";
BA_ "GenSigCycleTime" SG_ 2515845117 ReducedLoadMode_stat_ISig_4 100;
BA_ "GenSigCycleTimeActive" SG_ 2515845117 ReducedLoadMode_stat_ISig_4 100;
BA_ "GenSigStartValue" SG_ 2515845117 ReducedLoadMode_stat_ISig_4 3;
BA_ "Platform_VMCU1_Sig" SG_ 2515845117 ReducedLoadMode_stat_ISig_4 1;
BA_ "GenSigCycleTime" SG_ 2515845117 BatterySOCAlert_rqst_ISig_4 100;
BA_ "GenSigCycleTimeActive" SG_ 2515845117 BatterySOCAlert_rqst_ISig_4 100;
BA_ "GenSigStartValue" SG_ 2515845117 BatterySOCAlert_rqst_ISig_4 7;
BA_ "GenSigMaxLatency" SG_ 2515845117 BatterySOCAlert_rqst_ISig_4 187;
BA_ "Platform_VMCU1_Sig" SG_ 2515845117 BatterySOCAlert_rqst_ISig_4 1;
BA_ "GenSigCycleTime" SG_ 2515845117 BatteryVoltageDisplayValue_ISig_ 100;
BA_ "GenSigCycleTimeActive" SG_ 2515845117 BatteryVoltageDisplayValue_ISig_ 100;
BA_ "GenSigStartValue" SG_ 2515845117 BatteryVoltageDisplayValue_ISig_ 65535;
BA_ "GenSigMaxLatency" SG_ 2515845117 BatteryVoltageDisplayValue_ISig_ 187;
BA_ "Platform_VMCU1_Sig" SG_ 2515845117 BatteryVoltageDisplayValue_ISig_ 1;
BA_ "SystemSignalLongSymbol" SG_ 2515845117 BatteryVoltageDisplayValue_ISig_ "BatteryVoltageDisplayValue_ISig_4";
BA_ "GenSigCycleTime" SG_ 2515845117 BatteryCurrent_ISig_4 100;
BA_ "GenSigCycleTimeActive" SG_ 2515845117 BatteryCurrent_ISig_4 100;
BA_ "GenSigStartValue" SG_ 2515845117 BatteryCurrent_ISig_4 65535;
BA_ "GenSigMaxLatency" SG_ 2515845117 BatteryCurrent_ISig_4 187;
BA_ "Platform_VMCU1_Sig" SG_ 2515845117 BatteryCurrent_ISig_4 1;
BA_ "SeToolAncestorID_SIGNAL" SG_ 2515845117 BatteryCurrent_ISig_4 "x0000001D041491E4";
BA_ "SeToolItemID_SIGNAL" SG_ 2515845117 BatteryCurrent_ISig_4 "x0000001D042E2456";
BA_ "SeToolName_SIGNAL" SG_ 2515845117 BatteryCurrent_ISig_4 "BatteryCurrent";
BA_ "SeToolVersion_SIGNAL" SG_ 2515845117 BatteryCurrent_ISig_4 "2";
BA_ "GenSigCycleTime" SG_ 2515845117 BatterySOF_ISig_4 100;
BA_ "GenSigCycleTimeActive" SG_ 2515845117 BatterySOF_ISig_4 100;
BA_ "GenSigStartValue" SG_ 2515845117 BatterySOF_ISig_4 255;
BA_ "GenSigMaxLatency" SG_ 2515845117 BatterySOF_ISig_4 187;
BA_ "Platform_VMCU1_Sig" SG_ 2515845117 BatterySOF_ISig_4 1;
BA_REL_ "GenSigFirstTimeoutTime" BU_SG_REL_ HMIIOM SG_ 2566078244 FrontConspicLamp_stat_HiLeft_ISi 6000;
BA_REL_ "GenSigTimeoutTime" BU_SG_REL_ HMIIOM SG_ 2566078244 FrontConspicLamp_stat_HiLeft_ISi 1500;
BA_REL_ "GenSigFirstTimeoutTime" BU_SG_REL_ HMIIOM SG_ 2566078244 FrontConspicLamp_stat_LoRight_IS 6000;
BA_REL_ "GenSigTimeoutTime" BU_SG_REL_ HMIIOM SG_ 2566078244 FrontConspicLamp_stat_LoRight_IS 1500;
BA_REL_ "GenSigFirstTimeoutTime" BU_SG_REL_ HMIIOM SG_ 2566078244 FrontConspicLamp_stat_LoLeft_ISi 6000;
BA_REL_ "GenSigTimeoutTime" BU_SG_REL_ HMIIOM SG_ 2566078244 FrontConspicLamp_stat_LoLeft_ISi 1500;
BA_REL_ "GenSigFirstTimeoutTime" BU_SG_REL_ HMIIOM SG_ 2566078244 FrontConspicLamp_stat_HiRight_IS 6000;
BA_REL_ "GenSigTimeoutTime" BU_SG_REL_ HMIIOM SG_ 2566078244 FrontConspicLamp_stat_HiRight_IS 1500;
BA_REL_ "GenSigFirstTimeoutTime" BU_SG_REL_ DACU SG_ 2432663332 FASSaturated_ISig_4 3000;
BA_REL_ "GenSigTimeoutTime" BU_SG_REL_ DACU SG_ 2432663332 FASSaturated_ISig_4 120;
BA_REL_ "GenSigFirstTimeoutTime" BU_SG_REL_ HMIIOM SG_ 2432663332 OverSteerGuidanceStatus_ISig_4 3000;
BA_REL_ "GenSigTimeoutTime" BU_SG_REL_ HMIIOM SG_ 2432663332 OverSteerGuidanceStatus_ISig_4 80;
BA_REL_ "GenSigFirstTimeoutTime" BU_SG_REL_ BBM SG_ 2432663332 FASFullyOperational_ISig_4 24000;
BA_REL_ "GenSigTimeoutTime" BU_SG_REL_ BBM SG_ 2432663332 FASFullyOperational_ISig_4 4000;
BA_REL_ "GenSigFirstTimeoutTime" BU_SG_REL_ DACU SG_ 2432663332 FASFullyOperational_ISig_4 3000;
BA_REL_ "GenSigTimeoutTime" BU_SG_REL_ DACU SG_ 2432663332 FASFullyOperational_ISig_4 120;
BA_REL_ "GenSigFirstTimeoutTime" BU_SG_REL_ DACU SG_ 2432663332 FASFunctionInControl_ISig_4 3000;
BA_REL_ "GenSigTimeoutTime" BU_SG_REL_ DACU SG_ 2432663332 FASFunctionInControl_ISig_4 120;
BA_REL_ "GenSigFirstTimeoutTime" BU_SG_REL_ DACU SG_ 2432663332 FrontRoadWheelAngleEstimate_ISig 3000;
BA_REL_ "GenSigTimeoutTime" BU_SG_REL_ DACU SG_ 2432663332 FrontRoadWheelAngleEstimate_ISig 120;
BA_REL_ "GenSigFirstTimeoutTime" BU_SG_REL_ DACU SG_ 2432663332 DriverSteeringTorqueEstimate_ISi 3000;
BA_REL_ "GenSigTimeoutTime" BU_SG_REL_ DACU SG_ 2432663332 DriverSteeringTorqueEstimate_ISi 120;
BA_REL_ "GenSigFirstTimeoutTime" BU_SG_REL_ DACU SG_ 2432663332 DriverSteeringTqEstimateConf_ISi 3000;
BA_REL_ "GenSigTimeoutTime" BU_SG_REL_ DACU SG_ 2432663332 DriverSteeringTqEstimateConf_ISi 120;
BA_REL_ "GenSigFirstTimeoutTime" BU_SG_REL_ HMIIOM SG_ 2566359844 ActualFasPersSettingsButton_ISig 24000;
BA_REL_ "GenSigTimeoutTime" BU_SG_REL_ HMIIOM SG_ 2566359844 ActualFasPersSettingsButton_ISig 6000;
BA_REL_ "GenSigFirstTimeoutTime" BU_SG_REL_ HMIIOM SG_ 2566359844 FasUsrDefStiffStraightSetting_IS 24000;
BA_REL_ "GenSigTimeoutTime" BU_SG_REL_ HMIIOM SG_ 2566359844 FasUsrDefStiffStraightSetting_IS 6000;
BA_REL_ "GenSigFirstTimeoutTime" BU_SG_REL_ HMIIOM SG_ 2566359844 FuelLostByBraking_ISig_4 24000;
BA_REL_ "GenSigTimeoutTime" BU_SG_REL_ HMIIOM SG_ 2566359844 FuelLostByBraking_ISig_4 6000;
BA_REL_ "GenSigFirstTimeoutTime" BU_SG_REL_ HMIIOM SG_ 2566359844 ActualFasManualOffsetSetting_ISi 24000;
BA_REL_ "GenSigTimeoutTime" BU_SG_REL_ HMIIOM SG_ 2566359844 ActualFasManualOffsetSetting_ISi 6000;
BA_REL_ "GenSigFirstTimeoutTime" BU_SG_REL_ HMIIOM SG_ 2566359844 FasUsrDefinedDampingSetting_ISig 24000;
BA_REL_ "GenSigTimeoutTime" BU_SG_REL_ HMIIOM SG_ 2566359844 FasUsrDefinedDampingSetting_ISig 6000;
BA_REL_ "GenSigFirstTimeoutTime" BU_SG_REL_ HMIIOM SG_ 2566359844 FasDriver_ISig_4 24000;
BA_REL_ "GenSigTimeoutTime" BU_SG_REL_ HMIIOM SG_ 2566359844 FasDriver_ISig_4 6000;
BA_REL_ "GenSigFirstTimeoutTime" BU_SG_REL_ HMIIOM SG_ 2566359844 FasUsrDefLowSpeedReturnSetting_I 24000;
BA_REL_ "GenSigTimeoutTime" BU_SG_REL_ HMIIOM SG_ 2566359844 FasUsrDefLowSpeedReturnSetting_I 6000;
BA_REL_ "GenSigFirstTimeoutTime" BU_SG_REL_ HMIIOM SG_ 2566359844 FasUsrDefStiffnessCurveSetting_I 24000;
BA_REL_ "GenSigTimeoutTime" BU_SG_REL_ HMIIOM SG_ 2566359844 FasUsrDefStiffnessCurveSetting_I 6000;
BA_REL_ "GenSigFirstTimeoutTime" BU_SG_REL_ HMIIOM SG_ 2481984804 PS_PosLightDoorOpen_ISig_4 3000;
BA_REL_ "GenSigTimeoutTime" BU_SG_REL_ HMIIOM SG_ 2481984804 PS_PosLightDoorOpen_ISig_4 600;
BA_REL_ "GenSigFirstTimeoutTime" BU_SG_REL_ HMIIOM SG_ 2481984804 PS_FogLightRear_ISig_4 3000;
BA_REL_ "GenSigTimeoutTime" BU_SG_REL_ HMIIOM SG_ 2481984804 PS_FogLightRear_ISig_4 600;
BA_REL_ "GenSigFirstTimeoutTime" BU_SG_REL_ CIOM SG_ 2481984804 TrailerBodyLampDI_stat 6000;
BA_REL_ "GenSigTimeoutTime" BU_SG_REL_ CIOM SG_ 2481984804 TrailerBodyLampDI_stat 6000;
BA_REL_ "GenSigFirstTimeoutTime" BU_SG_REL_ HMIIOM SG_ 2481984804 ParkedLoadDistribution_ISig_4 3000;
BA_REL_ "GenSigTimeoutTime" BU_SG_REL_ HMIIOM SG_ 2481984804 ParkedLoadDistribution_ISig_4 300;
BA_REL_ "GenSigFirstTimeoutTime" BU_SG_REL_ HMIIOM SG_ 2481984804 PV_HeadLightLevel_ISig_4 3000;
BA_REL_ "GenSigTimeoutTime" BU_SG_REL_ HMIIOM SG_ 2481984804 PV_HeadLightLevel_ISig_4 300;
BA_REL_ "GenSigFirstTimeoutTime" BU_SG_REL_ CIOM SG_ 2481984804 TrailerBodyLampFdbk_stat 6000;
BA_REL_ "GenSigTimeoutTime" BU_SG_REL_ CIOM SG_ 2481984804 TrailerBodyLampFdbk_stat 6000;
BA_REL_ "GenSigFirstTimeoutTime" BU_SG_REL_ HMIIOM SG_ 2481984804 PS_FogLightFront_ISig_4 3000;
BA_REL_ "GenSigTimeoutTime" BU_SG_REL_ HMIIOM SG_ 2481984804 PS_FogLightFront_ISig_4 600;
BA_REL_ "GenSigFirstTimeoutTime" BU_SG_REL_ HMIIOM SG_ 2481984804 DriverCrank_rqst_ISig_4 3000;
BA_REL_ "GenSigTimeoutTime" BU_SG_REL_ HMIIOM SG_ 2481984804 DriverCrank_rqst_ISig_4 300;
BA_REL_ "GenSigFirstTimeoutTime" BU_SG_REL_ HMIIOM SG_ 2481984804 PS_HeadLightAdjustment_ISig_4 3000;
BA_REL_ "GenSigTimeoutTime" BU_SG_REL_ HMIIOM SG_ 2481984804 PS_HeadLightAdjustment_ISig_4 600;
BA_REL_ "GenSigFirstTimeoutTime" BU_SG_REL_ HMIIOM SG_ 2481984804 PS_MainBeam_ISig_4 3000;
BA_REL_ "GenSigTimeoutTime" BU_SG_REL_ HMIIOM SG_ 2481984804 PS_MainBeam_ISig_4 600;
BA_REL_ "GenSigFirstTimeoutTime" BU_SG_REL_ HMIIOM SG_ 2481984804 FifthWheelHandleLock_ind_ISig_4 3000;
BA_REL_ "GenSigTimeoutTime" BU_SG_REL_ HMIIOM SG_ 2481984804 FifthWheelHandleLock_ind_ISig_4 300;
BA_REL_ "GenSigFirstTimeoutTime" BU_SG_REL_ HMIIOM SG_ 2481984804 InstFuel_ConsumpValue_ISig_4 3000;
BA_REL_ "GenSigTimeoutTime" BU_SG_REL_ HMIIOM SG_ 2481984804 InstFuel_ConsumpValue_ISig_4 600;
BA_REL_ "GenSigFirstTimeoutTime" BU_SG_REL_ HMIIOM SG_ 2481984804 InstFuel_VehicleMoving_ISig_4 3000;
BA_REL_ "GenSigTimeoutTime" BU_SG_REL_ HMIIOM SG_ 2481984804 InstFuel_VehicleMoving_ISig_4 600;
BA_REL_ "GenSigFirstTimeoutTime" BU_SG_REL_ HMIIOM SG_ 2481984804 PS_AFSAllowedInDriveP_ISig_4 3000;
BA_REL_ "GenSigTimeoutTime" BU_SG_REL_ HMIIOM SG_ 2481984804 PS_AFSAllowedInDriveP_ISig_4 600;
BA_REL_ "GenSigFirstTimeoutTime" BU_SG_REL_ HMIIOM SG_ 2481984804 PS_AFS_ISig_4 3000;
BA_REL_ "GenSigTimeoutTime" BU_SG_REL_ HMIIOM SG_ 2481984804 PS_AFS_ISig_4 600;
BA_REL_ "GenSigFirstTimeoutTime" BU_SG_REL_ CIOM SG_ 2481984804 AC2CoolingFanControl_rqst 6000;
BA_REL_ "GenSigTimeoutTime" BU_SG_REL_ CIOM SG_ 2481984804 AC2CoolingFanControl_rqst 6000;
BA_REL_ "GenSigFirstTimeoutTime" BU_SG_REL_ HMIIOM SG_ 2481984804 DHCStatus 3000;
BA_REL_ "GenSigTimeoutTime" BU_SG_REL_ HMIIOM SG_ 2481984804 DHCStatus 600;
BA_REL_ "GenSigFirstTimeoutTime" BU_SG_REL_ HMIIOM SG_ 2481984804 PS_PositionLight_ISig_4 3000;
BA_REL_ "GenSigTimeoutTime" BU_SG_REL_ HMIIOM SG_ 2481984804 PS_PositionLight_ISig_4 600;
BA_REL_ "GenSigFirstTimeoutTime" BU_SG_REL_ HMIIOM SG_ 2516006692 EcoCruiseSetSpeed 3600;
BA_REL_ "GenSigTimeoutTime" BU_SG_REL_ HMIIOM SG_ 2516006692 EcoCruiseSetSpeed 900;
BA_REL_ "GenSigFirstTimeoutTime" BU_SG_REL_ EMS SG_ 2516006692 EngOvrrideCtrlStat_FireTruckMode 3000;
BA_REL_ "GenSigTimeoutTime" BU_SG_REL_ EMS SG_ 2516006692 EngOvrrideCtrlStat_FireTruckMode 600;
BA_REL_ "GenSigFirstTimeoutTime" BU_SG_REL_ EMS SG_ 2516006692 EngOvrrideCtrlStat_StartOvrrMode 3000;
BA_REL_ "GenSigTimeoutTime" BU_SG_REL_ EMS SG_ 2516006692 EngOvrrideCtrlStat_StartOvrrMode 600;
BA_REL_ "GenSigFirstTimeoutTime" BU_SG_REL_ EMS SG_ 2516006692 EngOvrrideCtrlStat_ProtOvrrMode 3000;
BA_REL_ "GenSigTimeoutTime" BU_SG_REL_ EMS SG_ 2516006692 EngOvrrideCtrlStat_ProtOvrrMode 600;
BA_REL_ "GenSigFirstTimeoutTime" BU_SG_REL_ EMS SG_ 2516006692 XRSLBTargetSpeedRequest 3000;
BA_REL_ "GenSigTimeoutTime" BU_SG_REL_ EMS SG_ 2516006692 XRSLBTargetSpeedRequest 600;
BA_REL_ "GenSigFirstTimeoutTime" BU_SG_REL_ TECU SG_ 2516006692 XRSLBTargetSpeedRequest 3600;
BA_REL_ "GenSigTimeoutTime" BU_SG_REL_ TECU SG_ 2516006692 XRSLBTargetSpeedRequest 900;
BA_REL_ "GenSigFirstTimeoutTime" BU_SG_REL_ HMIIOM SG_ 2516006180 EcoCruiseMinSpeedLev3 3600;
BA_REL_ "GenSigTimeoutTime" BU_SG_REL_ HMIIOM SG_ 2516006180 EcoCruiseMinSpeedLev3 900;
BA_REL_ "GenSigFirstTimeoutTime" BU_SG_REL_ HMIIOM SG_ 2516006180 EcoCruiseMinSpeedLev0 3600;
BA_REL_ "GenSigTimeoutTime" BU_SG_REL_ HMIIOM SG_ 2516006180 EcoCruiseMinSpeedLev0 900;
BA_REL_ "GenSigFirstTimeoutTime" BU_SG_REL_ HMIIOM SG_ 2516006180 EcoCruiseMinSpeedLev1 3600;
BA_REL_ "GenSigTimeoutTime" BU_SG_REL_ HMIIOM SG_ 2516006180 EcoCruiseMinSpeedLev1 900;
BA_REL_ "GenSigFirstTimeoutTime" BU_SG_REL_ HMIIOM SG_ 2516006180 EcoCruiseMinSpeedLev2 3600;
BA_REL_ "GenSigTimeoutTime" BU_SG_REL_ HMIIOM SG_ 2516006180 EcoCruiseMinSpeedLev2 900;
BA_REL_ "GenSigFirstTimeoutTime" BU_SG_REL_ HMIIOM SG_ 2516005668 EcoCruiseMaxSpeedLev1 3600;
BA_REL_ "GenSigTimeoutTime" BU_SG_REL_ HMIIOM SG_ 2516005668 EcoCruiseMaxSpeedLev1 900;
BA_REL_ "GenSigFirstTimeoutTime" BU_SG_REL_ HMIIOM SG_ 2516005668 EcoCruiseMaxSpeedLev0 3600;
BA_REL_ "GenSigTimeoutTime" BU_SG_REL_ HMIIOM SG_ 2516005668 EcoCruiseMaxSpeedLev0 900;
BA_REL_ "GenSigFirstTimeoutTime" BU_SG_REL_ HMIIOM SG_ 2516005668 EcoCruiseMaxSpeedLev2 3600;
BA_REL_ "GenSigTimeoutTime" BU_SG_REL_ HMIIOM SG_ 2516005668 EcoCruiseMaxSpeedLev2 900;
BA_REL_ "GenSigFirstTimeoutTime" BU_SG_REL_ HMIIOM SG_ 2516005668 EcoCruiseMaxSpeedLev3 3600;
BA_REL_ "GenSigTimeoutTime" BU_SG_REL_ HMIIOM SG_ 2516005668 EcoCruiseMaxSpeedLev3 900;
BA_REL_ "GenSigFirstTimeoutTime" BU_SG_REL_ HMIIOM SG_ 2516005156 EcoCruiseCCBSetSpeedLev2 3600;
BA_REL_ "GenSigTimeoutTime" BU_SG_REL_ HMIIOM SG_ 2516005156 EcoCruiseCCBSetSpeedLev2 900;
BA_REL_ "GenSigFirstTimeoutTime" BU_SG_REL_ HMIIOM SG_ 2516005156 EcoCruiseCCBSetSpeedLev1 3600;
BA_REL_ "GenSigTimeoutTime" BU_SG_REL_ HMIIOM SG_ 2516005156 EcoCruiseCCBSetSpeedLev1 900;
BA_REL_ "GenSigFirstTimeoutTime" BU_SG_REL_ HMIIOM SG_ 2516005156 EcoCruiseCCBSetSpeedLev3 3600;
BA_REL_ "GenSigTimeoutTime" BU_SG_REL_ HMIIOM SG_ 2516005156 EcoCruiseCCBSetSpeedLev3 900;
BA_REL_ "GenSigFirstTimeoutTime" BU_SG_REL_ HMIIOM SG_ 2516005156 EcoCruiseCCBSetSpeedLev0 3600;
BA_REL_ "GenSigTimeoutTime" BU_SG_REL_ HMIIOM SG_ 2516005156 EcoCruiseCCBSetSpeedLev0 900;
BA_REL_ "GenSigFirstTimeoutTime" BU_SG_REL_ HMIIOM SG_ 2566359332 EngineGreenAreaOutLNG_ISig_4 24000;
BA_REL_ "GenSigTimeoutTime" BU_SG_REL_ HMIIOM SG_ 2566359332 EngineGreenAreaOutLNG_ISig_4 6000;
BA_REL_ "GenSigFirstTimeoutTime" BU_SG_REL_ HMIIOM SG_ 2566359332 EngineGreenAreaLNG_ISig_4 24000;
BA_REL_ "GenSigTimeoutTime" BU_SG_REL_ HMIIOM SG_ 2566359332 EngineGreenAreaLNG_ISig_4 6000;
BA_REL_ "GenSigFirstTimeoutTime" BU_SG_REL_ HMIIOM SG_ 2515322916 BatteryTempAlert_rqst_ISig_4 3000;
BA_REL_ "GenSigTimeoutTime" BU_SG_REL_ HMIIOM SG_ 2515322916 BatteryTempAlert_rqst_ISig_4 600;
BA_REL_ "GenSigFirstTimeoutTime" BU_SG_REL_ HMIIOM SG_ 2515322916 BatteryCapacity_ISig_4 3000;
BA_REL_ "GenSigTimeoutTime" BU_SG_REL_ HMIIOM SG_ 2515322916 BatteryCapacity_ISig_4 600;
BA_REL_ "GenSigFirstTimeoutTime" BU_SG_REL_ DACU SG_ 2515322916 CollisionSituationAliveStatus 3000;
BA_REL_ "GenSigTimeoutTime" BU_SG_REL_ DACU SG_ 2515322916 CollisionSituationAliveStatus 600;
BA_REL_ "GenSigFirstTimeoutTime" BU_SG_REL_ HMIIOM SG_ 2515322916 Hazard_rqst_ISig_4 3000;
BA_REL_ "GenSigTimeoutTime" BU_SG_REL_ HMIIOM SG_ 2515322916 Hazard_rqst_ISig_4 600;
BA_REL_ "GenSigFirstTimeoutTime" BU_SG_REL_ HMIIOM SG_ 2515322916 BatterySOCact_ISig_4 3000;
BA_REL_ "GenSigTimeoutTime" BU_SG_REL_ HMIIOM SG_ 2515322916 BatterySOCact_ISig_4 600;
BA_REL_ "GenSigFirstTimeoutTime" BU_SG_REL_ HMIIOM SG_ 2515322916 Trailer1TPMLostCom_ISig_4 4800;
BA_REL_ "GenSigTimeoutTime" BU_SG_REL_ HMIIOM SG_ 2515322916 Trailer1TPMLostCom_ISig_4 1200;
BA_REL_ "GenSigFirstTimeoutTime" BU_SG_REL_ HMIIOM SG_ 2515322916 BatterySOCactCriticalAlert_ISig_ 3000;
BA_REL_ "GenSigTimeoutTime" BU_SG_REL_ HMIIOM SG_ 2515322916 BatterySOCactCriticalAlert_ISig_ 600;
BA_REL_ "GenSigFirstTimeoutTime" BU_SG_REL_ HMIIOM SG_ 2515322916 BatteryTempAlertRawData_rqst_ISi 3000;
BA_REL_ "GenSigTimeoutTime" BU_SG_REL_ HMIIOM SG_ 2515322916 BatteryTempAlertRawData_rqst_ISi 600;
BA_REL_ "GenSigFirstTimeoutTime" BU_SG_REL_ CIOM SG_ 2515322916 FPBRMMIStat_FPBRChangeAck_ISig_4 3000;
BA_REL_ "GenSigTimeoutTime" BU_SG_REL_ CIOM SG_ 2515322916 FPBRMMIStat_FPBRChangeAck_ISig_4 600;
BA_REL_ "GenSigFirstTimeoutTime" BU_SG_REL_ HMIIOM SG_ 2515322916 BatteryTemp_ISig_4 3000;
BA_REL_ "GenSigTimeoutTime" BU_SG_REL_ HMIIOM SG_ 2515322916 BatteryTemp_ISig_4 600;
BA_REL_ "GenSigFirstTimeoutTime" BU_SG_REL_ CIOM SG_ 2515322916 FPBRMMIStat_FPBRStatusInd_ISig_4 3000;
BA_REL_ "GenSigTimeoutTime" BU_SG_REL_ CIOM SG_ 2515322916 FPBRMMIStat_FPBRStatusInd_ISig_4 600;
BA_REL_ "GenSigFirstTimeoutTime" BU_SG_REL_ HMIIOM SG_ 2515322916 Trailer2TPMLostCom_ISig_4 4800;
BA_REL_ "GenSigTimeoutTime" BU_SG_REL_ HMIIOM SG_ 2515322916 Trailer2TPMLostCom_ISig_4 1200;
BA_REL_ "GenSigFirstTimeoutTime" BU_SG_REL_ DACU SG_ 2515322916 CollisionSituationAliveRequest 3000;
BA_REL_ "GenSigTimeoutTime" BU_SG_REL_ DACU SG_ 2515322916 CollisionSituationAliveRequest 600;
BA_REL_ "GenSigFirstTimeoutTime" BU_SG_REL_ HMIIOM SG_ 2515321892 TPMMateTrailerResp_ISig_4 3000;
BA_REL_ "GenSigTimeoutTime" BU_SG_REL_ HMIIOM SG_ 2515321892 TPMMateTrailerResp_ISig_4 600;
BA_REL_ "GenSigFirstTimeoutTime" BU_SG_REL_ HMIIOM SG_ 2515321892 Trailer2TPMLeakageWarning_ISig_4 3000;
BA_REL_ "GenSigTimeoutTime" BU_SG_REL_ HMIIOM SG_ 2515321892 Trailer2TPMLeakageWarning_ISig_4 600;
BA_REL_ "GenSigFirstTimeoutTime" BU_SG_REL_ HMIIOM SG_ 2515321892 TPMAutomaticMating_ISig_4 3000;
BA_REL_ "GenSigTimeoutTime" BU_SG_REL_ HMIIOM SG_ 2515321892 TPMAutomaticMating_ISig_4 600;
BA_REL_ "GenSigFirstTimeoutTime" BU_SG_REL_ HMIIOM SG_ 2515321892 Trailer2TPMMatedStatus_ISig_4 3000;
BA_REL_ "GenSigTimeoutTime" BU_SG_REL_ HMIIOM SG_ 2515321892 Trailer2TPMMatedStatus_ISig_4 600;
BA_REL_ "GenSigFirstTimeoutTime" BU_SG_REL_ HMIIOM SG_ 2515321892 Trailer1TPMMatedStatus_ISig_4 3000;
BA_REL_ "GenSigTimeoutTime" BU_SG_REL_ HMIIOM SG_ 2515321892 Trailer1TPMMatedStatus_ISig_4 600;
BA_REL_ "GenSigFirstTimeoutTime" BU_SG_REL_ HMIIOM SG_ 2515321892 TruckTPMLeakageWarning_ISig_4 3000;
BA_REL_ "GenSigTimeoutTime" BU_SG_REL_ HMIIOM SG_ 2515321892 TruckTPMLeakageWarning_ISig_4 600;
BA_REL_ "GenSigFirstTimeoutTime" BU_SG_REL_ CIOM SG_ 2515321892 ExtraSideMarkers_FunctStat 3000;
BA_REL_ "GenSigTimeoutTime" BU_SG_REL_ CIOM SG_ 2515321892 ExtraSideMarkers_FunctStat 600;
BA_REL_ "GenSigFirstTimeoutTime" BU_SG_REL_ HMIIOM SG_ 2515321892 Trailer2TPMPressureWarning_ISig_ 3000;
BA_REL_ "GenSigTimeoutTime" BU_SG_REL_ HMIIOM SG_ 2515321892 Trailer2TPMPressureWarning_ISig_ 600;
BA_REL_ "GenSigFirstTimeoutTime" BU_SG_REL_ CIOM SG_ 2515321892 TransferCaseNeutral_Ack 3000;
BA_REL_ "GenSigTimeoutTime" BU_SG_REL_ CIOM SG_ 2515321892 TransferCaseNeutral_Ack 600;
BA_REL_ "GenSigFirstTimeoutTime" BU_SG_REL_ HMIIOM SG_ 2515321892 Trailer1TPMPressureWarning_ISig_ 3000;
BA_REL_ "GenSigTimeoutTime" BU_SG_REL_ HMIIOM SG_ 2515321892 Trailer1TPMPressureWarning_ISig_ 600;
BA_REL_ "GenSigFirstTimeoutTime" BU_SG_REL_ HMIIOM SG_ 2515321892 Trailer1TPMLeakageWarning_ISig_4 3000;
BA_REL_ "GenSigTimeoutTime" BU_SG_REL_ HMIIOM SG_ 2515321892 Trailer1TPMLeakageWarning_ISig_4 600;
BA_REL_ "GenSigFirstTimeoutTime" BU_SG_REL_ HMIIOM SG_ 2515321892 LiftAxle1RequestResponse 3000;
BA_REL_ "GenSigTimeoutTime" BU_SG_REL_ HMIIOM SG_ 2515321892 LiftAxle1RequestResponse 600;
BA_REL_ "GenSigFirstTimeoutTime" BU_SG_REL_ HMIIOM SG_ 2515321892 TruckTPMPressureWarning_ISig_4 3000;
BA_REL_ "GenSigTimeoutTime" BU_SG_REL_ HMIIOM SG_ 2515321892 TruckTPMPressureWarning_ISig_4 600;
BA_REL_ "GenSigFirstTimeoutTime" BU_SG_REL_ BBM SG_ 2515321892 XRSLIndication 3000;
BA_REL_ "GenSigTimeoutTime" BU_SG_REL_ BBM SG_ 2515321892 XRSLIndication 600;
BA_REL_ "GenSigFirstTimeoutTime" BU_SG_REL_ HMIIOM SG_ 2515321892 XRSLIndication 3000;
BA_REL_ "GenSigTimeoutTime" BU_SG_REL_ HMIIOM SG_ 2515321892 XRSLIndication 600;
BA_REL_ "GenSigFirstTimeoutTime" BU_SG_REL_ HMIIOM SG_ 2548840996 Trailer2TPMFailure_ISig_4 4800;
BA_REL_ "GenSigTimeoutTime" BU_SG_REL_ HMIIOM SG_ 2548840996 Trailer2TPMFailure_ISig_4 1200;
BA_REL_ "GenSigFirstTimeoutTime" BU_SG_REL_ HMIIOM SG_ 2548840996 TruckTPMTireInfo_Active_ISig_4 4800;
BA_REL_ "GenSigTimeoutTime" BU_SG_REL_ HMIIOM SG_ 2548840996 TruckTPMTireInfo_Active_ISig_4 1200;
BA_REL_ "GenSigFirstTimeoutTime" BU_SG_REL_ HMIIOM SG_ 2548840996 TruckTPMFailure_ISig_4 4800;
BA_REL_ "GenSigTimeoutTime" BU_SG_REL_ HMIIOM SG_ 2548840996 TruckTPMFailure_ISig_4 1200;
BA_REL_ "GenSigFirstTimeoutTime" BU_SG_REL_ HMIIOM SG_ 2548840996 TruckTPMTireInfo_TireId_ISig_4 4800;
BA_REL_ "GenSigTimeoutTime" BU_SG_REL_ HMIIOM SG_ 2548840996 TruckTPMTireInfo_TireId_ISig_4 1200;
BA_REL_ "GenSigFirstTimeoutTime" BU_SG_REL_ HMIIOM SG_ 2548840996 TruckTPMTireInfo_Battery_ISig_4 4800;
BA_REL_ "GenSigTimeoutTime" BU_SG_REL_ HMIIOM SG_ 2548840996 TruckTPMTireInfo_Battery_ISig_4 1200;
BA_REL_ "GenSigFirstTimeoutTime" BU_SG_REL_ HMIIOM SG_ 2548840996 TruckTPMTireInfo_Temperature_ISi 4800;
BA_REL_ "GenSigTimeoutTime" BU_SG_REL_ HMIIOM SG_ 2548840996 TruckTPMTireInfo_Temperature_ISi 1200;
BA_REL_ "GenSigFirstTimeoutTime" BU_SG_REL_ HMIIOM SG_ 2548840996 TruckTPMTireInfo_RefPres_ISig_4 4800;
BA_REL_ "GenSigTimeoutTime" BU_SG_REL_ HMIIOM SG_ 2548840996 TruckTPMTireInfo_RefPres_ISig_4 1200;
BA_REL_ "GenSigFirstTimeoutTime" BU_SG_REL_ HMIIOM SG_ 2548840996 TPMTrailerPositionStat_ISig_4 4800;
BA_REL_ "GenSigTimeoutTime" BU_SG_REL_ HMIIOM SG_ 2548840996 TPMTrailerPositionStat_ISig_4 1200;
BA_REL_ "GenSigFirstTimeoutTime" BU_SG_REL_ HMIIOM SG_ 2548840996 TruckTPMTireInfo_Pressure_ISig_4 4800;
BA_REL_ "GenSigTimeoutTime" BU_SG_REL_ HMIIOM SG_ 2548840996 TruckTPMTireInfo_Pressure_ISig_4 1200;
BA_REL_ "GenSigFirstTimeoutTime" BU_SG_REL_ HMIIOM SG_ 2548840996 Trailer1TPMFailure_ISig_4 4800;
BA_REL_ "GenSigTimeoutTime" BU_SG_REL_ HMIIOM SG_ 2548840996 Trailer1TPMFailure_ISig_4 1200;
BA_REL_ "GenSigFirstTimeoutTime" BU_SG_REL_ HMIIOM SG_ 2548840996 TruckTPMTireInfo_PresWarn_ISig_4 4800;
BA_REL_ "GenSigTimeoutTime" BU_SG_REL_ HMIIOM SG_ 2548840996 TruckTPMTireInfo_PresWarn_ISig_4 1200;
BA_REL_ "GenSigFirstTimeoutTime" BU_SG_REL_ HMIIOM SG_ 2548840996 TruckTPMTireInfo_LeakageWarn_ISi 4800;
BA_REL_ "GenSigTimeoutTime" BU_SG_REL_ HMIIOM SG_ 2548840996 TruckTPMTireInfo_LeakageWarn_ISi 1200;
BA_REL_ "GenSigFirstTimeoutTime" BU_SG_REL_ HMIIOM SG_ 2548836388 Trailer2TPMTireInfo_LeakageWarn_ 4800;
BA_REL_ "GenSigTimeoutTime" BU_SG_REL_ HMIIOM SG_ 2548836388 Trailer2TPMTireInfo_LeakageWarn_ 1200;
BA_REL_ "GenSigFirstTimeoutTime" BU_SG_REL_ HMIIOM SG_ 2548836388 Trailer2TPMTireInfo_RefPres_ISig 4800;
BA_REL_ "GenSigTimeoutTime" BU_SG_REL_ HMIIOM SG_ 2548836388 Trailer2TPMTireInfo_RefPres_ISig 1200;
BA_REL_ "GenSigFirstTimeoutTime" BU_SG_REL_ HMIIOM SG_ 2548836388 Trailer2TPMTireInfo_PresWarn_ISi 4800;
BA_REL_ "GenSigTimeoutTime" BU_SG_REL_ HMIIOM SG_ 2548836388 Trailer2TPMTireInfo_PresWarn_ISi 1200;
BA_REL_ "GenSigFirstTimeoutTime" BU_SG_REL_ HMIIOM SG_ 2548836388 Trailer2TPMTireInfo_Pressure_ISi 4800;
BA_REL_ "GenSigTimeoutTime" BU_SG_REL_ HMIIOM SG_ 2548836388 Trailer2TPMTireInfo_Pressure_ISi 1200;
BA_REL_ "GenSigFirstTimeoutTime" BU_SG_REL_ HMIIOM SG_ 2548836388 Trailer2TPMTireInfo_Temperature_ 4800;
BA_REL_ "GenSigTimeoutTime" BU_SG_REL_ HMIIOM SG_ 2548836388 Trailer2TPMTireInfo_Temperature_ 1200;
BA_REL_ "GenSigFirstTimeoutTime" BU_SG_REL_ HMIIOM SG_ 2548836388 Trailer2TPMTireInfo_TireId_ISig_ 4800;
BA_REL_ "GenSigTimeoutTime" BU_SG_REL_ HMIIOM SG_ 2548836388 Trailer2TPMTireInfo_TireId_ISig_ 1200;
BA_REL_ "GenSigFirstTimeoutTime" BU_SG_REL_ HMIIOM SG_ 2548836388 Trailer2TPMTireInfo_Battery_ISig 4800;
BA_REL_ "GenSigTimeoutTime" BU_SG_REL_ HMIIOM SG_ 2548836388 Trailer2TPMTireInfo_Battery_ISig 1200;
BA_REL_ "GenSigFirstTimeoutTime" BU_SG_REL_ HMIIOM SG_ 2548836388 Trailer2TPMTireInfo_Active_ISig_ 4800;
BA_REL_ "GenSigTimeoutTime" BU_SG_REL_ HMIIOM SG_ 2548836388 Trailer2TPMTireInfo_Active_ISig_ 1200;
BA_REL_ "GenSigFirstTimeoutTime" BU_SG_REL_ HMIIOM SG_ 2548835620 Trailer1TPMTireInfo_Battery_ISig 4800;
BA_REL_ "GenSigTimeoutTime" BU_SG_REL_ HMIIOM SG_ 2548835620 Trailer1TPMTireInfo_Battery_ISig 1200;
BA_REL_ "GenSigFirstTimeoutTime" BU_SG_REL_ HMIIOM SG_ 2548835620 Trailer1TPMTireInfo_Pressure_ISi 4800;
BA_REL_ "GenSigTimeoutTime" BU_SG_REL_ HMIIOM SG_ 2548835620 Trailer1TPMTireInfo_Pressure_ISi 1200;
BA_REL_ "GenSigFirstTimeoutTime" BU_SG_REL_ HMIIOM SG_ 2548835620 Trailer1TPMTireInfo_PresWarn_ISi 4800;
BA_REL_ "GenSigTimeoutTime" BU_SG_REL_ HMIIOM SG_ 2548835620 Trailer1TPMTireInfo_PresWarn_ISi 1200;
BA_REL_ "GenSigFirstTimeoutTime" BU_SG_REL_ HMIIOM SG_ 2548835620 Trailer1TPMTireInfo_LeakageWarn_ 4800;
BA_REL_ "GenSigTimeoutTime" BU_SG_REL_ HMIIOM SG_ 2548835620 Trailer1TPMTireInfo_LeakageWarn_ 1200;
BA_REL_ "GenSigFirstTimeoutTime" BU_SG_REL_ HMIIOM SG_ 2548835620 TPMPosOfWMResp_VehiclePos_ISig_4 4800;
BA_REL_ "GenSigTimeoutTime" BU_SG_REL_ HMIIOM SG_ 2548835620 TPMPosOfWMResp_VehiclePos_ISig_4 1200;
BA_REL_ "GenSigFirstTimeoutTime" BU_SG_REL_ HMIIOM SG_ 2548835620 Trailer1TPMTireInfo_TireId_ISig_ 4800;
BA_REL_ "GenSigTimeoutTime" BU_SG_REL_ HMIIOM SG_ 2548835620 Trailer1TPMTireInfo_TireId_ISig_ 1200;
BA_REL_ "GenSigFirstTimeoutTime" BU_SG_REL_ HMIIOM SG_ 2548835620 Trailer1TPMTireInfo_RefPres_ISig 4800;
BA_REL_ "GenSigTimeoutTime" BU_SG_REL_ HMIIOM SG_ 2548835620 Trailer1TPMTireInfo_RefPres_ISig 1200;
BA_REL_ "GenSigFirstTimeoutTime" BU_SG_REL_ HMIIOM SG_ 2548835620 Trailer1TPMTireInfo_Temperature_ 4800;
BA_REL_ "GenSigTimeoutTime" BU_SG_REL_ HMIIOM SG_ 2548835620 Trailer1TPMTireInfo_Temperature_ 1200;
BA_REL_ "GenSigFirstTimeoutTime" BU_SG_REL_ HMIIOM SG_ 2548835620 Trailer1TPMTireInfo_Active_ISig_ 4800;
BA_REL_ "GenSigTimeoutTime" BU_SG_REL_ HMIIOM SG_ 2548835620 Trailer1TPMTireInfo_Active_ISig_ 1200;
BA_REL_ "GenSigFirstTimeoutTime" BU_SG_REL_ HMIIOM SG_ 2548835620 TPMPosOfWMResp_Status_ISig_4 4800;
BA_REL_ "GenSigTimeoutTime" BU_SG_REL_ HMIIOM SG_ 2548835620 TPMPosOfWMResp_Status_ISig_4 1200;
BA_REL_ "GenSigFirstTimeoutTime" BU_SG_REL_ HMIIOM SG_ 2548835620 TPMPosOfWMResp_TireId_ISig_4 4800;
BA_REL_ "GenSigTimeoutTime" BU_SG_REL_ HMIIOM SG_ 2548835620 TPMPosOfWMResp_TireId_ISig_4 1200;
BA_REL_ "GenSigFirstTimeoutTime" BU_SG_REL_ HMIIOM SG_ 2566358564 TruckTPMThresCfg_OverPres_ISig_4 24000;
BA_REL_ "GenSigTimeoutTime" BU_SG_REL_ HMIIOM SG_ 2566358564 TruckTPMThresCfg_OverPres_ISig_4 6000;
BA_REL_ "GenSigFirstTimeoutTime" BU_SG_REL_ HMIIOM SG_ 2566358564 TruckTPMAxlTireCfg_Axle2_ISig_4 24000;
BA_REL_ "GenSigTimeoutTime" BU_SG_REL_ HMIIOM SG_ 2566358564 TruckTPMAxlTireCfg_Axle2_ISig_4 6000;
BA_REL_ "GenSigFirstTimeoutTime" BU_SG_REL_ HMIIOM SG_ 2566358564 TruckTPMAxlTireCfg_Axle1_ISig_4 24000;
BA_REL_ "GenSigTimeoutTime" BU_SG_REL_ HMIIOM SG_ 2566358564 TruckTPMAxlTireCfg_Axle1_ISig_4 6000;
BA_REL_ "GenSigFirstTimeoutTime" BU_SG_REL_ HMIIOM SG_ 2566358564 TruckTPMAxlTireCfg_Axle5_ISig_4 24000;
BA_REL_ "GenSigTimeoutTime" BU_SG_REL_ HMIIOM SG_ 2566358564 TruckTPMAxlTireCfg_Axle5_ISig_4 6000;
BA_REL_ "GenSigFirstTimeoutTime" BU_SG_REL_ HMIIOM SG_ 2566358564 TruckTPMAxlTireCfg_Axle4_ISig_4 24000;
BA_REL_ "GenSigTimeoutTime" BU_SG_REL_ HMIIOM SG_ 2566358564 TruckTPMAxlTireCfg_Axle4_ISig_4 6000;
BA_REL_ "GenSigFirstTimeoutTime" BU_SG_REL_ HMIIOM SG_ 2566358564 TruckTPMThresCfg_ExtUnderPres_IS 24000;
BA_REL_ "GenSigTimeoutTime" BU_SG_REL_ HMIIOM SG_ 2566358564 TruckTPMThresCfg_ExtUnderPres_IS 6000;
BA_REL_ "GenSigFirstTimeoutTime" BU_SG_REL_ HMIIOM SG_ 2566358564 TruckTPMThresCfg_AxleNr_ISig_4 24000;
BA_REL_ "GenSigTimeoutTime" BU_SG_REL_ HMIIOM SG_ 2566358564 TruckTPMThresCfg_AxleNr_ISig_4 6000;
BA_REL_ "GenSigFirstTimeoutTime" BU_SG_REL_ HMIIOM SG_ 2566358564 TruckTPMThresCfg_UnderPres_ISig_ 24000;
BA_REL_ "GenSigTimeoutTime" BU_SG_REL_ HMIIOM SG_ 2566358564 TruckTPMThresCfg_UnderPres_ISig_ 6000;
BA_REL_ "GenSigFirstTimeoutTime" BU_SG_REL_ HMIIOM SG_ 2566358564 TruckTPMThresCfg_ExtOverPres_ISi 24000;
BA_REL_ "GenSigTimeoutTime" BU_SG_REL_ HMIIOM SG_ 2566358564 TruckTPMThresCfg_ExtOverPres_ISi 6000;
BA_REL_ "GenSigFirstTimeoutTime" BU_SG_REL_ HMIIOM SG_ 2566358564 TruckTPMAxlTireCfg_Axle3_ISig_4 24000;
BA_REL_ "GenSigTimeoutTime" BU_SG_REL_ HMIIOM SG_ 2566358564 TruckTPMAxlTireCfg_Axle3_ISig_4 6000;
BA_REL_ "GenSigFirstTimeoutTime" BU_SG_REL_ HMIIOM SG_ 2566358052 Trailer2TPMType_ISig_4 24000;
BA_REL_ "GenSigTimeoutTime" BU_SG_REL_ HMIIOM SG_ 2566358052 Trailer2TPMType_ISig_4 6000;
BA_REL_ "GenSigFirstTimeoutTime" BU_SG_REL_ HMIIOM SG_ 2566358052 Trailer2TPMAxlTireCfg_Axle1_ISig 24000;
BA_REL_ "GenSigTimeoutTime" BU_SG_REL_ HMIIOM SG_ 2566358052 Trailer2TPMAxlTireCfg_Axle1_ISig 6000;
BA_REL_ "GenSigFirstTimeoutTime" BU_SG_REL_ HMIIOM SG_ 2566358052 Trailer2TPMThresCfg_OverPres_ISi 24000;
BA_REL_ "GenSigTimeoutTime" BU_SG_REL_ HMIIOM SG_ 2566358052 Trailer2TPMThresCfg_OverPres_ISi 6000;
BA_REL_ "GenSigFirstTimeoutTime" BU_SG_REL_ HMIIOM SG_ 2566358052 Trailer2TPMAxlTireCfg_Axle3_ISig 24000;
BA_REL_ "GenSigTimeoutTime" BU_SG_REL_ HMIIOM SG_ 2566358052 Trailer2TPMAxlTireCfg_Axle3_ISig 6000;
BA_REL_ "GenSigFirstTimeoutTime" BU_SG_REL_ HMIIOM SG_ 2566358052 Trailer2TPMAxlTireCfg_Axle2_ISig 24000;
BA_REL_ "GenSigTimeoutTime" BU_SG_REL_ HMIIOM SG_ 2566358052 Trailer2TPMAxlTireCfg_Axle2_ISig 6000;
BA_REL_ "GenSigFirstTimeoutTime" BU_SG_REL_ HMIIOM SG_ 2566358052 Trailer2TPMAxlTireCfg_Axle5_ISig 24000;
BA_REL_ "GenSigTimeoutTime" BU_SG_REL_ HMIIOM SG_ 2566358052 Trailer2TPMAxlTireCfg_Axle5_ISig 6000;
BA_REL_ "GenSigFirstTimeoutTime" BU_SG_REL_ HMIIOM SG_ 2566358052 Trailer2TPMAxlTireCfg_Axle4_ISig 24000;
BA_REL_ "GenSigTimeoutTime" BU_SG_REL_ HMIIOM SG_ 2566358052 Trailer2TPMAxlTireCfg_Axle4_ISig 6000;
BA_REL_ "GenSigFirstTimeoutTime" BU_SG_REL_ HMIIOM SG_ 2566358052 Trailer2TPMThresCfg_AxleNr_ISig_ 24000;
BA_REL_ "GenSigTimeoutTime" BU_SG_REL_ HMIIOM SG_ 2566358052 Trailer2TPMThresCfg_AxleNr_ISig_ 6000;
BA_REL_ "GenSigFirstTimeoutTime" BU_SG_REL_ HMIIOM SG_ 2566358052 Trailer2TPMThresCfg_ExtOverPres_ 24000;
BA_REL_ "GenSigTimeoutTime" BU_SG_REL_ HMIIOM SG_ 2566358052 Trailer2TPMThresCfg_ExtOverPres_ 6000;
BA_REL_ "GenSigFirstTimeoutTime" BU_SG_REL_ HMIIOM SG_ 2566358052 Trailer2TPMThresCfg_UnderPres_IS 24000;
BA_REL_ "GenSigTimeoutTime" BU_SG_REL_ HMIIOM SG_ 2566358052 Trailer2TPMThresCfg_UnderPres_IS 6000;
BA_REL_ "GenSigFirstTimeoutTime" BU_SG_REL_ HMIIOM SG_ 2566358052 Trailer2TPMThresCfg_ExtUnderPres 24000;
BA_REL_ "GenSigTimeoutTime" BU_SG_REL_ HMIIOM SG_ 2566358052 Trailer2TPMThresCfg_ExtUnderPres 6000;
BA_REL_ "GenSigFirstTimeoutTime" BU_SG_REL_ HMIIOM SG_ 2566357540 Trailer1TPMAxlTireCfg_Axle1_ISig 24000;
BA_REL_ "GenSigTimeoutTime" BU_SG_REL_ HMIIOM SG_ 2566357540 Trailer1TPMAxlTireCfg_Axle1_ISig 6000;
BA_REL_ "GenSigFirstTimeoutTime" BU_SG_REL_ HMIIOM SG_ 2566357540 Trailer1TPMThresCfg_ExtOverPres_ 24000;
BA_REL_ "GenSigTimeoutTime" BU_SG_REL_ HMIIOM SG_ 2566357540 Trailer1TPMThresCfg_ExtOverPres_ 6000;
BA_REL_ "GenSigFirstTimeoutTime" BU_SG_REL_ HMIIOM SG_ 2566357540 Trailer1TPMAxlTireCfg_Axle2_ISig 24000;
BA_REL_ "GenSigTimeoutTime" BU_SG_REL_ HMIIOM SG_ 2566357540 Trailer1TPMAxlTireCfg_Axle2_ISig 6000;
BA_REL_ "GenSigFirstTimeoutTime" BU_SG_REL_ HMIIOM SG_ 2566357540 Trailer1TPMThresCfg_OverPres_ISi 24000;
BA_REL_ "GenSigTimeoutTime" BU_SG_REL_ HMIIOM SG_ 2566357540 Trailer1TPMThresCfg_OverPres_ISi 6000;
BA_REL_ "GenSigFirstTimeoutTime" BU_SG_REL_ HMIIOM SG_ 2566357540 Trailer1TPMAxlTireCfg_Axle5_ISig 24000;
BA_REL_ "GenSigTimeoutTime" BU_SG_REL_ HMIIOM SG_ 2566357540 Trailer1TPMAxlTireCfg_Axle5_ISig 6000;
BA_REL_ "GenSigFirstTimeoutTime" BU_SG_REL_ HMIIOM SG_ 2566357540 Trailer1TPMType_ISig_4 24000;
BA_REL_ "GenSigTimeoutTime" BU_SG_REL_ HMIIOM SG_ 2566357540 Trailer1TPMType_ISig_4 6000;
BA_REL_ "GenSigFirstTimeoutTime" BU_SG_REL_ HMIIOM SG_ 2566357540 Trailer1TPMThresCfg_UnderPres_IS 24000;
BA_REL_ "GenSigTimeoutTime" BU_SG_REL_ HMIIOM SG_ 2566357540 Trailer1TPMThresCfg_UnderPres_IS 6000;
BA_REL_ "GenSigFirstTimeoutTime" BU_SG_REL_ HMIIOM SG_ 2566357540 Trailer1TPMThresCfg_ExtUnderPres 24000;
BA_REL_ "GenSigTimeoutTime" BU_SG_REL_ HMIIOM SG_ 2566357540 Trailer1TPMThresCfg_ExtUnderPres 6000;
BA_REL_ "GenSigFirstTimeoutTime" BU_SG_REL_ HMIIOM SG_ 2566357540 Trailer1TPMThresCfg_AxleNr_ISig_ 24000;
BA_REL_ "GenSigTimeoutTime" BU_SG_REL_ HMIIOM SG_ 2566357540 Trailer1TPMThresCfg_AxleNr_ISig_ 6000;
BA_REL_ "GenSigFirstTimeoutTime" BU_SG_REL_ HMIIOM SG_ 2566357540 MaintResetFailureCause 24000;
BA_REL_ "GenSigTimeoutTime" BU_SG_REL_ HMIIOM SG_ 2566357540 MaintResetFailureCause 6000;
BA_REL_ "GenSigFirstTimeoutTime" BU_SG_REL_ HMIIOM SG_ 2566357540 Trailer1TPMAxlTireCfg_Axle4_ISig 24000;
BA_REL_ "GenSigTimeoutTime" BU_SG_REL_ HMIIOM SG_ 2566357540 Trailer1TPMAxlTireCfg_Axle4_ISig 6000;
BA_REL_ "GenSigFirstTimeoutTime" BU_SG_REL_ HMIIOM SG_ 2566357540 Trailer1TPMAxlTireCfg_Axle3_ISig 24000;
BA_REL_ "GenSigTimeoutTime" BU_SG_REL_ HMIIOM SG_ 2566357540 Trailer1TPMAxlTireCfg_Axle3_ISig 6000;
BA_REL_ "GenSigFirstTimeoutTime" BU_SG_REL_ HMIIOM SG_ 2566357028 FuseAndRelayFault_ItemNoD2 24000;
BA_REL_ "GenSigTimeoutTime" BU_SG_REL_ HMIIOM SG_ 2566357028 FuseAndRelayFault_ItemNoD2 6000;
BA_REL_ "GenSigFirstTimeoutTime" BU_SG_REL_ HMIIOM SG_ 2566357028 FuseAndRelayFault_ItemNoD1 24000;
BA_REL_ "GenSigTimeoutTime" BU_SG_REL_ HMIIOM SG_ 2566357028 FuseAndRelayFault_ItemNoD1 6000;
BA_REL_ "GenSigFirstTimeoutTime" BU_SG_REL_ HMIIOM SG_ 2566357028 FuseAndRelayFault_ItemNoC2 24000;
BA_REL_ "GenSigTimeoutTime" BU_SG_REL_ HMIIOM SG_ 2566357028 FuseAndRelayFault_ItemNoC2 6000;
BA_REL_ "GenSigFirstTimeoutTime" BU_SG_REL_ HMIIOM SG_ 2566357028 FuseAndRelayFault_ItemNoB2 24000;
BA_REL_ "GenSigTimeoutTime" BU_SG_REL_ HMIIOM SG_ 2566357028 FuseAndRelayFault_ItemNoB2 6000;
BA_REL_ "GenSigFirstTimeoutTime" BU_SG_REL_ HMIIOM SG_ 2566357028 FuseAndRelayFault_TypeD 24000;
BA_REL_ "GenSigTimeoutTime" BU_SG_REL_ HMIIOM SG_ 2566357028 FuseAndRelayFault_TypeD 6000;
BA_REL_ "GenSigFirstTimeoutTime" BU_SG_REL_ HMIIOM SG_ 2566357028 FuseAndRelayFault_TypeB 24000;
BA_REL_ "GenSigTimeoutTime" BU_SG_REL_ HMIIOM SG_ 2566357028 FuseAndRelayFault_TypeB 6000;
BA_REL_ "GenSigFirstTimeoutTime" BU_SG_REL_ HMIIOM SG_ 2566357028 FuseAndRelayFault_TypeA 24000;
BA_REL_ "GenSigTimeoutTime" BU_SG_REL_ HMIIOM SG_ 2566357028 FuseAndRelayFault_TypeA 6000;
BA_REL_ "GenSigFirstTimeoutTime" BU_SG_REL_ HMIIOM SG_ 2566357028 FuseAndRelayFault_ItemNoA1 24000;
BA_REL_ "GenSigTimeoutTime" BU_SG_REL_ HMIIOM SG_ 2566357028 FuseAndRelayFault_ItemNoA1 6000;
BA_REL_ "GenSigFirstTimeoutTime" BU_SG_REL_ HMIIOM SG_ 2566357028 FuseAndRelayFault_ItemNoA2 24000;
BA_REL_ "GenSigTimeoutTime" BU_SG_REL_ HMIIOM SG_ 2566357028 FuseAndRelayFault_ItemNoA2 6000;
BA_REL_ "GenSigFirstTimeoutTime" BU_SG_REL_ HMIIOM SG_ 2566357028 FuseAndRelayFault_ItemNoB1 24000;
BA_REL_ "GenSigTimeoutTime" BU_SG_REL_ HMIIOM SG_ 2566357028 FuseAndRelayFault_ItemNoB1 6000;
BA_REL_ "GenSigFirstTimeoutTime" BU_SG_REL_ HMIIOM SG_ 2566357028 FuseAndRelayFault_ItemNoC1 24000;
BA_REL_ "GenSigTimeoutTime" BU_SG_REL_ HMIIOM SG_ 2566357028 FuseAndRelayFault_ItemNoC1 6000;
BA_REL_ "GenSigFirstTimeoutTime" BU_SG_REL_ HMIIOM SG_ 2566357028 FuseAndRelayFault_TypeC 24000;
BA_REL_ "GenSigTimeoutTime" BU_SG_REL_ HMIIOM SG_ 2566357028 FuseAndRelayFault_TypeC 6000;
BA_REL_ "GenSigFirstTimeoutTime" BU_SG_REL_ HMIIOM SG_ 2566895652 DistToEmptyLNG_ISig_4 24000;
BA_REL_ "GenSigTimeoutTime" BU_SG_REL_ HMIIOM SG_ 2566895652 DistToEmptyLNG_ISig_4 6000;
BA_REL_ "GenSigFirstTimeoutTime" BU_SG_REL_ HMIIOM SG_ 2566895652 DistToEmptyDiesel_ISig_4 24000;
BA_REL_ "GenSigTimeoutTime" BU_SG_REL_ HMIIOM SG_ 2566895652 DistToEmptyDiesel_ISig_4 6000;
BA_REL_ "GenSigFirstTimeoutTime" BU_SG_REL_ HMIIOM SG_ 2566895652 CoastingUseDistance_ISig_4 24000;
BA_REL_ "GenSigTimeoutTime" BU_SG_REL_ HMIIOM SG_ 2566895652 CoastingUseDistance_ISig_4 6000;
BA_REL_ "GenSigFirstTimeoutTime" BU_SG_REL_ HMIIOM SG_ 2566894884 EngSpeedOverThresholdTime_ISig_4 24000;
BA_REL_ "GenSigTimeoutTime" BU_SG_REL_ HMIIOM SG_ 2566894884 EngSpeedOverThresholdTime_ISig_4 6000;
BA_REL_ "GenSigFirstTimeoutTime" BU_SG_REL_ HMIIOM SG_ 2566894884 EngLoadOverThresholdDistance_ISi 24000;
BA_REL_ "GenSigTimeoutTime" BU_SG_REL_ HMIIOM SG_ 2566894884 EngLoadOverThresholdDistance_ISi 6000;
BA_REL_ "GenSigFirstTimeoutTime" BU_SG_REL_ HMIIOM SG_ 2566894372 EngineGreenAreaFuel_ISig_4 24000;
BA_REL_ "GenSigTimeoutTime" BU_SG_REL_ HMIIOM SG_ 2566894372 EngineGreenAreaFuel_ISig_4 6000;
BA_REL_ "GenSigFirstTimeoutTime" BU_SG_REL_ HMIIOM SG_ 2566894372 LCCDistance_ISig_4 24000;
BA_REL_ "GenSigTimeoutTime" BU_SG_REL_ HMIIOM SG_ 2566894372 LCCDistance_ISig_4 6000;
BA_REL_ "GenSigFirstTimeoutTime" BU_SG_REL_ HMIIOM SG_ 2566893604 StopCounter_ISig_4 24000;
BA_REL_ "GenSigTimeoutTime" BU_SG_REL_ HMIIOM SG_ 2566893604 StopCounter_ISig_4 6000;
BA_REL_ "GenSigFirstTimeoutTime" BU_SG_REL_ HMIIOM SG_ 2566893604 OverspeedDistance_ISig_4 24000;
BA_REL_ "GenSigTimeoutTime" BU_SG_REL_ HMIIOM SG_ 2566893604 OverspeedDistance_ISig_4 6000;
BA_REL_ "GenSigFirstTimeoutTime" BU_SG_REL_ HMIIOM SG_ 2566892580 RobotizedGboxPowerModeTime_ISig_ 24000;
BA_REL_ "GenSigTimeoutTime" BU_SG_REL_ HMIIOM SG_ 2566892580 RobotizedGboxPowerModeTime_ISig_ 6000;
BA_REL_ "GenSigFirstTimeoutTime" BU_SG_REL_ HMIIOM SG_ 2566892580 TotalServiceBrakeCounter_ISig_4 24000;
BA_REL_ "GenSigTimeoutTime" BU_SG_REL_ HMIIOM SG_ 2566892580 TotalServiceBrakeCounter_ISig_4 6000;
BA_REL_ "GenSigFirstTimeoutTime" BU_SG_REL_ HMIIOM SG_ 2566892068 RobotizedGboxManualModeTime_ISig 24000;
BA_REL_ "GenSigTimeoutTime" BU_SG_REL_ HMIIOM SG_ 2566892068 RobotizedGboxManualModeTime_ISig 6000;
BA_REL_ "GenSigFirstTimeoutTime" BU_SG_REL_ HMIIOM SG_ 2566892068 RobotizedGboxAutoModeTime_ISig_4 24000;
BA_REL_ "GenSigTimeoutTime" BU_SG_REL_ HMIIOM SG_ 2566892068 RobotizedGboxAutoModeTime_ISig_4 6000;
BA_REL_ "GenSigFirstTimeoutTime" BU_SG_REL_ HMIIOM SG_ 2548897828 PusherAxleLoad_ISig_4 6000;
BA_REL_ "GenSigTimeoutTime" BU_SG_REL_ HMIIOM SG_ 2548897828 PusherAxleLoad_ISig_4 1500;
BA_REL_ "GenSigFirstTimeoutTime" BU_SG_REL_ TECU SG_ 2548897828 PusherAxleLoad_ISig_4 6000;
BA_REL_ "GenSigTimeoutTime" BU_SG_REL_ TECU SG_ 2548897828 PusherAxleLoad_ISig_4 1500;
BA_REL_ "GenSigFirstTimeoutTime" BU_SG_REL_ BBM SG_ 2548897828 PusherAxleLoad_ISig_4 6000;
BA_REL_ "GenSigTimeoutTime" BU_SG_REL_ BBM SG_ 2548897828 PusherAxleLoad_ISig_4 1500;
BA_REL_ "GenSigFirstTimeoutTime" BU_SG_REL_ DACU SG_ 2548897828 PusherAxleLoad_ISig_4 6000;
BA_REL_ "GenSigTimeoutTime" BU_SG_REL_ DACU SG_ 2548897828 PusherAxleLoad_ISig_4 1500;
BA_REL_ "GenSigFirstTimeoutTime" BU_SG_REL_ BBM SG_ 2548897828 FogLight_Front_cmd_ISig_4 6000;
BA_REL_ "GenSigTimeoutTime" BU_SG_REL_ BBM SG_ 2548897828 FogLight_Front_cmd_ISig_4 1500;
BA_REL_ "GenSigFirstTimeoutTime" BU_SG_REL_ TECU SG_ 2548897828 TagAxleLoad_ISig_4 6000;
BA_REL_ "GenSigTimeoutTime" BU_SG_REL_ TECU SG_ 2548897828 TagAxleLoad_ISig_4 1500;
BA_REL_ "GenSigFirstTimeoutTime" BU_SG_REL_ DACU SG_ 2548897828 TagAxleLoad_ISig_4 6000;
BA_REL_ "GenSigTimeoutTime" BU_SG_REL_ DACU SG_ 2548897828 TagAxleLoad_ISig_4 1500;
BA_REL_ "GenSigFirstTimeoutTime" BU_SG_REL_ BBM SG_ 2548897828 TagAxleLoad_ISig_4 6000;
BA_REL_ "GenSigTimeoutTime" BU_SG_REL_ BBM SG_ 2548897828 TagAxleLoad_ISig_4 1500;
BA_REL_ "GenSigFirstTimeoutTime" BU_SG_REL_ HMIIOM SG_ 2548897828 TagAxleLoad_ISig_4 6000;
BA_REL_ "GenSigTimeoutTime" BU_SG_REL_ HMIIOM SG_ 2548897828 TagAxleLoad_ISig_4 1500;
BA_REL_ "GenSigFirstTimeoutTime" BU_SG_REL_ BBM SG_ 2548897060 DriveAxleLoad_ISig_4 6000;
BA_REL_ "GenSigTimeoutTime" BU_SG_REL_ BBM SG_ 2548897060 DriveAxleLoad_ISig_4 1500;
BA_REL_ "GenSigFirstTimeoutTime" BU_SG_REL_ DACU SG_ 2548897060 DriveAxleLoad_ISig_4 6000;
BA_REL_ "GenSigTimeoutTime" BU_SG_REL_ DACU SG_ 2548897060 DriveAxleLoad_ISig_4 1500;
BA_REL_ "GenSigFirstTimeoutTime" BU_SG_REL_ HMIIOM SG_ 2548897060 DriveAxleLoad_ISig_4 6000;
BA_REL_ "GenSigTimeoutTime" BU_SG_REL_ HMIIOM SG_ 2548897060 DriveAxleLoad_ISig_4 1500;
BA_REL_ "GenSigFirstTimeoutTime" BU_SG_REL_ TECU SG_ 2548897060 DriveAxleLoad_ISig_4 6000;
BA_REL_ "GenSigTimeoutTime" BU_SG_REL_ TECU SG_ 2548897060 DriveAxleLoad_ISig_4 1500;
BA_REL_ "GenSigFirstTimeoutTime" BU_SG_REL_ CIOM SG_ 2548897060 BatterySOCAlertRawData_rqst_ISig 6000;
BA_REL_ "GenSigTimeoutTime" BU_SG_REL_ CIOM SG_ 2548897060 BatterySOCAlertRawData_rqst_ISig 1500;
BA_REL_ "GenSigFirstTimeoutTime" BU_SG_REL_ BBM SG_ 2548897060 BatterySOCAlertRawData_rqst_ISig 6000;
BA_REL_ "GenSigTimeoutTime" BU_SG_REL_ BBM SG_ 2548897060 BatterySOCAlertRawData_rqst_ISig 1500;
BA_REL_ "GenSigFirstTimeoutTime" BU_SG_REL_ CIOM SG_ 2548897060 ShortStopHeater_status_ISig_4 6000;
BA_REL_ "GenSigTimeoutTime" BU_SG_REL_ CIOM SG_ 2548897060 ShortStopHeater_status_ISig_4 1500;
BA_REL_ "GenSigFirstTimeoutTime" BU_SG_REL_ HMIIOM SG_ 2548897060 SecondaryDriveAxleLoad_ISig_4 6000;
BA_REL_ "GenSigTimeoutTime" BU_SG_REL_ HMIIOM SG_ 2548897060 SecondaryDriveAxleLoad_ISig_4 1500;
BA_REL_ "GenSigFirstTimeoutTime" BU_SG_REL_ DACU SG_ 2548897060 SecondaryDriveAxleLoad_ISig_4 6000;
BA_REL_ "GenSigTimeoutTime" BU_SG_REL_ DACU SG_ 2548897060 SecondaryDriveAxleLoad_ISig_4 1500;
BA_REL_ "GenSigFirstTimeoutTime" BU_SG_REL_ BBM SG_ 2548897060 SecondaryDriveAxleLoad_ISig_4 6000;
BA_REL_ "GenSigTimeoutTime" BU_SG_REL_ BBM SG_ 2548897060 SecondaryDriveAxleLoad_ISig_4 1500;
BA_REL_ "GenSigFirstTimeoutTime" BU_SG_REL_ TECU SG_ 2548897060 SecondaryDriveAxleLoad_ISig_4 6000;
BA_REL_ "GenSigTimeoutTime" BU_SG_REL_ TECU SG_ 2548897060 SecondaryDriveAxleLoad_ISig_4 1500;
BA_REL_ "GenSigFirstTimeoutTime" BU_SG_REL_ HMIIOM SG_ 2548897060 LivBatDisconnectDetectStat_ISig_ 6000;
BA_REL_ "GenSigTimeoutTime" BU_SG_REL_ HMIIOM SG_ 2548897060 LivBatDisconnectDetectStat_ISig_ 1500;
BA_REL_ "GenSigFirstTimeoutTime" BU_SG_REL_ HMIIOM SG_ 2566365476 MaintService_ServiceCalendarTime 24000;
BA_REL_ "GenSigTimeoutTime" BU_SG_REL_ HMIIOM SG_ 2566365476 MaintService_ServiceCalendarTime 6000;
BA_REL_ "GenSigFirstTimeoutTime" BU_SG_REL_ HMIIOM SG_ 2566365476 MaintService_EngTimeID_ISig_4_18 24000;
BA_REL_ "GenSigTimeoutTime" BU_SG_REL_ HMIIOM SG_ 2566365476 MaintService_EngTimeID_ISig_4_18 6000;
BA_REL_ "GenSigFirstTimeoutTime" BU_SG_REL_ HMIIOM SG_ 2566365476 MaintService_DistID_ISig_4_18f7a 24000;
BA_REL_ "GenSigTimeoutTime" BU_SG_REL_ HMIIOM SG_ 2566365476 MaintService_DistID_ISig_4_18f7a 6000;
BA_REL_ "GenSigFirstTimeoutTime" BU_SG_REL_ HMIIOM SG_ 2566365476 MaintService_ServiceDistance_ISi 24000;
BA_REL_ "GenSigTimeoutTime" BU_SG_REL_ HMIIOM SG_ 2566365476 MaintService_ServiceDistance_ISi 6000;
BA_REL_ "GenSigFirstTimeoutTime" BU_SG_REL_ HMIIOM SG_ 2566365476 MaintService_ServiceEngineTime_I 24000;
BA_REL_ "GenSigTimeoutTime" BU_SG_REL_ HMIIOM SG_ 2566365476 MaintService_ServiceEngineTime_I 6000;
BA_REL_ "GenSigFirstTimeoutTime" BU_SG_REL_ HMIIOM SG_ 2566365476 MaintService_CalDateID_ISig_4_18 24000;
BA_REL_ "GenSigTimeoutTime" BU_SG_REL_ HMIIOM SG_ 2566365476 MaintService_CalDateID_ISig_4_18 6000;
BA_REL_ "GenSigFirstTimeoutTime" BU_SG_REL_ CIOM SG_ 2566357284 MaintService_ServiceEngineT_0000 24000;
BA_REL_ "GenSigTimeoutTime" BU_SG_REL_ CIOM SG_ 2566357284 MaintService_ServiceEngineT_0000 6000;
BA_REL_ "GenSigFirstTimeoutTime" BU_SG_REL_ CIOM SG_ 2566357284 MaintService_EngTimeID_ISig_0000 24000;
BA_REL_ "GenSigTimeoutTime" BU_SG_REL_ CIOM SG_ 2566357284 MaintService_EngTimeID_ISig_0000 6000;
BA_REL_ "GenSigFirstTimeoutTime" BU_SG_REL_ CIOM SG_ 2566357284 MaintService_DistID_ISig_4_18f78 24000;
BA_REL_ "GenSigTimeoutTime" BU_SG_REL_ CIOM SG_ 2566357284 MaintService_DistID_ISig_4_18f78 6000;
BA_REL_ "GenSigFirstTimeoutTime" BU_SG_REL_ CIOM SG_ 2566357284 MaintService_ServiceDistanc_0000 24000;
BA_REL_ "GenSigTimeoutTime" BU_SG_REL_ CIOM SG_ 2566357284 MaintService_ServiceDistanc_0000 6000;
BA_REL_ "GenSigFirstTimeoutTime" BU_SG_REL_ CIOM SG_ 2566357284 MaintService_CalDateID_ISig_0000 24000;
BA_REL_ "GenSigTimeoutTime" BU_SG_REL_ CIOM SG_ 2566357284 MaintService_CalDateID_ISig_0000 6000;
BA_REL_ "GenSigFirstTimeoutTime" BU_SG_REL_ CIOM SG_ 2566357284 MaintService_ServiceCalenda_0000 24000;
BA_REL_ "GenSigTimeoutTime" BU_SG_REL_ CIOM SG_ 2566357284 MaintService_ServiceCalenda_0000 6000;
BA_REL_ "GenSigFirstTimeoutTime" BU_SG_REL_ HMIIOM SG_ 2566821202 EngTrueIdleSpeedTime_ISig_4 24000;
BA_REL_ "GenSigTimeoutTime" BU_SG_REL_ HMIIOM SG_ 2566821202 EngTrueIdleSpeedTime_ISig_4 6000;
BA_REL_ "GenSigFirstTimeoutTime" BU_SG_REL_ HMIIOM SG_ 2566821202 EngineGreenAreaOutTime_ISig_4 24000;
BA_REL_ "GenSigTimeoutTime" BU_SG_REL_ HMIIOM SG_ 2566821202 EngineGreenAreaOutTime_ISig_4 6000;
BA_REL_ "GenSigFirstTimeoutTime" BU_SG_REL_ HMIIOM SG_ 2515845117 BatterySOCnom_ISig_4 3600;
BA_REL_ "GenSigTimeoutTime" BU_SG_REL_ HMIIOM SG_ 2515845117 BatterySOCnom_ISig_4 900;
BA_REL_ "GenSigFirstTimeoutTime" BU_SG_REL_ HMIIOM SG_ 2515845117 BatterySOH_ISig_4 3600;
BA_REL_ "GenSigTimeoutTime" BU_SG_REL_ HMIIOM SG_ 2515845117 BatterySOH_ISig_4 900;
BA_REL_ "GenSigFirstTimeoutTime" BU_SG_REL_ CIOM SG_ 2515845117 ReducedLoadMode_stat_ISig_4 3600;
BA_REL_ "GenSigTimeoutTime" BU_SG_REL_ CIOM SG_ 2515845117 ReducedLoadMode_stat_ISig_4 900;
BA_REL_ "GenSigFirstTimeoutTime" BU_SG_REL_ HMIIOM SG_ 2515845117 BatterySOCAlert_rqst_ISig_4 3600;
BA_REL_ "GenSigTimeoutTime" BU_SG_REL_ HMIIOM SG_ 2515845117 BatterySOCAlert_rqst_ISig_4 900;
BA_REL_ "GenSigFirstTimeoutTime" BU_SG_REL_ BBM SG_ 2515845117 BatterySOCAlert_rqst_ISig_4 3600;
BA_REL_ "GenSigTimeoutTime" BU_SG_REL_ BBM SG_ 2515845117 BatterySOCAlert_rqst_ISig_4 900;
BA_REL_ "GenSigFirstTimeoutTime" BU_SG_REL_ CIOM SG_ 2515845117 BatterySOCAlert_rqst_ISig_4 3600;
BA_REL_ "GenSigTimeoutTime" BU_SG_REL_ CIOM SG_ 2515845117 BatterySOCAlert_rqst_ISig_4 900;
BA_REL_ "GenSigFirstTimeoutTime" BU_SG_REL_ HMIIOM SG_ 2515845117 BatteryVoltageDisplayValue_ISig_ 3600;
BA_REL_ "GenSigTimeoutTime" BU_SG_REL_ HMIIOM SG_ 2515845117 BatteryVoltageDisplayValue_ISig_ 900;
BA_REL_ "GenSigFirstTimeoutTime" BU_SG_REL_ BBM SG_ 2515845117 BatteryVoltageDisplayValue_ISig_ 3600;
BA_REL_ "GenSigTimeoutTime" BU_SG_REL_ BBM SG_ 2515845117 BatteryVoltageDisplayValue_ISig_ 900;
BA_REL_ "GenSigFirstTimeoutTime" BU_SG_REL_ EMS SG_ 2515845117 BatteryCurrent_ISig_4 3600;
BA_REL_ "GenSigTimeoutTime" BU_SG_REL_ EMS SG_ 2515845117 BatteryCurrent_ISig_4 900;
BA_REL_ "GenSigFirstTimeoutTime" BU_SG_REL_ HMIIOM SG_ 2515845117 BatteryCurrent_ISig_4 3600;
BA_REL_ "GenSigTimeoutTime" BU_SG_REL_ HMIIOM SG_ 2515845117 BatteryCurrent_ISig_4 900;
BA_REL_ "GenSigFirstTimeoutTime" BU_SG_REL_ HMIIOM SG_ 2515845117 BatterySOF_ISig_4 3600;
BA_REL_ "GenSigTimeoutTime" BU_SG_REL_ HMIIOM SG_ 2515845117 BatterySOF_ISig_4 900;
VAL_ 2566078244 FrontConspicLamp_stat_HiLeft_ISi 7 "LampCheck_stat_NotAvailable" 6 "LampCheck_stat_Error" 5 "LampCheck_stat_Spare_02" 4 "LampCheck_stat_Spare_01" 3 "LampCheck_stat_Spare" 2 "LampCheck_stat_TestedLampNOK" 1 "LampCheck_stat_TestedLampOK" 0 "LampCheck_stat_NotTested" ;
VAL_ 2566078244 FrontConspicLamp_stat_LoRight_IS 7 "LampCheck_stat_NotAvailable" 6 "LampCheck_stat_Error" 5 "LampCheck_stat_Spare_02" 4 "LampCheck_stat_Spare_01" 3 "LampCheck_stat_Spare" 2 "LampCheck_stat_TestedLampNOK" 1 "LampCheck_stat_TestedLampOK" 0 "LampCheck_stat_NotTested" ;
VAL_ 2566078244 FrontConspicLamp_stat_LoLeft_ISi 7 "LampCheck_stat_NotAvailable" 6 "LampCheck_stat_Error" 5 "LampCheck_stat_Spare_02" 4 "LampCheck_stat_Spare_01" 3 "LampCheck_stat_Spare" 2 "LampCheck_stat_TestedLampNOK" 1 "LampCheck_stat_TestedLampOK" 0 "LampCheck_stat_NotTested" ;
VAL_ 2566078244 FrontConspicLamp_stat_HiRight_IS 7 "LampCheck_stat_NotAvailable" 6 "LampCheck_stat_Error" 5 "LampCheck_stat_Spare_02" 4 "LampCheck_stat_Spare_01" 3 "LampCheck_stat_Spare" 2 "LampCheck_stat_TestedLampNOK" 1 "LampCheck_stat_TestedLampOK" 0 "LampCheck_stat_NotTested" ;
VAL_ 2432663332 FASSaturated_ISig_4 3 "FASSaturated_NotAvailable" 2 "FASSaturated_Error" 1 "FASSaturated_FAS_IsSaturated" 0 "FASSaturated_FAS_IsNotSaturated" ;
VAL_ 2432663332 OverSteerGuidanceStatus_ISig_4 3 "InactiveActive_NotAvailable" 2 "InactiveActive_Error" 1 "InactiveActive_Active" 0 "InactiveActive_Inactive" ;
VAL_ 2432663332 FASFullyOperational_ISig_4 3 "FASFullyOperational_NotAvailable" 2 "FASFullyOperational_Error" 1 "FASFullyOperational_FASFullyOperational" 0 "FASFullyOperational_FASNotFullyOperational" ;
VAL_ 2432663332 FASFunctionInControl_ISig_4 3 "FASFunctionInControl_NotAvailable" 2 "FASFunctionInControl_Error" 1 "FASFunctionInControl_FunctionInControl" 0 "FASFunctionInControl_DriverInControl" ;
VAL_ 2566359844 ActualFasPersSettingsButton_ISig 7 "FasPersSettingsButton_NotAvailable" 6 "FasPersSettingsButton_Error" 5 "FasPersSettingsButton_Spare" 4 "FasPersSettingsButton_UserDefinedButton" 3 "FasPersSettingsButton_PresetButtonHeavy" 2 "FasPersSettingsButton_PresetButtonFirm" 1 "FasPersSettingsButton_PresetButtonLight" 0 "FasPersSettingsButton_PresetButtonDefault" ;
VAL_ 2566359844 FasDriver_ISig_4 15 "FasDriver_NotAvailable" 14 "FasDriver_Error" 13 "FasDriver_Spare3" 12 "FasDriver_Spare2" 11 "FasDriver_Spare1" 10 "FasDriver_Driver10" 9 "FasDriver_Driver9" 8 "FasDriver_Driver8" 7 "FasDriver_Driver7" 6 "FasDriver_Driver6" 5 "FasDriver_Driver5" 4 "FasDriver_Driver4" 3 "FasDriver_Driver3" 2 "FasDriver_Driver2" 1 "FasDriver_Driver1" 0 "FasDriver_DefaultDriver" ;
VAL_ 2481984804 PS_PosLightDoorOpen_ISig_4 3 "InactiveActiveSpare_NotAvailable" 2 "InactiveActiveSpare_Spare" 1 "InactiveActiveSpare_Active" 0 "InactiveActiveSpare_Inactive" ;
VAL_ 2481984804 PS_FogLightRear_ISig_4 3 "InactiveActiveSpare_NotAvailable" 2 "InactiveActiveSpare_Spare" 1 "InactiveActiveSpare_Active" 0 "InactiveActiveSpare_Inactive" ;
VAL_ 2481984804 TrailerBodyLampDI_stat 3 "PushButtonStatus_NotAvailable" 2 "PushButtonStatus_Error" 1 "PushButtonStatus_Pushed" 0 "PushButtonStatus_Neutral" ;
VAL_ 2481984804 ParkedLoadDistribution_ISig_4 7 "ParkedLoadDistribution_NotAvailable" 6 "ParkedLoadDistribution_Error" 5 "ParkedLoadDistribution_Spare3" 4 "ParkedLoadDistribution_Spare2" 3 "ParkedLoadDistribution_Spare1" 2 "ParkedLoadDistribution_ActiveLevelNotReached" 1 "ParkedLoadDistribution_ActiveLevelReached" 0 "ParkedLoadDistribution_Inactive" ;
VAL_ 2481984804 TrailerBodyLampFdbk_stat 3 "OffOn_NotAvailable" 2 "OffOn_Error" 1 "OffOn_On" 0 "OffOn_Off" ;
VAL_ 2481984804 PS_FogLightFront_ISig_4 3 "InactiveActiveSpare_NotAvailable" 2 "InactiveActiveSpare_Spare" 1 "InactiveActiveSpare_Active" 0 "InactiveActiveSpare_Inactive" ;
VAL_ 2481984804 DriverCrank_rqst_ISig_4 3 "Request_NotAvailable" 2 "Request_Error" 1 "Request_RequestActive" 0 "Request_NotRequested" ;
VAL_ 2481984804 PS_HeadLightAdjustment_ISig_4 3 "InactiveActiveSpare_NotAvailable" 2 "InactiveActiveSpare_Spare" 1 "InactiveActiveSpare_Active" 0 "InactiveActiveSpare_Inactive" ;
VAL_ 2481984804 PS_MainBeam_ISig_4 3 "PSOffOn_NotAvailable" 2 "PSOffOn_Spare" 1 "PSOffOn_On" 0 "PSOffOn_Off" ;
VAL_ 2481984804 FifthWheelHandleLock_ind_ISig_4 3 "UnlockedLocked_NotAvailable" 2 "UnlockedLocked_Error" 1 "UnlockedLocked_Locked" 0 "UnlockedLocked_Unlocked" ;
VAL_ 2481984804 InstFuel_VehicleMoving_ISig_4 3 "VehicleMoving_NotAvailable" 2 "VehicleMoving_Error" 1 "VehicleMoving_VehicleMoving" 0 "VehicleMoving_VehicleStopped" ;
VAL_ 2481984804 PS_AFSAllowedInDriveP_ISig_4 3 "InactiveActiveSpare_NotAvailable" 2 "InactiveActiveSpare_Spare" 1 "InactiveActiveSpare_Active" 0 "InactiveActiveSpare_Inactive" ;
VAL_ 2481984804 PS_AFS_ISig_4 7 "PS_AFS_NotAvailable" 6 "PS_AFS_Spare3" 5 "PS_AFS_Spare2" 4 "PS_AFS_Spare1" 3 "PS_AFS_AFS_ActiveGlareFreeAllowed" 2 "PS_AFS_AFS_ActiveMainBeamAllowed" 1 "PS_AFS_AFS_ActiveMainBeamNotAllowed" 0 "PS_AFS_AFS_NotActive" ;
VAL_ 2481984804 AC2CoolingFanControl_rqst 3 "Request_NotAvailable" 2 "Request_Error" 1 "Request_RequestActive" 0 "Request_NotRequested" ;
VAL_ 2481984804 DHCStatus 3 "InactiveActive_NotAvailable" 2 "InactiveActive_Error" 1 "InactiveActive_Active" 0 "InactiveActive_Inactive" ;
VAL_ 2481984804 PS_PositionLight_ISig_4 3 "OffOnSpare_NotAvailable" 2 "OffOnSpare_Spare" 1 "OffOnSpare_On" 0 "OffOnSpare_Off" ;
VAL_ 2516006692 EngOvrrideCtrlStat_FireTruckMode 3 "FireTruckMode_Spare4" 2 "FireTruckMode_Spare3" 1 "FireTruckMode_Spare2" 0 "FireTruckMode_Spare1" ;
VAL_ 2516006692 EngOvrrideCtrlStat_StartOvrrMode 3 "InactiveActive_NotAvailable" 2 "InactiveActive_Error" 1 "InactiveActive_Active" 0 "InactiveActive_Inactive" ;
VAL_ 2516006692 EngOvrrideCtrlStat_ProtOvrrMode 3 "InactiveActive_NotAvailable" 2 "InactiveActive_Error" 1 "InactiveActive_Active" 0 "InactiveActive_Inactive" ;
VAL_ 2515322916 BatteryTempAlert_rqst_ISig_4 7 "BatteryTempAlert_rqst_NotAvailable" 6 "BatteryTempAlert_rqst_Error" 5 "BatteryTempAlert_rqst_Spare3" 4 "BatteryTempAlert_rqst_Spare2" 3 "BatteryTempAlert_rqst_Spare1" 2 "BatteryTempAlert_rqst_CriticalAlertLowTemp" 1 "BatteryTempAlert_rqst_PreAlertLowTemp" 0 "BatteryTempAlert_rqst_NoAlertRequested" ;
VAL_ 2515322916 BatteryCapacity_ISig_4 15 "BatteryType_NotAvailable" 14 "BatteryType_Error" 13 "BatteryType_NoSelectionMade" 12 "BatteryType_OtherBatteryType" 11 "BatteryType_BatteryType11" 10 "BatteryType_BatteryType10" 9 "BatteryType_BatteryType9" 8 "BatteryType_BatteryType8" 7 "BatteryType_BatteryType7" 6 "BatteryType_BatteryType6" 5 "BatteryType_BatteryType5" 4 "BatteryType_BatteryType4" 3 "BatteryType_BatteryType3" 2 "BatteryType_BatteryType2" 1 "BatteryType_BatteryType1" 0 "BatteryType_BatteryType0" ;
VAL_ 2515322916 Hazard_rqst_ISig_4 3 "InactiveActive_NotAvailable" 2 "InactiveActive_Error" 1 "InactiveActive_Active" 0 "InactiveActive_Inactive" ;
VAL_ 2515322916 Trailer1TPMLostCom_ISig_4 3 "NoYes_NotAvailable" 2 "NoYes_Error" 1 "NoYes_Yes" 0 "NoYes_No" ;
VAL_ 2515322916 BatteryTempAlertRawData_rqst_ISi 7 "BatteryTempAlert_rqst_NotAvailable" 6 "BatteryTempAlert_rqst_Error" 5 "BatteryTempAlert_rqst_Spare3" 4 "BatteryTempAlert_rqst_Spare2" 3 "BatteryTempAlert_rqst_Spare1" 2 "BatteryTempAlert_rqst_CriticalAlertLowTemp" 1 "BatteryTempAlert_rqst_PreAlertLowTemp" 0 "BatteryTempAlert_rqst_NoAlertRequested" ;
VAL_ 2515322916 FPBRMMIStat_FPBRChangeAck_ISig_4 3 "Ack2Bit_NotAvailable" 2 "Ack2Bit_Error" 1 "Ack2Bit_ChangeAcknowledged" 0 "Ack2Bit_NoAction" ;
VAL_ 2515322916 FPBRMMIStat_FPBRStatusInd_ISig_4 3 "FPBRStatusInd_NotAvailable" 2 "FPBRStatusInd_Changing" 1 "FPBRStatusInd_On" 0 "FPBRStatusInd_Off" ;
VAL_ 2515322916 Trailer2TPMLostCom_ISig_4 3 "NoYes_NotAvailable" 2 "NoYes_Error" 1 "NoYes_Yes" 0 "NoYes_No" ;
VAL_ 2515321892 TPMMateTrailerResp_ISig_4 7 "TPMMateTrailerResp_NotAvailable" 6 "TPMMateTrailerResp_Error" 5 "TPMMateTrailerResp_Spare2" 4 "TPMMateTrailerResp_Spare1" 3 "TPMMateTrailerResp_MatedOK" 2 "TPMMateTrailerResp_Timeout" 1 "TPMMateTrailerResp_Progressing" 0 "TPMMateTrailerResp_NotActive" ;
VAL_ 2515321892 Trailer2TPMLeakageWarning_ISig_4 7 "TPMTireLeakageWarn_NotAvailable" 6 "TPMTireLeakageWarn_Error" 5 "TPMTireLeakageWarn_Spare3" 4 "TPMTireLeakageWarn_Spare2" 3 "TPMTireLeakageWarn_Spare1" 2 "TPMTireLeakageWarn_FastLeakageDetected" 1 "TPMTireLeakageWarn_SlowLeakageDetected" 0 "TPMTireLeakageWarn_NoLeakageDetected" ;
VAL_ 2515321892 TPMAutomaticMating_ISig_4 3 "ActiveStatus_NotAvailable" 2 "ActiveStatus_Error" 1 "ActiveStatus_Active" 0 "ActiveStatus_NotActive" ;
VAL_ 2515321892 Trailer2TPMMatedStatus_ISig_4 3 "NoMatedMated_NotAvailable" 2 "NoMatedMated_Error" 1 "NoMatedMated_Mated" 0 "NoMatedMated_NoMated" ;
VAL_ 2515321892 Trailer1TPMMatedStatus_ISig_4 3 "NoMatedMated_NotAvailable" 2 "NoMatedMated_Error" 1 "NoMatedMated_Mated" 0 "NoMatedMated_NoMated" ;
VAL_ 2515321892 TruckTPMLeakageWarning_ISig_4 7 "TPMTireLeakageWarn_NotAvailable" 6 "TPMTireLeakageWarn_Error" 5 "TPMTireLeakageWarn_Spare3" 4 "TPMTireLeakageWarn_Spare2" 3 "TPMTireLeakageWarn_Spare1" 2 "TPMTireLeakageWarn_FastLeakageDetected" 1 "TPMTireLeakageWarn_SlowLeakageDetected" 0 "TPMTireLeakageWarn_NoLeakageDetected" ;
VAL_ 2515321892 ExtraSideMarkers_FunctStat 3 "InactiveActive_NotAvailable" 2 "InactiveActive_Error" 1 "InactiveActive_Active" 0 "InactiveActive_Inactive" ;
VAL_ 2515321892 Trailer2TPMPressureWarning_ISig_ 7 "TPMPressureWarning_NotAvailable" 6 "TPMPressureWarning_Error" 5 "TPMPressureWarning_Spare" 4 "TPMPressureWarning_ExtremeUnderPressure" 3 "TPMPressureWarning_UnderPressure" 2 "TPMPressureWarning_NoWarningPressure" 1 "TPMPressureWarning_OverPressure" 0 "TPMPressureWarning_ExtremeOverPressure" ;
VAL_ 2515321892 TransferCaseNeutral_Ack 3 "TransferCaseNeutral_NotAvailable" 2 "TransferCaseNeutral_Error" 1 "TransferCaseNeutral_RequestConfirmed" 0 "TransferCaseNeutral_NoAction" ;
VAL_ 2515321892 Trailer1TPMPressureWarning_ISig_ 7 "TPMPressureWarning_NotAvailable" 6 "TPMPressureWarning_Error" 5 "TPMPressureWarning_Spare" 4 "TPMPressureWarning_ExtremeUnderPressure" 3 "TPMPressureWarning_UnderPressure" 2 "TPMPressureWarning_NoWarningPressure" 1 "TPMPressureWarning_OverPressure" 0 "TPMPressureWarning_ExtremeOverPressure" ;
VAL_ 2515321892 Trailer1TPMLeakageWarning_ISig_4 7 "TPMTireLeakageWarn_NotAvailable" 6 "TPMTireLeakageWarn_Error" 5 "TPMTireLeakageWarn_Spare3" 4 "TPMTireLeakageWarn_Spare2" 3 "TPMTireLeakageWarn_Spare1" 2 "TPMTireLeakageWarn_FastLeakageDetected" 1 "TPMTireLeakageWarn_SlowLeakageDetected" 0 "TPMTireLeakageWarn_NoLeakageDetected" ;
VAL_ 2515321892 LiftAxle1RequestResponse 15 "LiftAxleRequestResponse_NotAvailable" 14 "LiftAxleRequestResponse_Error" 13 "LiftAxleRequestResponse_Spare8" 12 "LiftAxleRequestResponse_Spare7" 11 "LiftAxleRequestResponse_Spare6" 10 "LiftAxleRequestResponse_Spare5" 9 "LiftAxleRequestResponse_Spare4" 8 "LiftAxleRequestResponse_Spare3" 7 "LiftAxleRequestResponse_Spare2" 6 "LiftAxleRequestResponse_Spare1" 5 "LiftAxleRequestResponse_LowerDeniedRASEC" 4 "LiftAxleRequestResponse_LiftDeniedVersatile" 3 "LiftAxleRequestResponse_LiftDeniedInterAxleClutchEngaged" 2 "LiftAxleRequestResponse_LiftDeniedRearOverload" 1 "LiftAxleRequestResponse_LiftDeniedFrontOverload" 0 "LiftAxleRequestResponse_NoIndication" ;
VAL_ 2515321892 TruckTPMPressureWarning_ISig_4 7 "TPMPressureWarning_NotAvailable" 6 "TPMPressureWarning_Error" 5 "TPMPressureWarning_Spare" 4 "TPMPressureWarning_ExtremeUnderPressure" 3 "TPMPressureWarning_UnderPressure" 2 "TPMPressureWarning_NoWarningPressure" 1 "TPMPressureWarning_OverPressure" 0 "TPMPressureWarning_ExtremeOverPressure" ;
VAL_ 2548840996 Trailer2TPMFailure_ISig_4 3 "InactiveActive_NotAvailable" 2 "InactiveActive_Error" 1 "InactiveActive_Active" 0 "InactiveActive_Inactive" ;
VAL_ 2548840996 TruckTPMTireInfo_Active_ISig_4 3 "TPMTireActive_NotAvailable" 2 "TPMTireActive_Error" 1 "TPMTireActive_TireActivePositioned" 0 "TPMTireActive_TireNotActive" ;
VAL_ 2548840996 TruckTPMFailure_ISig_4 3 "InactiveActive_NotAvailable" 2 "InactiveActive_Error" 1 "InactiveActive_Active" 0 "InactiveActive_Inactive" ;
VAL_ 2548840996 TruckTPMTireInfo_Battery_ISig_4 7 "TPMBatteryStatus_NotAvailable" 6 "TPMBatteryStatus_Error" 5 "TPMBatteryStatus_Spare3" 4 "TPMBatteryStatus_Spare2" 3 "TPMBatteryStatus_Spare1" 2 "TPMBatteryStatus_BatteryVeryLow" 1 "TPMBatteryStatus_BatteryLow" 0 "TPMBatteryStatus_BatteryOK" ;
VAL_ 2548840996 TPMTrailerPositionStat_ISig_4 3 "TrailerPositionsConfirmed_NotAvailable" 2 "TrailerPositionsConfirmed_Error" 1 "TPMTrailerPositionStat_TrailerPositionsConfirmed" 0 "TPMTrailerPositionStat_TrailerPositionsNotConfirmed" ;
VAL_ 2548840996 Trailer1TPMFailure_ISig_4 3 "InactiveActive_NotAvailable" 2 "InactiveActive_Error" 1 "InactiveActive_Active" 0 "InactiveActive_Inactive" ;
VAL_ 2548840996 TruckTPMTireInfo_PresWarn_ISig_4 7 "TPMPressureWarning_NotAvailable" 6 "TPMPressureWarning_Error" 5 "TPMPressureWarning_Spare" 4 "TPMPressureWarning_ExtremeUnderPressure" 3 "TPMPressureWarning_UnderPressure" 2 "TPMPressureWarning_NoWarningPressure" 1 "TPMPressureWarning_OverPressure" 0 "TPMPressureWarning_ExtremeOverPressure" ;
VAL_ 2548840996 TruckTPMTireInfo_LeakageWarn_ISi 7 "TPMTireLeakageWarn_NotAvailable" 6 "TPMTireLeakageWarn_Error" 5 "TPMTireLeakageWarn_Spare3" 4 "TPMTireLeakageWarn_Spare2" 3 "TPMTireLeakageWarn_Spare1" 2 "TPMTireLeakageWarn_FastLeakageDetected" 1 "TPMTireLeakageWarn_SlowLeakageDetected" 0 "TPMTireLeakageWarn_NoLeakageDetected" ;
VAL_ 2548836388 Trailer2TPMTireInfo_LeakageWarn_ 7 "TPMTireLeakageWarn_NotAvailable" 6 "TPMTireLeakageWarn_Error" 5 "TPMTireLeakageWarn_Spare3" 4 "TPMTireLeakageWarn_Spare2" 3 "TPMTireLeakageWarn_Spare1" 2 "TPMTireLeakageWarn_FastLeakageDetected" 1 "TPMTireLeakageWarn_SlowLeakageDetected" 0 "TPMTireLeakageWarn_NoLeakageDetected" ;
VAL_ 2548836388 Trailer2TPMTireInfo_PresWarn_ISi 7 "TPMPressureWarning_NotAvailable" 6 "TPMPressureWarning_Error" 5 "TPMPressureWarning_Spare" 4 "TPMPressureWarning_ExtremeUnderPressure" 3 "TPMPressureWarning_UnderPressure" 2 "TPMPressureWarning_NoWarningPressure" 1 "TPMPressureWarning_OverPressure" 0 "TPMPressureWarning_ExtremeOverPressure" ;
VAL_ 2548836388 Trailer2TPMTireInfo_Battery_ISig 7 "TPMBatteryStatus_NotAvailable" 6 "TPMBatteryStatus_Error" 5 "TPMBatteryStatus_Spare3" 4 "TPMBatteryStatus_Spare2" 3 "TPMBatteryStatus_Spare1" 2 "TPMBatteryStatus_BatteryVeryLow" 1 "TPMBatteryStatus_BatteryLow" 0 "TPMBatteryStatus_BatteryOK" ;
VAL_ 2548836388 Trailer2TPMTireInfo_Active_ISig_ 3 "TPMTireActive_NotAvailable" 2 "TPMTireActive_Error" 1 "TPMTireActive_TireActivePositioned" 0 "TPMTireActive_TireNotActive" ;
VAL_ 2548835620 Trailer1TPMTireInfo_Battery_ISig 7 "TPMBatteryStatus_NotAvailable" 6 "TPMBatteryStatus_Error" 5 "TPMBatteryStatus_Spare3" 4 "TPMBatteryStatus_Spare2" 3 "TPMBatteryStatus_Spare1" 2 "TPMBatteryStatus_BatteryVeryLow" 1 "TPMBatteryStatus_BatteryLow" 0 "TPMBatteryStatus_BatteryOK" ;
VAL_ 2548835620 Trailer1TPMTireInfo_PresWarn_ISi 7 "TPMPressureWarning_NotAvailable" 6 "TPMPressureWarning_Error" 5 "TPMPressureWarning_Spare" 4 "TPMPressureWarning_ExtremeUnderPressure" 3 "TPMPressureWarning_UnderPressure" 2 "TPMPressureWarning_NoWarningPressure" 1 "TPMPressureWarning_OverPressure" 0 "TPMPressureWarning_ExtremeOverPressure" ;
VAL_ 2548835620 Trailer1TPMTireInfo_LeakageWarn_ 7 "TPMTireLeakageWarn_NotAvailable" 6 "TPMTireLeakageWarn_Error" 5 "TPMTireLeakageWarn_Spare3" 4 "TPMTireLeakageWarn_Spare2" 3 "TPMTireLeakageWarn_Spare1" 2 "TPMTireLeakageWarn_FastLeakageDetected" 1 "TPMTireLeakageWarn_SlowLeakageDetected" 0 "TPMTireLeakageWarn_NoLeakageDetected" ;
VAL_ 2548835620 TPMPosOfWMResp_VehiclePos_ISig_4 7 "TPMVehiclePos_NotAvailable" 6 "TPMVehiclePos_Error" 5 "TPMVehiclePos_Trailer5Vehicle" 4 "TPMVehiclePos_Trailer4Vehicle" 3 "TPMVehiclePos_Trailer3Vehicle" 2 "TPMVehiclePos_Trailer2Vehicle" 1 "TPMVehiclePos_Trailer1Vehicle" 0 "TPMVehiclePos_TruckVehicle" ;
VAL_ 2548835620 Trailer1TPMTireInfo_Active_ISig_ 3 "TPMTireActive_NotAvailable" 2 "TPMTireActive_Error" 1 "TPMTireActive_TireActivePositioned" 0 "TPMTireActive_TireNotActive" ;
VAL_ 2548835620 TPMPosOfWMResp_Status_ISig_4 7 "TPMPosStatusResp_NotAvailable" 6 "TPMPosStatusResp_Error" 5 "TPMPosStatusResp_Spare2" 4 "TPMPosStatusResp_Spare1" 3 "TPMPosStatusResp_PositionedOK" 2 "TPMPosStatusResp_Timeout" 1 "TPMPosStatusResp_Progressing" 0 "TPMPosStatusResp_NotActive" ;
VAL_ 2566358564 TruckTPMAxlTireCfg_Axle2_ISig_4 7 "TPMAxleConfig_NotAvailable" 6 "TPMAxleConfig_Error" 5 "TPMAxleConfig_Spare" 4 "TPMAxleConfig_RearAxleWith4Tires" 3 "TPMAxleConfig_RearAxleWith2Tires" 2 "TPMAxleConfig_FrontAxleWith4Tires" 1 "TPMAxleConfig_FrontAxleWith2Tires" 0 "TPMAxleConfig_NotPresent" ;
VAL_ 2566358564 TruckTPMAxlTireCfg_Axle1_ISig_4 7 "TPMAxleConfig_NotAvailable" 6 "TPMAxleConfig_Error" 5 "TPMAxleConfig_Spare" 4 "TPMAxleConfig_RearAxleWith4Tires" 3 "TPMAxleConfig_RearAxleWith2Tires" 2 "TPMAxleConfig_FrontAxleWith4Tires" 1 "TPMAxleConfig_FrontAxleWith2Tires" 0 "TPMAxleConfig_NotPresent" ;
VAL_ 2566358564 TruckTPMAxlTireCfg_Axle5_ISig_4 7 "TPMAxleConfig_NotAvailable" 6 "TPMAxleConfig_Error" 5 "TPMAxleConfig_Spare" 4 "TPMAxleConfig_RearAxleWith4Tires" 3 "TPMAxleConfig_RearAxleWith2Tires" 2 "TPMAxleConfig_FrontAxleWith4Tires" 1 "TPMAxleConfig_FrontAxleWith2Tires" 0 "TPMAxleConfig_NotPresent" ;
VAL_ 2566358564 TruckTPMAxlTireCfg_Axle4_ISig_4 7 "TPMAxleConfig_NotAvailable" 6 "TPMAxleConfig_Error" 5 "TPMAxleConfig_Spare" 4 "TPMAxleConfig_RearAxleWith4Tires" 3 "TPMAxleConfig_RearAxleWith2Tires" 2 "TPMAxleConfig_FrontAxleWith4Tires" 1 "TPMAxleConfig_FrontAxleWith2Tires" 0 "TPMAxleConfig_NotPresent" ;
VAL_ 2566358564 TruckTPMThresCfg_AxleNr_ISig_4 7 "TPMAxleNr_NotAvailable" 6 "TPMAxleNr_Error" 5 "TPMAxleNr_Axle5" 4 "TPMAxleNr_Axle4" 3 "TPMAxleNr_Axle3" 2 "TPMAxleNr_Axle2" 1 "TPMAxleNr_Axle1" 0 "TPMAxleNr_NoRequest" ;
VAL_ 2566358564 TruckTPMAxlTireCfg_Axle3_ISig_4 7 "TPMAxleConfig_NotAvailable" 6 "TPMAxleConfig_Error" 5 "TPMAxleConfig_Spare" 4 "TPMAxleConfig_RearAxleWith4Tires" 3 "TPMAxleConfig_RearAxleWith2Tires" 2 "TPMAxleConfig_FrontAxleWith4Tires" 1 "TPMAxleConfig_FrontAxleWith2Tires" 0 "TPMAxleConfig_NotPresent" ;
VAL_ 2566358052 Trailer2TPMType_ISig_4 3 "TPMTrailerType_NotAvailable" 2 "TPMTrailerType_Error" 1 "TPMTrailerType_ISO11992Trailer" 0 "TPMTrailerType_SKFWirelessTrailer" ;
VAL_ 2566358052 Trailer2TPMAxlTireCfg_Axle1_ISig 7 "TPMAxleConfig_NotAvailable" 6 "TPMAxleConfig_Error" 5 "TPMAxleConfig_Spare" 4 "TPMAxleConfig_RearAxleWith4Tires" 3 "TPMAxleConfig_RearAxleWith2Tires" 2 "TPMAxleConfig_FrontAxleWith4Tires" 1 "TPMAxleConfig_FrontAxleWith2Tires" 0 "TPMAxleConfig_NotPresent" ;
VAL_ 2566358052 Trailer2TPMAxlTireCfg_Axle3_ISig 7 "TPMAxleConfig_NotAvailable" 6 "TPMAxleConfig_Error" 5 "TPMAxleConfig_Spare" 4 "TPMAxleConfig_RearAxleWith4Tires" 3 "TPMAxleConfig_RearAxleWith2Tires" 2 "TPMAxleConfig_FrontAxleWith4Tires" 1 "TPMAxleConfig_FrontAxleWith2Tires" 0 "TPMAxleConfig_NotPresent" ;
VAL_ 2566358052 Trailer2TPMAxlTireCfg_Axle2_ISig 7 "TPMAxleConfig_NotAvailable" 6 "TPMAxleConfig_Error" 5 "TPMAxleConfig_Spare" 4 "TPMAxleConfig_RearAxleWith4Tires" 3 "TPMAxleConfig_RearAxleWith2Tires" 2 "TPMAxleConfig_FrontAxleWith4Tires" 1 "TPMAxleConfig_FrontAxleWith2Tires" 0 "TPMAxleConfig_NotPresent" ;
VAL_ 2566358052 Trailer2TPMAxlTireCfg_Axle5_ISig 7 "TPMAxleConfig_NotAvailable" 6 "TPMAxleConfig_Error" 5 "TPMAxleConfig_Spare" 4 "TPMAxleConfig_RearAxleWith4Tires" 3 "TPMAxleConfig_RearAxleWith2Tires" 2 "TPMAxleConfig_FrontAxleWith4Tires" 1 "TPMAxleConfig_FrontAxleWith2Tires" 0 "TPMAxleConfig_NotPresent" ;
VAL_ 2566358052 Trailer2TPMAxlTireCfg_Axle4_ISig 7 "TPMAxleConfig_NotAvailable" 6 "TPMAxleConfig_Error" 5 "TPMAxleConfig_Spare" 4 "TPMAxleConfig_RearAxleWith4Tires" 3 "TPMAxleConfig_RearAxleWith2Tires" 2 "TPMAxleConfig_FrontAxleWith4Tires" 1 "TPMAxleConfig_FrontAxleWith2Tires" 0 "TPMAxleConfig_NotPresent" ;
VAL_ 2566358052 Trailer2TPMThresCfg_AxleNr_ISig_ 7 "TPMAxleNr_NotAvailable" 6 "TPMAxleNr_Error" 5 "TPMAxleNr_Axle5" 4 "TPMAxleNr_Axle4" 3 "TPMAxleNr_Axle3" 2 "TPMAxleNr_Axle2" 1 "TPMAxleNr_Axle1" 0 "TPMAxleNr_NoRequest" ;
VAL_ 2566357540 Trailer1TPMAxlTireCfg_Axle1_ISig 7 "TPMAxleConfig_NotAvailable" 6 "TPMAxleConfig_Error" 5 "TPMAxleConfig_Spare" 4 "TPMAxleConfig_RearAxleWith4Tires" 3 "TPMAxleConfig_RearAxleWith2Tires" 2 "TPMAxleConfig_FrontAxleWith4Tires" 1 "TPMAxleConfig_FrontAxleWith2Tires" 0 "TPMAxleConfig_NotPresent" ;
VAL_ 2566357540 Trailer1TPMAxlTireCfg_Axle2_ISig 7 "TPMAxleConfig_NotAvailable" 6 "TPMAxleConfig_Error" 5 "TPMAxleConfig_Spare" 4 "TPMAxleConfig_RearAxleWith4Tires" 3 "TPMAxleConfig_RearAxleWith2Tires" 2 "TPMAxleConfig_FrontAxleWith4Tires" 1 "TPMAxleConfig_FrontAxleWith2Tires" 0 "TPMAxleConfig_NotPresent" ;
VAL_ 2566357540 Trailer1TPMAxlTireCfg_Axle5_ISig 7 "TPMAxleConfig_NotAvailable" 6 "TPMAxleConfig_Error" 5 "TPMAxleConfig_Spare" 4 "TPMAxleConfig_RearAxleWith4Tires" 3 "TPMAxleConfig_RearAxleWith2Tires" 2 "TPMAxleConfig_FrontAxleWith4Tires" 1 "TPMAxleConfig_FrontAxleWith2Tires" 0 "TPMAxleConfig_NotPresent" ;
VAL_ 2566357540 Trailer1TPMType_ISig_4 3 "TPMTrailerType_NotAvailable" 2 "TPMTrailerType_Error" 1 "TPMTrailerType_ISO11992Trailer" 0 "TPMTrailerType_SKFWirelessTrailer" ;
VAL_ 2566357540 Trailer1TPMThresCfg_AxleNr_ISig_ 7 "TPMAxleNr_NotAvailable" 6 "TPMAxleNr_Error" 5 "TPMAxleNr_Axle5" 4 "TPMAxleNr_Axle4" 3 "TPMAxleNr_Axle3" 2 "TPMAxleNr_Axle2" 1 "TPMAxleNr_Axle1" 0 "TPMAxleNr_NoRequest" ;
VAL_ 2566357540 MaintResetFailureCause 31 "MaintResetFailureCause_NotAvailable" 30 "MaintResetFailureCause_Error" 29 "MaintResetFailureCause_Cond_29_Specific" 28 "MaintResetFailureCause_Cond_28_Specific" 27 "MaintResetFailureCause_Cond_27_Specific" 26 "MaintResetFailureCause_Cond_26_Specific" 25 "MaintResetFailureCause_Cond_25_Specific" 24 "MaintResetFailureCause_Cond_24_Specific" 23 "MaintResetFailureCause_Cond_23_Specific" 22 "MaintResetFailureCause_Cond_22_Specific" 21 "MaintResetFailureCause_Cond_21_Specific" 20 "MaintResetFailureCause_Cond_20_Specific" 19 "MaintResetFailureCause_Cond_19_Specific" 18 "MaintResetFailureCause_Cond_18_Specific" 17 "MaintResetFailureCause_Cond_17_Specific" 16 "MaintResetFailureCause_Cond_16_Specific" 15 "MaintResetFailureCause_Cond_15_Specific" 14 "MaintResetFailureCause_Cond_14_Specific" 13 "MaintResetFailureCause_Cond_13_Specific" 12 "MaintResetFailureCause_Cond_12_Specific" 11 "MaintResetFailureCause_Cond_11_Specific" 10 "MaintResetFailureCause_Cond_10_Specific" 9 "MaintResetFailureCause_Cond_09_Spare4" 8 "MaintResetFailureCause_Cond_08_Spare3" 7 "MaintResetFailureCause_Cond_07_Spare2" 6 "MaintResetFailureCause_Cond_06_Spare1" 5 "MaintResetFailureCause_Cond_05_InvalidSelection" 4 "MaintResetFailureCause_Cond_04_ComponentResetTimeOut" 3 "MaintResetFailureCause_Cond_03_RejectedByComponent" 2 "MaintResetFailureCause_Cond_02_InvalidDateTime" 1 "MaintResetFailureCause_Cond_01_InvalidEngineTime" 0 "MaintResetFailureCause_Cond_00_InvalidVehicleDistance" ;
VAL_ 2566357540 Trailer1TPMAxlTireCfg_Axle4_ISig 7 "TPMAxleConfig_NotAvailable" 6 "TPMAxleConfig_Error" 5 "TPMAxleConfig_Spare" 4 "TPMAxleConfig_RearAxleWith4Tires" 3 "TPMAxleConfig_RearAxleWith2Tires" 2 "TPMAxleConfig_FrontAxleWith4Tires" 1 "TPMAxleConfig_FrontAxleWith2Tires" 0 "TPMAxleConfig_NotPresent" ;
VAL_ 2566357540 Trailer1TPMAxlTireCfg_Axle3_ISig 7 "TPMAxleConfig_NotAvailable" 6 "TPMAxleConfig_Error" 5 "TPMAxleConfig_Spare" 4 "TPMAxleConfig_RearAxleWith4Tires" 3 "TPMAxleConfig_RearAxleWith2Tires" 2 "TPMAxleConfig_FrontAxleWith4Tires" 1 "TPMAxleConfig_FrontAxleWith2Tires" 0 "TPMAxleConfig_NotPresent" ;
VAL_ 2566357028 FuseAndRelayFault_TypeD 7 "FuseRelayType_NotAvailable" 6 "FuseRelayType_Error" 5 "FuseRelayType_Spare" 4 "FuseRelayType_12VNetwork" 3 "FuseRelayType_FuseOrRelay" 2 "FuseRelayType_Relay" 1 "FuseRelayType_Fuse" 0 "FuseRelayType_NoFault" ;
VAL_ 2566357028 FuseAndRelayFault_TypeB 7 "FuseRelayType_NotAvailable" 6 "FuseRelayType_Error" 5 "FuseRelayType_Spare" 4 "FuseRelayType_12VNetwork" 3 "FuseRelayType_FuseOrRelay" 2 "FuseRelayType_Relay" 1 "FuseRelayType_Fuse" 0 "FuseRelayType_NoFault" ;
VAL_ 2566357028 FuseAndRelayFault_TypeA 7 "FuseRelayType_NotAvailable" 6 "FuseRelayType_Error" 5 "FuseRelayType_Spare" 4 "FuseRelayType_12VNetwork" 3 "FuseRelayType_FuseOrRelay" 2 "FuseRelayType_Relay" 1 "FuseRelayType_Fuse" 0 "FuseRelayType_NoFault" ;
VAL_ 2566357028 FuseAndRelayFault_TypeC 7 "FuseRelayType_NotAvailable" 6 "FuseRelayType_Error" 5 "FuseRelayType_Spare" 4 "FuseRelayType_12VNetwork" 3 "FuseRelayType_FuseOrRelay" 2 "FuseRelayType_Relay" 1 "FuseRelayType_Fuse" 0 "FuseRelayType_NoFault" ;
VAL_ 2548897828 FogLight_Front_cmd_ISig_4 3 "InactiveActive_NotAvailable" 2 "InactiveActive_Error" 1 "InactiveActive_Active" 0 "InactiveActive_Inactive" ;
VAL_ 2548897060 BatterySOCAlertRawData_rqst_ISig 7 "BatterySOCAlert_rqst_NotAvailable" 6 "BatterySOCAlert_rqst_ErrorIndicator" 5 "BatterySOCAlert_rqst_SpareValue_02" 4 "BatterySOCAlert_rqst_SpareValue_01" 3 "BatterySOCAlert_rqst_SpareValue" 2 "BatterySOCAlert_rqst_CriticalAlert" 1 "BatterySOCAlert_rqst_PreAlert" 0 "BatterySOCAlert_rqst_NoAlertRequested" ;
VAL_ 2548897060 ShortStopHeater_status_ISig_4 7 "ShortStopHeaterStatus_NotAvailable" 6 "ShortStopHeaterStatus_Error" 5 "ShortStopHeaterStatus_Spare3" 4 "ShortStopHeaterStatus_Spare2" 3 "ShortStopHeaterStatus_Spare1" 2 "ShortStopHeaterStatus_ActivatedAndPumpNotEngaged" 1 "ShortStopHeaterStatus_ActivatedAndPumpEngaged" 0 "ShortStopHeaterStatus_NotActivated" ;
VAL_ 2548897060 LivBatDisconnectDetectStat_ISig_ 3 "LivBatDisconnectDetectStat_Not_Available" 2 "LivBatDisconnectDetectStat_Error" 1 "LivBatDisconnectDetectStat_Battery_Disconnected" 0 "LivBatDisconnectDetectStat_Battery_NotDisconnected" ;
VAL_ 2515845117 ReducedLoadMode_stat_ISig_4 3 "ReducedLoadMode_stat_NotAvailable" 2 "ReducedLoadMode_stat_Error" 1 "ReducedLoadMode_stat_ReducedLoadMode" 0 "ReducedLoadMode_stat_NormalMode" ;
VAL_ 2515845117 BatterySOCAlert_rqst_ISig_4 7 "BatterySOCAlert_rqst_NotAvailable" 6 "BatterySOCAlert_rqst_ErrorIndicator" 5 "BatterySOCAlert_rqst_SpareValue_02" 4 "BatterySOCAlert_rqst_SpareValue_01" 3 "BatterySOCAlert_rqst_SpareValue" 2 "BatterySOCAlert_rqst_CriticalAlert" 1 "BatterySOCAlert_rqst_PreAlert" 0 "BatterySOCAlert_rqst_NoAlertRequested" ;
SIG_GROUP_ 2566078244 FrontConspicLamp_stat_sg_ISig_4 1 : FrontConspicLamp_stat_HiLeft_ISi FrontConspicLamp_stat_LoRight_IS FrontConspicLamp_stat_LoLeft_ISi FrontConspicLamp_stat_HiRight_IS;
SIG_GROUP_ 2481984804 InstFuel_sg_ISig_4 1 : InstFuel_ConsumpValue_ISig_4 InstFuel_VehicleMoving_ISig_4;
SIG_GROUP_ 2516006692 EngOvrrideCtrlStat_sg 1 : EngOvrrideCtrlStat_FireTruckMode EngOvrrideCtrlStat_StartOvrrMode EngOvrrideCtrlStat_ProtOvrrMode;
SIG_GROUP_ 2515322916 FPBRMMIStat_sg_ISig_4 1 : FPBRMMIStat_FPBRChangeAck_ISig_4 FPBRMMIStat_FPBRStatusInd_ISig_4;
SIG_GROUP_ 2548840996 TruckTPMTireInfo_sg_ISig_4 1 : TruckTPMTireInfo_Active_ISig_4 TruckTPMTireInfo_TireId_ISig_4 TruckTPMTireInfo_Battery_ISig_4 TruckTPMTireInfo_Temperature_ISi TruckTPMTireInfo_RefPres_ISig_4 TruckTPMTireInfo_Pressure_ISig_4 TruckTPMTireInfo_PresWarn_ISig_4 TruckTPMTireInfo_LeakageWarn_ISi;
SIG_GROUP_ 2548836388 Trailer2TPMTireInfo_sg_ISig_4 1 : Trailer2TPMTireInfo_LeakageWarn_ Trailer2TPMTireInfo_RefPres_ISig Trailer2TPMTireInfo_PresWarn_ISi Trailer2TPMTireInfo_Pressure_ISi Trailer2TPMTireInfo_Temperature_ Trailer2TPMTireInfo_TireId_ISig_ Trailer2TPMTireInfo_Battery_ISig Trailer2TPMTireInfo_Active_ISig_;
SIG_GROUP_ 2548835620 TPMPosOfWMResp_sg_ISig_4 1 : TPMPosOfWMResp_VehiclePos_ISig_4 TPMPosOfWMResp_Status_ISig_4 TPMPosOfWMResp_TireId_ISig_4;
SIG_GROUP_ 2548835620 Trailer1TPMTireInfo_sg_ISig_4 1 : Trailer1TPMTireInfo_Battery_ISig Trailer1TPMTireInfo_Pressure_ISi Trailer1TPMTireInfo_PresWarn_ISi Trailer1TPMTireInfo_LeakageWarn_ Trailer1TPMTireInfo_TireId_ISig_ Trailer1TPMTireInfo_RefPres_ISig Trailer1TPMTireInfo_Temperature_ Trailer1TPMTireInfo_Active_ISig_;
SIG_GROUP_ 2566358564 TruckTPMAxlTireCfg_sg_ISig_4 1 : TruckTPMAxlTireCfg_Axle2_ISig_4 TruckTPMAxlTireCfg_Axle1_ISig_4 TruckTPMAxlTireCfg_Axle5_ISig_4 TruckTPMAxlTireCfg_Axle4_ISig_4 TruckTPMAxlTireCfg_Axle3_ISig_4;
SIG_GROUP_ 2566358564 TruckTPMThresCfg_sg_ISig_4 1 : TruckTPMThresCfg_OverPres_ISig_4 TruckTPMThresCfg_ExtUnderPres_IS TruckTPMThresCfg_AxleNr_ISig_4 TruckTPMThresCfg_UnderPres_ISig_ TruckTPMThresCfg_ExtOverPres_ISi;
SIG_GROUP_ 2566358052 Trailer2TPMAxlTireCfg_sg_ISig_4 1 : Trailer2TPMAxlTireCfg_Axle1_ISig Trailer2TPMAxlTireCfg_Axle3_ISig Trailer2TPMAxlTireCfg_Axle2_ISig Trailer2TPMAxlTireCfg_Axle5_ISig Trailer2TPMAxlTireCfg_Axle4_ISig;
SIG_GROUP_ 2566358052 Trailer2TPMThresCfg_sg_ISig_4 1 : Trailer2TPMThresCfg_OverPres_ISi Trailer2TPMThresCfg_AxleNr_ISig_ Trailer2TPMThresCfg_ExtOverPres_ Trailer2TPMThresCfg_UnderPres_IS Trailer2TPMThresCfg_ExtUnderPres;
SIG_GROUP_ 2566357540 Trailer1TPMAxlTireCfg_sg_ISig_4 1 : Trailer1TPMAxlTireCfg_Axle1_ISig Trailer1TPMAxlTireCfg_Axle2_ISig Trailer1TPMAxlTireCfg_Axle5_ISig Trailer1TPMAxlTireCfg_Axle4_ISig Trailer1TPMAxlTireCfg_Axle3_ISig;
SIG_GROUP_ 2566357540 Trailer1TPMThresCfg_sg_ISig_4 1 : Trailer1TPMThresCfg_ExtOverPres_ Trailer1TPMThresCfg_OverPres_ISi Trailer1TPMThresCfg_UnderPres_IS Trailer1TPMThresCfg_ExtUnderPres Trailer1TPMThresCfg_AxleNr_ISig_;
SIG_GROUP_ 2566357028 FuseAndRelayFault_sg 1 : FuseAndRelayFault_ItemNoD2 FuseAndRelayFault_ItemNoD1 FuseAndRelayFault_ItemNoC2 FuseAndRelayFault_ItemNoB2 FuseAndRelayFault_TypeD FuseAndRelayFault_TypeB FuseAndRelayFault_TypeA FuseAndRelayFault_ItemNoA1 FuseAndRelayFault_ItemNoA2 FuseAndRelayFault_ItemNoB1 FuseAndRelayFault_ItemNoC1 FuseAndRelayFault_TypeC;
SIG_GROUP_ 2566365476 MaintService_sg_ISig_4_18f7a124 1 : MaintService_ServiceCalendarTime MaintService_EngTimeID_ISig_4_18 MaintService_DistID_ISig_4_18f7a MaintService_ServiceDistance_ISi MaintService_ServiceEngineTime_I MaintService_CalDateID_ISig_4_18;
SIG_GROUP_ 2566357284 MaintService_sg_ISig_4_18f78124 1 : MaintService_ServiceEngineT_0000 MaintService_EngTimeID_ISig_0000 MaintService_DistID_ISig_4_18f78 MaintService_ServiceDistanc_0000 MaintService_CalDateID_ISig_0000 MaintService_ServiceCalenda_0000;
